VERSION "HNNBNNNYNNNNNNNNNNNNNNNNNNNNNNNNNNNNNNNNNN/4/%%%/4/'%**4NNN///"

NS_ :

BS_:

BU_: A03_ETC C07_BAT H42_HRB H51_STACK H62_HLD E71_DCDC E74_ISOHV S91_FCCU1 S92_FCCU2 S93_FCCU3 S94_FCCU4 S80_BP LABVIEW S83_DCO
VAL_TABLE_ motorState 5 "MOT_numStates" 4 "MOT_RPM_REGULATED" 3 "MOT_PREPARE" 2 "MOT_STOPPED" 1 "MOT_ERROR" 0 "MOT_INIT" ;
VAL_TABLE_ HRB_Status 8 "external operated" 7 "Error" 6 "Heater active" 5 "Blocked" 4 "Running" 3 "Start" 2 "Waiting for start" 1 "Selftest" 0 "Init" ;
VAL_TABLE_ BAT_Status 0 "STANDBY" 1 "SERVICE" 2 "DISCHARGE" 3 "CHARGE" 4 "ERROR" 5 "PRECHARGE_LOAD" 6 "PRECHARGE_CHARGER" 7 "REVERSE_CHARGE" ;
VAL_TABLE_ DCDC_Status 0 "BOOT UP" 4 "STOPPED" 5 "OPERATIONAL" 127 "PRE-OPERATIONAL" ;
VAL_TABLE_ DCDC_Function 1 "Enter Operational" 2 "Enter Stop" 128 "Enter Pre-Operational" 129 "Reset Node" 130 "Reset Communication" ;
VAL_TABLE_ ETC_Status 0 "Initializing" 1 "Ready" 2 "Running" 3 "Degraded Operation" 4 "Blocked" ;
VAL_TABLE_ ETC_Baudrate 1 "20 kbps" 2 "50 kbps" 3 "100 kbps" 4 "125 kbps" 5 "250 kbps" 6 "500 kbps" 8 "1000 kbps" ;
VAL_TABLE_ ETC_Mode 0 "HV Input" 1 "LV Input" ;
VAL_TABLE_ ETC_Info 0 "Article Number" 1 "Article Revision" 2 "SerialNumber Part 1" 3 "SerialNumber Part 2" 4 "SerialNumber Part 3" 5 "Firmware Revision" 6 "Bootloader Version" 255 "Unknown" ;
VAL_TABLE_ ETC_Diag 0 "Gas Bearing Condition" ;
VAL_TABLE_ ISOHV_Cmd 33 "S_IMC_CTL_SELFTEST" 200 "S_VIFC_CTL_IMC_RESET" 202 "S_VIFC_CTL_LOCK" 203 "S_VIFC_CTL_MEASUREMENT" 40 "S_IMC_SET_R_ISO_ERR_THR" 41 "S_IMC_SET_R_ISO_WRN_THR" 43 "S_IMC_SET_MEAN_FACTOR" 210 "S_VIFC_SET_HV_RELAIS" 0 "S_VIFC_DUMMY" 55 "S_IMC_GET_STATUS" 53 "S_IMC_GET_R_ISO" 50 "S_IMC_GET_R_ISO_ERR_THR" 57 "S_IMC_GET_R_ISO_WRN_THR" 60 "S_IMC_GET_MEAN_FACTOR" 54 "S_IMC_GET_HV_1" 58 "S_IMC_GET_HV_2" 51 "S_IMC_GET_VERSION" 220 "S_VIFC_GET_STATUS" 221 "S_VIFC_GET_HV_RELAIS" 222 "S_VIFC_GET_VERSION" 90 "S_IMC_GET_TEST_CNT" 61 "S_IMC_GET_MANUFACTURER" 255 "ERROR" ;
VAL_TABLE_ ISOHV_D_IMC_SELFTEST_SCR 0 "Keine Maßnahme" 1 "OverAll Szenario" 2 "ParameterConfig-Szenario" ;
VAL_TABLE_ ISOHV_D_IMC_R_ISO_BIAS 0 "nicht bekannt" 1 "Fehler an HV1_NEG" 2 "Fehler an HV1_POS" ;
VAL_TABLE_ ISOHV_D_IMC_VERSION_INDEX 0 "IMC Bootloader" 1 "IMC Firmware" 2 "IMC Firmware ID" 3 "IMC Firmware Hash" ;
VAL_TABLE_ ISOHV_D_VIFC_HV_RELAIS 0 "HV_1_NEG-Relais" 1 "HV_1_POS-Relais" 100 "unbekannt" ;
VAL_TABLE_ ISOHV_D_VIFC_LOCK_MODE 0 "Entriegelt" 1 "Verriegelt" 100 "unbekannt" ;
VAL_TABLE_ ISOHV_D_VIFC_LOCK_PWD 0 "Entriegeln" 65535 "Verriegeln" ;
VAL_TABLE_ ISOHV_D_VIFC_HV_RELAIS_STATE 0 "Offen" 1 "Geschlossen" 100 "unbekannt" ;
VAL_TABLE_ ISOHV_D_VIFC_VERSION_INDEX 0 "VIFC-Bootloader" 1 "VIFC-Firmware" 100 "unbekannt" ;
VAL_TABLE_ ISOHV_D_VIFC_IMC_ALIVE 0 "In Betrieb" 1 "Fehler" 2 "Leistungsfehler" 100 "unbekannt" ;
VAL_TABLE_ ISOHV_D_IMD_ERROR_CODE 32 "Timeout 10 ms" 33 "Checksummen-Fehler" 34 "Ungültiger Parameter" 35 "Unbekannter Befehl" 36 "Fehler im EEPROM-Zugang" 37 "Wdh oder fehlender Datenframe" 1000 "Befehl gesperrt" 1001 "Warteschlange voll" 1002 "Befehl nicht verfügbar" 1032 "Timeout 10 ms" 1033 "Checksummen-Fehler" 1034 "Ungültiger Parameter" 1035 "Unbekannter Befehl" 1037 "Wdh oder fehlender Datenframe" 1038 "Keine Antwort" 1039 "Kommunikationsfehler" 1040 "Ungültiger IMC-Antwortbefehl" ;
VAL_TABLE_ RADIATOR_STATUS 0 "Radiator OK" 1 "Radiator ERROR" ;
VAL_TABLE_ STACK_CVM_STATUS 0 "Startup" 16 "Initializing" 32 "Configuration" 48 "Wait for Configuration" 64 "Adressing Slaves" 80 "Idle" 96 "BMS Monitoring Startup" 112 "BMS Monitoring Normal" 240 "Stopped" 254 "Undefined" 255 "Error" ;
VAL_TABLE_ STACK_CONFIG 0 "DateTime" 1 "CoreData_Frequency" 2 "StackSize" 3 "CAN_Resistor" 4 "MasterNo" 5 "Lower_Limit2" 6 "Upper_Limit1" 7 "Upper_Limit2" 8 "Diff_MaxMin_Limit" 9 "AmountOfModules" 10 "CellsPerModule" 11 "PosAtStack" 12 "Temperature" ;
VAL_TABLE_ AIR_THROTTLE 0 "OFF" 1 "ON" 2 "TeachIn" 3 "Error" ;

BO_ 80 A03_FCCU1_ETC_Setpoint: 8 S91_FCCU1
 SG_ A03_ETC_a_opCmd1_Start_Stop : 0|1@0+ (1,0) [0|1] ""  A03_ETC,S83_DCO,LABVIEW
 SG_ A03_ETC_a_opCmd1_Error_Ack : 1|1@0+ (1,0) [0|1] ""  A03_ETC,S83_DCO,LABVIEW
 SG_ A03_ETC_a_opCmd2 : 8|1@0+ (1,0) [0|255] ""  A03_ETC,S83_DCO,LABVIEW
 SG_ A03_ETC_a_Speed_Set : 39|32@0- (1,0) [-2147483648|2147483647] "rpm"  A03_ETC,S83_DCO,LABVIEW

BO_ 84 A03_FCCU1_ETC_CAN_Setting: 8 S91_FCCU1
 SG_ A03_ETC_a_CAN_Set_Broadcast : 0|1@0+ (1,0) [0|1] ""  A03_ETC,S83_DCO,LABVIEW
 SG_ A03_ETC_a_CAN_Set_Termination : 1|1@0+ (1,0) [0|1] ""  A03_ETC,S83_DCO,LABVIEW
 SG_ A03_ETC_a_CAN_Set_Timeout : 2|1@0+ (1,0) [0|1] ""  A03_ETC,S83_DCO,LABVIEW
 SG_ A03_ETC_a_CAN_Set_Timeout_Dur : 15|8@0+ (0.1,0) [0.1|25.5] "s"  A03_ETC,S83_DCO,LABVIEW
 SG_ A03_ETC_a_CAN_Set_Baudrate : 23|8@0+ (1,0) [0|255] ""  A03_ETC,S83_DCO,LABVIEW
 SG_ A03_ETC_a_CAN_Set_ID_Offset : 39|32@0+ (1,0) [1|536869886] ""  A03_ETC,S83_DCO,LABVIEW

BO_ 90 A03_FCCU1_ETC_Info_Rq: 1 S91_FCCU1
 SG_ A03_ETC_a_Info_Rq_Select : 7|8@0+ (1,0) [0|255] ""  A03_ETC,S83_DCO,LABVIEW

BO_ 92 A03_FCCU1_ETC_Diag_Rq: 1 S91_FCCU1
 SG_ A03_ETC_a_Diag_Rq_Select : 7|8@0+ (1,0) [0|255] ""  A03_ETC,S83_DCO,LABVIEW

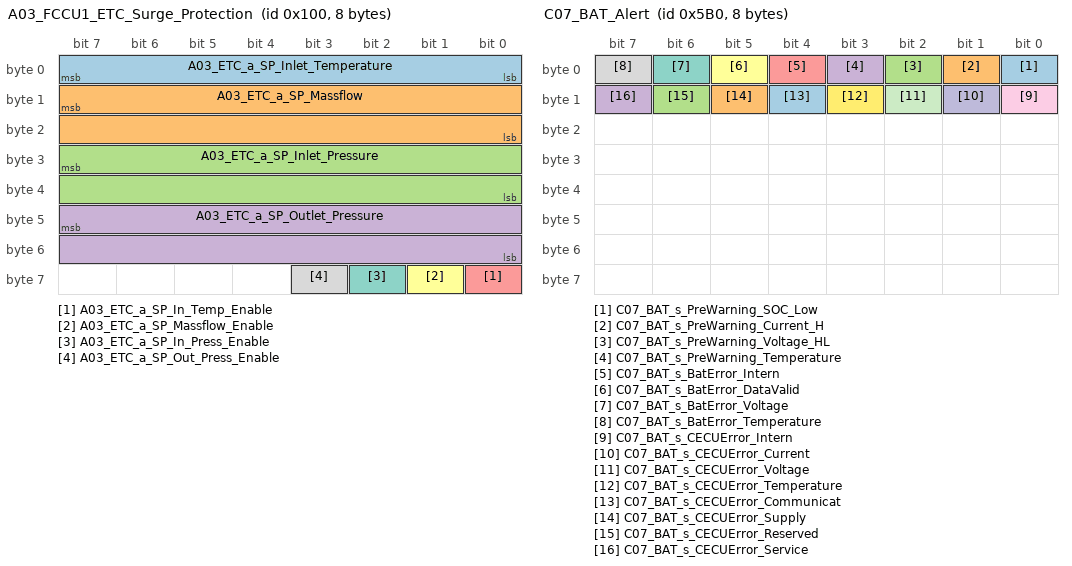
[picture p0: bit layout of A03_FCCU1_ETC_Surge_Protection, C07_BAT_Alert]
BO_ 256 A03_FCCU1_ETC_Surge_Protection: 8 S91_FCCU1
 SG_ A03_ETC_a_SP_Inlet_Temperature : 7|8@0- (1,0) [-128|127] "°C"  A03_ETC,S83_DCO,LABVIEW
 SG_ A03_ETC_a_SP_Massflow : 15|16@0- (1,0) [-32768|32767] "g/s"  A03_ETC,S83_DCO,LABVIEW
 SG_ A03_ETC_a_SP_Inlet_Pressure : 31|16@0+ (0.1,0) [0|6553.5] "kPa"  A03_ETC,S83_DCO,LABVIEW
 SG_ A03_ETC_a_SP_Outlet_Pressure : 47|16@0+ (0.1,0) [0|6553.5] "kPa"  A03_ETC,S83_DCO,LABVIEW
 SG_ A03_ETC_a_SP_In_Temp_Enable : 56|1@0+ (1,0) [0|1] ""  A03_ETC,S83_DCO,LABVIEW
 SG_ A03_ETC_a_SP_Massflow_Enable : 57|1@0+ (1,0) [0|1] ""  A03_ETC,S83_DCO,LABVIEW
 SG_ A03_ETC_a_SP_In_Press_Enable : 58|1@0+ (1,0) [0|1] ""  A03_ETC,S83_DCO,LABVIEW
 SG_ A03_ETC_a_SP_Out_Press_Enable : 59|1@0+ (1,0) [0|1] ""  A03_ETC,S83_DCO,LABVIEW

BO_ 1024 A03_FCCU1_ETC_Param_Rq: 8 S91_FCCU1
 SG_ A03_ETC_a_Param_Rq_Select : 7|8@0+ (1,0) [0|255] ""  A03_ETC,S83_DCO,LABVIEW

BO_ 81 A03_ETC_Status: 8 A03_ETC
 SG_ A03_ETC_s_Status1 : 3|4@0+ (1,0) [0|15] ""  S91_FCCU1,S83_DCO,LABVIEW
 SG_ A03_ETC_s_Status2 : 8|1@0+ (1,0) [0|255] ""  S91_FCCU1,S83_DCO,LABVIEW
 SG_ A03_ETC_s_Speed_Actual : 39|32@0- (1,0) [-2147483648|2147483647] "rpm"  S91_FCCU1,S83_DCO,LABVIEW

BO_ 82 A03_ETC_Info_Warning: 8 A03_ETC
 SG_ A03_ETC_s_Information_Code : 7|32@0+ (1,0) [0|4294967295] ""  S91_FCCU1,S83_DCO,LABVIEW
 SG_ A03_ETC_s_Warning_Code : 39|32@0+ (1,0) [0|4294967295] ""  S91_FCCU1,S83_DCO,LABVIEW

BO_ 83 A03_ETC_Error: 8 A03_ETC
 SG_ A03_ETC_s_Error_Code_1 : 7|32@0+ (1,0) [0|4294967295] ""  S91_FCCU1,S83_DCO,LABVIEW
 SG_ A03_ETC_s_Error_Code_2 : 39|32@0+ (1,0) [0|4294967295] ""  S91_FCCU1,S83_DCO,LABVIEW

BO_ 85 A03_ETC_RPM_I_Meas: 8 A03_ETC
 SG_ A03_ETC_s_Speed_Reference : 7|32@0- (1,0) [-2147483648|2147483647] "rpm"  S91_FCCU1,S83_DCO,LABVIEW
 SG_ A03_ETC_s_Phase_Current : 39|16@0- (0.01,0) [-327.68|327.67] "A"  S91_FCCU1,S83_DCO,LABVIEW
 SG_ A03_ETC_s_Phase_Current_Ref : 55|16@0- (0.01,0) [-327.68|327.67] "A"  S91_FCCU1,S83_DCO,LABVIEW

BO_ 86 A03_ETC_V_POW_Meas: 8 A03_ETC
 SG_ A03_ETC_s_Phase_Voltage : 7|16@0+ (0.1,0) [0|6553.5] "V"  S91_FCCU1,S83_DCO,LABVIEW
 SG_ A03_ETC_s_HV_In_Voltage : 23|16@0+ (0.1,0) [0|6553.5] "V"  S91_FCCU1,S83_DCO,LABVIEW
 SG_ A03_ETC_s_LV_In_Voltage : 39|16@0+ (0.01,0) [0|655.35] "V"  S91_FCCU1,S83_DCO,LABVIEW
 SG_ A03_ETC_s_Output_Power : 55|16@0- (1,0) [-32768|32767] "W"  S91_FCCU1,S83_DCO,LABVIEW

BO_ 87 A03_ETC_Temp_Meas: 6 A03_ETC
 SG_ A03_ETC_s_Converter_Temperature : 7|16@0- (0.1,0) [-3276.8|3276.7] "°C"  S91_FCCU1,S83_DCO,LABVIEW
 SG_ A03_ETC_s_PT100_Temperature : 23|16@0- (0.1,0) [-3276.8|3276.7] "°C"  S91_FCCU1,S83_DCO,LABVIEW

BO_ 91 A03_ETC_Info_Resp: 8 A03_ETC
 SG_ A03_ETC_s_Info_Select M : 7|8@0+ (1,0) [0|255] ""  S91_FCCU1,S83_DCO,LABVIEW

BO_ 93 A03_ETC_Diag_Resp: 8 A03_ETC
 SG_ A03_ETC_s_Diag_Select M : 7|8@0+ (1,0) [0|255] ""  S91_FCCU1,S83_DCO,LABVIEW

BO_ 1025 A03_ETC_Param_Resp: 8 A03_ETC

BO_ 1281 C07_BAT_State: 8 C07_BAT
 SG_ C07_BAT_s_State : 0|8@1+ (1,0) [0|255] ""  S91_FCCU1,S83_DCO,LABVIEW
 SG_ C07_BAT_s_Board_Temperature : 8|8@1- (1,0) [-128|127] "°C"  S91_FCCU1,S83_DCO,LABVIEW
 SG_ C07_BAT_s_System_Current : 16|16@1- (0.1,0) [-3276.8|3276.7] "A"  S91_FCCU1,S83_DCO,LABVIEW
 SG_ C07_BAT_s_Battery_Voltage : 32|32@1+ (0.001,0) [0|4294967.295] "V"  S91_FCCU1,S83_DCO,LABVIEW

BO_ 1282 C07_BAT_Cell_Limit: 8 C07_BAT
 SG_ C07_BAT_s_Max_Cell_Voltage : 0|16@1+ (0.001,0) [0|65.535] "V"  S91_FCCU1,S83_DCO,LABVIEW
 SG_ C07_BAT_s_Min_Cell_Voltage : 16|16@1+ (0.001,0) [0|65.535] "V"  S91_FCCU1,S83_DCO,LABVIEW
 SG_ C07_BAT_s_Max_Cell_Temperature : 32|8@1- (1,0) [-128|127] "°C"  S91_FCCU1,S83_DCO,LABVIEW
 SG_ C07_BAT_s_Min_Cell_Temperature : 40|8@1- (1,0) [-128|127] "°C"  S91_FCCU1,S83_DCO,LABVIEW

BO_ 1283 C07_BAT_SOC_SOH: 2 C07_BAT
 SG_ C_07_BAT_s_SoC : 0|8@1+ (1,0) [0|100] "%"  S91_FCCU1,S83_DCO,LABVIEW
 SG_ C_07_BAT_s_SoH : 8|8@1+ (1,0) [0|100] "%"  S91_FCCU1,S83_DCO,LABVIEW

BO_ 1362 C07_BAT_Voltage: 8 C07_BAT
 SG_ C07_BAT_s_External_Load_Voltage : 0|32@1+ (0.001,0) [0|1000] "V"  S91_FCCU1,S83_DCO,LABVIEW
 SG_ C07_BAT_s_External_Chrg_Voltage : 32|32@1+ (0.001,0) [0|1000] "V"  S91_FCCU1,S83_DCO,LABVIEW

BO_ 1456 C07_BAT_Alert: 8 C07_BAT
 SG_ C07_BAT_s_PreWarning_SOC_Low : 0|1@1+ (1,0) [0|1] ""  S91_FCCU1,S83_DCO,LABVIEW
 SG_ C07_BAT_s_PreWarning_Current_H : 1|1@1+ (1,0) [0|1] ""  S91_FCCU1,S83_DCO,LABVIEW
 SG_ C07_BAT_s_PreWarning_Voltage_HL : 2|1@1+ (1,0) [0|1] ""  S91_FCCU1,S83_DCO,LABVIEW
 SG_ C07_BAT_s_PreWarning_Temperature : 3|1@1+ (1,0) [0|1] ""  S91_FCCU1,S83_DCO,LABVIEW
 SG_ C07_BAT_s_BatError_Intern : 4|1@1+ (1,0) [0|1] ""  S91_FCCU1,S83_DCO,LABVIEW
 SG_ C07_BAT_s_BatError_DataValid : 5|1@1+ (1,0) [0|1] ""  S91_FCCU1,S83_DCO,LABVIEW
 SG_ C07_BAT_s_BatError_Voltage : 6|1@1+ (1,0) [0|1] ""  S91_FCCU1,S83_DCO,LABVIEW
 SG_ C07_BAT_s_BatError_Temperature : 7|1@1+ (1,0) [0|1] ""  S91_FCCU1,S83_DCO,LABVIEW
 SG_ C07_BAT_s_CECUError_Intern : 8|1@1+ (1,0) [0|1] ""  S91_FCCU1,S83_DCO,LABVIEW
 SG_ C07_BAT_s_CECUError_Current : 9|1@1+ (1,0) [0|1] ""  S91_FCCU1,S83_DCO,LABVIEW
 SG_ C07_BAT_s_CECUError_Voltage : 10|1@1+ (1,0) [0|1] ""  S91_FCCU1,S83_DCO,LABVIEW
 SG_ C07_BAT_s_CECUError_Temperature : 11|1@1+ (1,0) [0|1] ""  S91_FCCU1,S83_DCO,LABVIEW
 SG_ C07_BAT_s_CECUError_Communicat : 12|1@1+ (1,0) [0|1] ""  S91_FCCU1,S83_DCO,LABVIEW
 SG_ C07_BAT_s_CECUError_Supply : 13|1@1+ (1,0) [0|1] ""  S91_FCCU1,S83_DCO,LABVIEW
 SG_ C07_BAT_s_CECUError_Reserved : 14|1@1+ (1,0) [0|1] ""  S91_FCCU1,S83_DCO,LABVIEW
 SG_ C07_BAT_s_CECUError_Service : 15|1@1+ (1,0) [0|1] ""  S91_FCCU1,S83_DCO,LABVIEW

BO_ 528 H42_FCCU1_HRB_FCCU_Rq: 8 S91_FCCU1
 SG_ H42_HRB_a_FCCU_CRC : 0|8@1+ (1,0) [0|255] ""  H42_HRB,S83_DCO,LABVIEW
 SG_ H42_HRB_a_FCCU_SQC : 8|4@1+ (1,0) [0|15] ""  H42_HRB,S83_DCO,LABVIEW
 SG_ H42_HRB_a_FCCU_Spd_Rq : 16|16@1+ (1,0) [0|25000] "rpm"  H42_HRB,S83_DCO,LABVIEW
 SG_ H42_HRB_a_FCCU_Heating_Rq : 32|8@1+ (1,-60) [-60|195] ""  H42_HRB,S83_DCO,LABVIEW

BO_ 629 H42_HRB_ARB_Stat: 8 H42_HRB
 SG_ H42_HRB_s_ARB_ECU_Temp : 0|8@1+ (1,-60) [-60|195] "°C"  S91_FCCU1,S83_DCO,LABVIEW
 SG_ H42_HRB_s_ARB_Batt_Voltage : 8|10@1+ (0.1,0) [0|102.3] "V"  S91_FCCU1,S83_DCO,LABVIEW
 SG_ H42_HRB_s_ARB_SysState : 18|6@1+ (1,0) [0|63] ""  S91_FCCU1,S83_DCO,LABVIEW
 SG_ H42_HRB_s_ARB_Spd : 24|16@1+ (1,0) [0|25000] "rpm"  S91_FCCU1,S83_DCO,LABVIEW
 SG_ H42_HRB_s_ARB_ECU_P_out : 40|10@1+ (1,0) [0|1023] "W"  S91_FCCU1,S83_DCO,LABVIEW

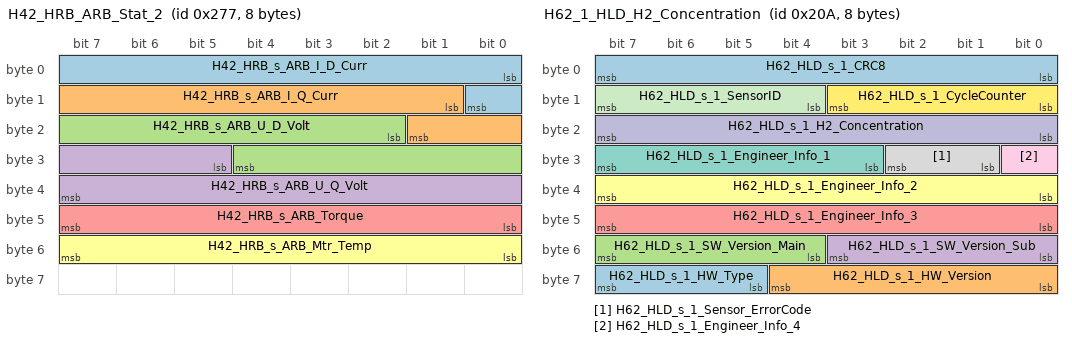
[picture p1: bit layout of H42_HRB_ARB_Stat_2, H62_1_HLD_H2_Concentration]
BO_ 631 H42_HRB_ARB_Stat_2: 8 H42_HRB
 SG_ H42_HRB_s_ARB_I_D_Curr : 0|9@1+ (0.5,-110) [-110|145.5] "A"  S91_FCCU1,S83_DCO,LABVIEW
 SG_ H42_HRB_s_ARB_I_Q_Curr : 9|9@1+ (0.5,-110) [-110|145.5] "A"  S91_FCCU1,S83_DCO,LABVIEW
 SG_ H42_HRB_s_ARB_U_D_Volt : 18|11@1+ (0.01,-10) [-10|10.47] "V"  S91_FCCU1,S83_DCO,LABVIEW
 SG_ H42_HRB_s_ARB_U_Q_Volt : 29|11@1+ (0.01,-10) [-10|10.47] "V"  S91_FCCU1,S83_DCO,LABVIEW
 SG_ H42_HRB_s_ARB_Torque : 40|8@1+ (0.0025,-0.3) [-0.3|0.3375] "Nm"  S91_FCCU1,S83_DCO,LABVIEW
 SG_ H42_HRB_s_ARB_Mtr_Temp : 48|8@1+ (1,-60) [-60|195] "°C"  S91_FCCU1,S83_DCO,LABVIEW

BO_ 640 H42_HRB_ARB_ErrFlgs: 8 H42_HRB
 SG_ H42_HRB_s_ARB_ErrCRC : 0|8@1+ (1,0) [0|255] ""  S91_FCCU1,S83_DCO,LABVIEW
 SG_ H42_HRB_s_ARB_ErrSQC : 8|4@1+ (1,0) [0|15] ""  S91_FCCU1,S83_DCO,LABVIEW
 SG_ H42_HRB_s_ARB_E2E_Err : 12|3@1+ (1,0) [0|7] ""  S91_FCCU1,S83_DCO,LABVIEW
 SG_ H42_HRB_s_ARB_SpdLimitRq_Err : 15|1@1+ (1,0) [0|1] ""  S91_FCCU1,S83_DCO,LABVIEW
 SG_ H42_HRB_s_ARB_SpdDiff_DrCnd : 16|2@1+ (1,0) [0|3] ""  S91_FCCU1,S83_DCO,LABVIEW
 SG_ H42_HRB_s_ARB_Batt_Vltg_Err : 18|2@1+ (1,0) [0|3] ""  S91_FCCU1,S83_DCO,LABVIEW
 SG_ H42_HRB_s_ARB_Blocked_Err : 20|1@1+ (1,0) [0|1] ""  S91_FCCU1,S83_DCO,LABVIEW
 SG_ H42_HRB_s_ARB_Init_Err : 21|1@1+ (1,0) [0|1] ""  S91_FCCU1,S83_DCO,LABVIEW
 SG_ H42_HRB_s_ARB_ShortToBat_Err : 22|1@1+ (1,0) [0|1] ""  S91_FCCU1,S83_DCO,LABVIEW
 SG_ H42_HRB_s_ARB_ShortToGround_Err : 23|1@1+ (1,0) [0|1] ""  S91_FCCU1,S83_DCO,LABVIEW
 SG_ H42_HRB_s_ARB_BrdgDrv_Err : 24|8@1+ (1,0) [0|255] ""  S91_FCCU1,S83_DCO,LABVIEW
 SG_ H42_HRB_s_BrdgDrv_VCC_UV_Err : 32|1@1+ (1,0) [0|1] ""  S91_FCCU1,S83_DCO,LABVIEW
 SG_ H42_HRB_s_ARB_ECU_Temp_DrCnd : 33|2@1+ (1,0) [0|3] ""  S91_FCCU1,S83_DCO,LABVIEW
 SG_ H42_HRB_s_ARB_ECU_Temp_Err : 35|2@1+ (1,0) [0|3] ""  S91_FCCU1,S83_DCO,LABVIEW
 SG_ H42_HRB_s_ARB_Mtr_Temp_DrCnd : 37|2@1+ (1,0) [0|3] ""  S91_FCCU1,S83_DCO,LABVIEW
 SG_ H42_HRB_s_ARB_Mtr_Temp_Err : 39|2@1+ (1,0) [0|3] ""  S91_FCCU1,S83_DCO,LABVIEW
 SG_ H42_HRB_s_ARB_MtrNTCFlr_DrCnd : 41|1@1+ (1,0) [0|1] ""  S91_FCCU1,S83_DCO,LABVIEW

BO_ 2147487745 H51_FCCU1_STACK_Data_Rq_to_CVM: 8 S91_FCCU1
 SG_ H51_STK_a_DataLength_1001 : 0|8@1+ (1,0) [0|255] ""  H51_STACK,S83_DCO,LABVIEW
 SG_ H51_STK_a_ID_L_1001 M : 16|8@1+ (1,0) [0|255] ""  H51_STACK,S83_DCO,LABVIEW
 SG_ H51_STK_a_ID_H_1001 : 8|8@1+ (1,0) [0|255] ""  H51_STACK,S83_DCO,LABVIEW
 SG_ H51_STK_a_CellVoltage_1001 m0 : 24|8@1+ (1,0) [0|255] ""  H51_STACK,S83_DCO,LABVIEW
 SG_ H51_STK_a_Logdata_1001 m0 : 48|8@1+ (1,0) [0|255] ""  H51_STACK,S83_DCO,LABVIEW
 SG_ H51_STK_a_CoreData_1001 m0 : 32|1@1+ (1,0) [0|1] ""  H51_STACK,S83_DCO,LABVIEW
 SG_ H51_STK_a_Firmware_1001 m0 : 40|1@1+ (1,0) [0|1] ""  H51_STACK,S83_DCO,LABVIEW

BO_ 2147487746 H51_FCCU1_STACK_Configuration: 8 S91_FCCU1
 SG_ H51_STK_a_DataLength_1002 : 0|8@1+ (1,0) [0|255] ""  H51_STACK,S83_DCO,LABVIEW
 SG_ H51_STK_a_ID_H_1002 : 8|8@1+ (1,0) [0|255] ""  H51_STACK,S83_DCO,LABVIEW
 SG_ H51_STK_a_ID_L_1002 M : 16|8@1+ (1,0) [0|255] ""  H51_STACK,S83_DCO,LABVIEW
 SG_ H51_STK_a_DateTime_1002 m0 : 31|32@0+ (1,0) [0|4294967295] ""  H51_STACK,S83_DCO,LABVIEW
 SG_ H51_STK_a_CoreData_Freq_1002 m1 : 24|8@1+ (1,0) [0|255] "Hz"  H51_STACK,S83_DCO,LABVIEW
 SG_ H51_STK_a_StackSize_1002 m2 : 31|16@0+ (1,0) [0|65535] "Zellen"  H51_STACK,S83_DCO,LABVIEW
 SG_ H51_STK_a_CAN_TerminatRes_1002 m3 : 24|1@1+ (1,0) [0|1] ""  H51_STACK,S83_DCO,LABVIEW
 SG_ H51_STK_a_MasterNo_1002 m4 : 24|8@1+ (1,0) [0|255] ""  H51_STACK,S83_DCO,LABVIEW
 SG_ H51_STK_a_Lower_Limit2_1002 m5 : 31|16@0+ (1,0) [0|65535] "mV"  H51_STACK,S83_DCO,LABVIEW
 SG_ H51_STK_a_Upper_Limit1_1002 m6 : 31|16@0+ (1,0) [0|65535] "mV"  H51_STACK,S83_DCO,LABVIEW
 SG_ H51_STK_a_UpperLimit2_1002 m7 : 31|16@0+ (1,0) [0|65535] "mV"  H51_STACK,S83_DCO,LABVIEW
 SG_ H51_STK_a_Diff_MaxMin_limit_1002 m8 : 31|16@0+ (1,0) [0|65535] ""  H51_STACK,S83_DCO,LABVIEW
 SG_ H51_STK_a_AmountOfModules_1002 m9 : 24|8@1+ (1,0) [0|255] "St."  H51_STACK,S83_DCO,LABVIEW
 SG_ H51_STK_a_CellsPerModule_1002 m10 : 24|8@1+ (1,0) [0|255] ""  H51_STACK,S83_DCO,LABVIEW
 SG_ H51_STK_a_PosAtStack_1002 m11 : 24|8@1+ (1,0) [0|255] "Pos."  H51_STACK,S83_DCO,LABVIEW
 SG_ H51_STK_a_Temperature_1002 m12 : 31|16@0+ (1,0) [0|65535] ""  H51_STACK,S83_DCO,LABVIEW

BO_ 2147487747 H51_FCCU1_STACK_MonitorFlags: 4 S91_FCCU1
 SG_ H51_STK_a_Monitoring_Flag_1003 : 24|3@1+ (1,0) [0|7] ""  H51_STACK,S83_DCO,LABVIEW
 SG_ H51_STK_a_DataLength_1003 : 0|8@1+ (1,0) [0|255] ""  H51_STACK,S83_DCO,LABVIEW
 SG_ H51_STK_a_ID_1003 : 15|16@0+ (1,0) [0|65535] ""  H51_STACK,S83_DCO,LABVIEW

BO_ 2147487748 H51_FCCU1_STACK_Command: 8 S91_FCCU1
 SG_ H51_STK_a_Command_1004 : 24|8@1+ (1,0) [0|255] ""  H51_STACK,S83_DCO,LABVIEW
 SG_ H51_STK_a_ID_1004 : 15|16@0+ (1,0) [0|65535] ""  H51_STACK,S83_DCO,LABVIEW
 SG_ H51_STK_a_DataLength_1004 : 0|8@1+ (1,0) [0|3] ""  H51_STACK,S83_DCO,LABVIEW

BO_ 2147487750 H51_FCCU1_STACK_Resp: 8 S91_FCCU1
 SG_ H51_STK_a_DataLength_1006 : 0|8@1+ (1,0) [0|255] ""  H51_STACK,S83_DCO,LABVIEW
 SG_ H51_STK_a_FCCUResponse_1006 : 24|8@1+ (1,0) [0|255] ""  H51_STACK,S83_DCO,LABVIEW

BO_ 2147487755 H51_FCCU1_STACK_Bootloader: 8 S91_FCCU1
 SG_ H51_STK_a_DataLength_100B : 0|8@1+ (1,0) [0|255] ""  H51_STACK,S83_DCO,LABVIEW
 SG_ H51_STK_a_ID_H_100B : 8|8@1+ (1,0) [0|255] ""  H51_STACK,S83_DCO,LABVIEW
 SG_ H51_STK_a_ID_L_100B : 16|8@1+ (1,0) [0|255] ""  H51_STACK,S83_DCO,LABVIEW
 SG_ H51_STK_a_Modul_100B : 24|8@1+ (1,0) [0|255] ""  H51_STACK,S83_DCO,LABVIEW

BO_ 2147491840 H51_STACK_CVM_Status: 8 H51_STACK
 SG_ H51_STK_s_Watchdog_2000 : 40|8@1+ (1,0) [0|255] ""  S91_FCCU1,S83_DCO,LABVIEW
 SG_ H51_STK_s_DataLength_2000 : 0|8@1+ (1,0) [0|255] ""  S91_FCCU1,S83_DCO,LABVIEW
 SG_ H51_STK_s_Amount_Slave_Modu_2000 : 32|8@1+ (1,0) [0|255] "St."  S91_FCCU1,S83_DCO,LABVIEW
 SG_ H51_STK_s_Stat_CVM_Mastermo_2000 : 24|8@1+ (1,0) [0|255] ""  S91_FCCU1,S83_DCO,LABVIEW
 SG_ H51_STK_s_ID_L_2000 : 16|8@1+ (1,0) [0|255] ""  S91_FCCU1,S83_DCO,LABVIEW
 SG_ H51_STK_s_ID_H_2000 : 8|8@1+ (1,0) [0|255] ""  S91_FCCU1,S83_DCO,LABVIEW

BO_ 2147491841 H51_STACK_Date_Time_Rq: 5 H51_STACK
 SG_ H51_STK_s_Datalength_2001 : 0|8@1+ (1,0) [0|3] ""  S91_FCCU1,S83_DCO,LABVIEW
 SG_ H51_STK_s_ID_2001 : 15|16@0+ (1,0) [0|65535] ""  S91_FCCU1,S83_DCO,LABVIEW
 SG_ H51_STK_s_RequestBit_2001 : 24|1@1+ (1,0) [0|1] ""  S91_FCCU1,S83_DCO,LABVIEW

BO_ 2147491842 H51_STACK_CVM_Firmware: 8 H51_STACK
 SG_ H51_STK_s_FrameMux_2002 M : 7|8@0+ (1,0) [0|255] ""  S91_FCCU1,S83_DCO,LABVIEW
 SG_ H51_STK_s_AmountOfFrames_2002 m16 : 8|8@1+ (1,0) [0|255] ""  S91_FCCU1,S83_DCO,LABVIEW
 SG_ H51_STK_s_ID_H_2002 m16 : 23|8@0+ (1,0) [0|255] ""  S91_FCCU1,S83_DCO,LABVIEW
 SG_ H51_STK_s_ID_L_2002 m16 : 24|8@1+ (1,0) [0|255] ""  S91_FCCU1,S83_DCO,LABVIEW
 SG_ H51_STK_s_CVM_Firmw_Master_2002 m16 : 32|8@1+ (1,0) [0|255] ""  S91_FCCU1,S83_DCO,LABVIEW
 SG_ H51_STK_s_CVM_Firmw_Slave1_2002 m16 : 40|8@1+ (1,0) [0|255] ""  S91_FCCU1,S83_DCO,LABVIEW
 SG_ H51_STK_s_CVM_Firmw_Slave2_2002 m16 : 48|8@1+ (1,0) [0|255] ""  S91_FCCU1,S83_DCO,LABVIEW
 SG_ H51_STK_s_CVM_Firmw_Slave3_2002 m16 : 56|8@1+ (1,0) [0|255] ""  S91_FCCU1,S83_DCO,LABVIEW
 SG_ H51_STK_s_CVM_Firmw_Slave4_2002 m33 : 15|8@0+ (1,0) [0|255] ""  S91_FCCU1,S83_DCO,LABVIEW
 SG_ H51_STK_s_CVM_Firmw_Slave5_2002 m33 : 16|8@1+ (1,0) [0|255] ""  S91_FCCU1,S83_DCO,LABVIEW
 SG_ H51_STK_s_CVM_Firmw_Slave6_2002 m33 : 24|8@1+ (1,0) [0|255] ""  S91_FCCU1,S83_DCO,LABVIEW
 SG_ H51_STK_s_CVM_Firmw_Slave7_2002 m33 : 32|8@1+ (1,0) [0|255] ""  S91_FCCU1,S83_DCO,LABVIEW
 SG_ H51_STK_s_CVM_Firmw_Slave8_2002 m33 : 40|8@1+ (1,0) [0|255] ""  S91_FCCU1,S83_DCO,LABVIEW
 SG_ H51_STK_s_CVM_Firmw_Slave9_2002 m33 : 48|8@1+ (1,0) [0|255] ""  S91_FCCU1,S83_DCO,LABVIEW
 SG_ H51_STK_s_CVM_Firmw_Slave10_2002 m33 : 56|8@1+ (1,0) [0|255] ""  S91_FCCU1,S83_DCO,LABVIEW
 SG_ H51_STK_s_CVM_Firmw_Slave11_2002 m34 : 8|8@1+ (1,0) [0|255] ""  S91_FCCU1,S83_DCO,LABVIEW
 SG_ H51_STK_s_CVM_Firmw_Slave12_2002 m34 : 16|8@1+ (1,0) [0|255] ""  S91_FCCU1,S83_DCO,LABVIEW
 SG_ H51_STK_s_CVM_Firmw_Slave13_2002 m34 : 24|8@1+ (1,0) [0|255] ""  S91_FCCU1,S83_DCO,LABVIEW
 SG_ H51_STK_s_CVM_Firmw_Slave14_2002 m34 : 32|8@1+ (1,0) [0|255] ""  S91_FCCU1,S83_DCO,LABVIEW
 SG_ H51_STK_s_CVM_Firmw_Slave15_2002 m34 : 40|8@1+ (1,0) [0|255] ""  S91_FCCU1,S83_DCO,LABVIEW
 SG_ H51_STK_s_CVM_Firmw_Slave16_2002 m34 : 48|8@1+ (1,0) [0|255] ""  S91_FCCU1,S83_DCO,LABVIEW
 SG_ H51_STK_s_CVM_Firmw_Slave17_2002 m34 : 56|8@1+ (1,0) [0|255] ""  S91_FCCU1,S83_DCO,LABVIEW
 SG_ H51_STK_s_CVM_Firmw_Slave18_2002 m35 : 8|8@1+ (1,0) [0|255] ""  S91_FCCU1,S83_DCO,LABVIEW
 SG_ H51_STK_s_CVM_Firmw_Slave19_2002 m35 : 16|8@1+ (1,0) [0|255] ""  S91_FCCU1,S83_DCO,LABVIEW
 SG_ H51_STK_s_CVM_Firmw_Slave20_2002 m35 : 24|8@1+ (1,0) [0|255] ""  S91_FCCU1,S83_DCO,LABVIEW
 SG_ H51_STK_s_CVM_Firmw_Slave21_2002 m35 : 32|8@1+ (1,0) [0|255] ""  S91_FCCU1,S83_DCO,LABVIEW
 SG_ H51_STK_s_CVM_Firmw_Slave22_2002 m35 : 40|8@1+ (1,0) [0|255] ""  S91_FCCU1,S83_DCO,LABVIEW
 SG_ H51_STK_s_CVM_Firmw_Slave23_2002 m35 : 48|8@1+ (1,0) [0|255] ""  S91_FCCU1,S83_DCO,LABVIEW
 SG_ H51_STK_s_CVM_Firmw_Slave24_2002 m35 : 56|8@1+ (1,0) [0|255] ""  S91_FCCU1,S83_DCO,LABVIEW

BO_ 2147491843 H51_STACK_Core_Data: 8 H51_STACK
 SG_ H51_STK_s_FrameMux_2003 M : 7|8@0+ (1,0) [0|255] ""  S91_FCCU1,S83_DCO,LABVIEW
 SG_ H51_STK_s_AmountOfFrames_2003 m16 : 15|8@0+ (1,0) [0|255] ""  S91_FCCU1,S83_DCO,LABVIEW
 SG_ H51_STK_s_CellNo_lowest_2003 m16 : 23|12@0+ (1,0) [1|500] "Zelle"  S91_FCCU1,S83_DCO,LABVIEW
 SG_ H51_STK_s_CellVolt_lowest_2003 m16 : 27|12@0+ (1,0) [0|1200] "mV"  S91_FCCU1,S83_DCO,LABVIEW
 SG_ H51_STK_s_CellVolt_prev_lowest m16 : 47|12@0+ (1,0) [0|1500] "mV"  S91_FCCU1,S83_DCO,LABVIEW
 SG_ H51_STK_s_CellVolt_follow_lowest m16 : 51|12@0+ (1,0) [0|1200] "mV"  S91_FCCU1,S83_DCO,LABVIEW
 SG_ H51_STK_s_ModulNr_HighestTemp m33 : 8|8@1+ (1,0) [0|255] ""  S91_FCCU1,S83_DCO,LABVIEW
 SG_ H51_STK_s_CellNo_2ndlow_2003 m33 : 23|12@0+ (1,0) [1|600] "Zelle"  S91_FCCU1,S83_DCO,LABVIEW
 SG_ H51_STK_s_CellVolt_2ndlow_2003 m33 : 27|12@0+ (1,0) [0|1500] "mV"  S91_FCCU1,S83_DCO,LABVIEW
 SG_ H51_STK_s_CellVolt_prev_2ndlow m33 : 47|12@0+ (1,0) [0|1200] "mV"  S91_FCCU1,S83_DCO,LABVIEW
 SG_ H51_STK_s_CellVolt_follow_2ndlow m33 : 51|12@0+ (1,0) [0|1200] "mV"  S91_FCCU1,S83_DCO,LABVIEW
 SG_ H51_STK_s_ModulHighestTemp_2003 m34 : 8|8@1- (1,0) [-128|127] ""  S91_FCCU1,S83_DCO,LABVIEW
 SG_ H51_STK_s_CellNo_highest_2003 m34 : 23|12@0+ (1,0) [1|500] "Zelle"  S91_FCCU1,S83_DCO,LABVIEW
 SG_ H51_STK_s_CellVolt_highest_2003 m34 : 27|12@0+ (1,0) [0|1500] "mV"  S91_FCCU1,S83_DCO,LABVIEW
 SG_ H51_STK_s_TotalVoltage_2003 m34 : 47|24@0+ (1,0) [0|600000] "mV"  S91_FCCU1,S83_DCO,LABVIEW

BO_ 2147491844 H51_STACK_Event_Data: 8 H51_STACK
 SG_ H51_STK_s_Mux_ID_2004 M : 7|8@0+ (1,0) [0|255] ""  S91_FCCU1,S83_DCO,LABVIEW
 SG_ H51_STK_s_Datalength_2004 m16 : 3|12@0+ (1,0) [1|4095] ""  S91_FCCU1,S83_DCO,LABVIEW
 SG_ H51_STK_s_AverageTemp_2004 m33 : 23|16@0+ (1,0) [0|65535] "°C"  S91_FCCU1,S83_DCO,LABVIEW
 SG_ H51_STK_s_EventNo_2004 m16 : 39|8@0+ (1,0) [0|255] ""  S91_FCCU1,S83_DCO,LABVIEW
 SG_ H51_STK_s_ZellNo_2004 m16 : 47|16@0+ (1,0) [0|65535] ""  S91_FCCU1,S83_DCO,LABVIEW
 SG_ H51_STK_s_CellVoltage_ui16H_2004 m33 : 15|8@0+ (1,0) [0|255] "mV"  S91_FCCU1,S83_DCO,LABVIEW
 SG_ H51_STK_s_CellVoltage_ui16L_2004 m16 : 63|8@0+ (1,0) [0|65535] "mV"  S91_FCCU1,S83_DCO,LABVIEW

BO_ 2147491845 H51_STACK_Cell_Voltages: 8 H51_STACK
 SG_ H51_STK_s_FrameMux_2005 M : 0|8@1+ (1,0) [0|255] ""  S91_FCCU1,S83_DCO,LABVIEW
 SG_ H51_STK_s_AmountOfFrames_2005 m16 : 15|8@0+ (1,0) [1|4095] ""  S91_FCCU1,S83_DCO,LABVIEW
 SG_ H51_STK_s_CellVolt_071_2005 m49 : 47|12@0+ (1,0) [0|1500] "mV"  S91_FCCU1,S83_DCO,LABVIEW
 SG_ H51_STK_s_CellVolt_070_2005 m49 : 27|12@0+ (1,0) [0|1500] "mV"  S91_FCCU1,S83_DCO,LABVIEW
 SG_ H51_STK_s_CellVolt_069_2005 m49 : 23|12@0+ (1,0) [0|1500] "mV"  S91_FCCU1,S83_DCO,LABVIEW
 SG_ H51_STK_s_CellVolt_068_2005 m48 : 51|12@0+ (1,0) [0|1500] "mV"  S91_FCCU1,S83_DCO,LABVIEW
 SG_ H51_STK_s_CellVolt_067_2005 m48 : 47|12@0+ (1,0) [0|1500] "mV"  S91_FCCU1,S83_DCO,LABVIEW
 SG_ H51_STK_s_CellVolt_066_2005 m48 : 27|12@0+ (1,0) [0|1500] "mV"  S91_FCCU1,S83_DCO,LABVIEW
 SG_ H51_STK_s_CellVolt_065_2005 m48 : 23|12@0+ (1,0) [0|1500] "mV"  S91_FCCU1,S83_DCO,LABVIEW
 SG_ H51_STK_s_CellVolt_064_2005 m47 : 51|12@0+ (1,0) [0|1500] "mV"  S91_FCCU1,S83_DCO,LABVIEW
 SG_ H51_STK_s_CellVolt_063_2005 m47 : 47|12@0+ (1,0) [0|1500] "mV"  S91_FCCU1,S83_DCO,LABVIEW
 SG_ H51_STK_s_CellVolt_062_2005 m47 : 27|12@0+ (1,0) [0|1500] "mV"  S91_FCCU1,S83_DCO,LABVIEW
 SG_ H51_STK_s_CellVolt_061_2005 m47 : 23|12@0+ (1,0) [0|1500] "mV"  S91_FCCU1,S83_DCO,LABVIEW
 SG_ H51_STK_s_CellVolt_060_2005 m46 : 51|12@0+ (1,0) [0|1500] "mV"  S91_FCCU1,S83_DCO,LABVIEW
 SG_ H51_STK_s_CellVolt_059_2005 m46 : 47|12@0+ (1,0) [0|1500] "mV"  S91_FCCU1,S83_DCO,LABVIEW
 SG_ H51_STK_s_CellVolt_058_2005 m46 : 27|12@0+ (1,0) [0|1500] "mV"  S91_FCCU1,S83_DCO,LABVIEW
 SG_ H51_STK_s_CellVolt_057_2005 m46 : 23|12@0+ (1,0) [0|1500] "mV"  S91_FCCU1,S83_DCO,LABVIEW
 SG_ H51_STK_s_CellVolt_056_2005 m45 : 51|12@0+ (1,0) [0|1500] "mV"  S91_FCCU1,S83_DCO,LABVIEW
 SG_ H51_STK_s_CellVolt_055_2005 m45 : 47|12@0+ (1,0) [0|1500] "mV"  S91_FCCU1,S83_DCO,LABVIEW
 SG_ H51_STK_s_CellVolt_054_2005 m45 : 27|12@0+ (1,0) [0|1500] "mV"  S91_FCCU1,S83_DCO,LABVIEW
 SG_ H51_STK_s_CellVolt_053_2005 m45 : 23|12@0+ (1,0) [0|1500] "mV"  S91_FCCU1,S83_DCO,LABVIEW
 SG_ H51_STK_s_CellVolt_052_2005 m44 : 51|12@0+ (1,0) [0|1500] "mV"  S91_FCCU1,S83_DCO,LABVIEW
 SG_ H51_STK_s_CellVolt_051_2005 m44 : 47|12@0+ (1,0) [0|1500] "mV"  S91_FCCU1,S83_DCO,LABVIEW
 SG_ H51_STK_s_CellVolt_050_2005 m44 : 27|12@0+ (1,0) [0|1500] "mV"  S91_FCCU1,S83_DCO,LABVIEW
 SG_ H51_STK_s_CellVolt_049_2005 m44 : 23|12@0+ (1,0) [0|1500] "mV"  S91_FCCU1,S83_DCO,LABVIEW
 SG_ H51_STK_s_CellVolt_048_2005 m43 : 51|12@0+ (1,0) [0|1500] "mV"  S91_FCCU1,S83_DCO,LABVIEW
 SG_ H51_STK_s_CellVolt_047_2005 m43 : 47|12@0+ (1,0) [0|1500] "mV"  S91_FCCU1,S83_DCO,LABVIEW
 SG_ H51_STK_s_CellVolt_046_2005 m43 : 27|12@0+ (1,0) [0|1500] "mV"  S91_FCCU1,S83_DCO,LABVIEW
 SG_ H51_STK_s_CellVolt_045_2005 m43 : 23|12@0+ (1,0) [0|1500] "mV"  S91_FCCU1,S83_DCO,LABVIEW
 SG_ H51_STK_s_CellVolt_044_2005 m42 : 51|12@0+ (1,0) [0|1500] "mV"  S91_FCCU1,S83_DCO,LABVIEW
 SG_ H51_STK_s_CellVolt_043_2005 m42 : 47|12@0+ (1,0) [0|1500] "mV"  S91_FCCU1,S83_DCO,LABVIEW
 SG_ H51_STK_s_CellVolt_042_2005 m42 : 27|12@0+ (1,0) [0|1500] "mV"  S91_FCCU1,S83_DCO,LABVIEW
 SG_ H51_STK_s_CellVolt_041_2005 m42 : 23|12@0+ (1,0) [0|1500] "mV"  S91_FCCU1,S83_DCO,LABVIEW
 SG_ H51_STK_s_CellVolt_040_2005 m41 : 51|12@0+ (1,0) [0|1500] "mV"  S91_FCCU1,S83_DCO,LABVIEW
 SG_ H51_STK_s_CellVolt_039_2005 m41 : 47|12@0+ (1,0) [0|1500] "mV"  S91_FCCU1,S83_DCO,LABVIEW
 SG_ H51_STK_s_CellVolt_038_2005 m41 : 27|12@0+ (1,0) [0|1500] "mV"  S91_FCCU1,S83_DCO,LABVIEW
 SG_ H51_STK_s_CellVolt_037_2005 m41 : 23|12@0+ (1,0) [0|1500] "mV"  S91_FCCU1,S83_DCO,LABVIEW
 SG_ H51_STK_s_CellVolt_036_2005 m40 : 51|12@0+ (1,0) [0|1500] "mV"  S91_FCCU1,S83_DCO,LABVIEW
 SG_ H51_STK_s_CellVolt_035_2005 m40 : 47|12@0+ (1,0) [0|1500] "mV"  S91_FCCU1,S83_DCO,LABVIEW
 SG_ H51_STK_s_CellVolt_034_2005 m40 : 27|12@0+ (1,0) [0|1500] "mV"  S91_FCCU1,S83_DCO,LABVIEW
 SG_ H51_STK_s_CellVolt_033_2005 m40 : 23|12@0+ (1,0) [0|1500] "mV"  S91_FCCU1,S83_DCO,LABVIEW
 SG_ H51_STK_s_CellVolt_032_2005 m39 : 51|12@0+ (1,0) [0|1500] "mV"  S91_FCCU1,S83_DCO,LABVIEW
 SG_ H51_STK_s_CellVolt_031_2005 m39 : 47|12@0+ (1,0) [0|1500] "mV"  S91_FCCU1,S83_DCO,LABVIEW
 SG_ H51_STK_s_CellVolt_030_2005 m39 : 27|12@0+ (1,0) [0|1500] "mV"  S91_FCCU1,S83_DCO,LABVIEW
 SG_ H51_STK_s_CellVolt_029_2005 m39 : 23|12@0+ (1,0) [0|1500] "mV"  S91_FCCU1,S83_DCO,LABVIEW
 SG_ H51_STK_s_CellVolt_028_2005 m38 : 51|12@0+ (1,0) [0|1500] "mV"  S91_FCCU1,S83_DCO,LABVIEW
 SG_ H51_STK_s_CellVolt_027_2005 m38 : 47|12@0+ (1,0) [0|1500] "mV"  S91_FCCU1,S83_DCO,LABVIEW
 SG_ H51_STK_s_CellVolt_026_2005 m38 : 27|12@0+ (1,0) [0|1500] "mV"  S91_FCCU1,S83_DCO,LABVIEW
 SG_ H51_STK_s_CellVolt_025_2005 m38 : 23|12@0+ (1,0) [0|1500] "mV"  S91_FCCU1,S83_DCO,LABVIEW
 SG_ H51_STK_s_CellVolt_024_2005 m37 : 51|12@0+ (1,0) [0|1500] "mV"  S91_FCCU1,S83_DCO,LABVIEW
 SG_ H51_STK_s_CellVolt_023_2005 m37 : 47|12@0+ (1,0) [0|1500] "mV"  S91_FCCU1,S83_DCO,LABVIEW
 SG_ H51_STK_s_CellVolt_022_2005 m37 : 27|12@0+ (1,0) [0|1500] "mV"  S91_FCCU1,S83_DCO,LABVIEW
 SG_ H51_STK_s_CellVolt_021_2005 m37 : 23|12@0+ (1,0) [0|1500] "mV"  S91_FCCU1,S83_DCO,LABVIEW
 SG_ H51_STK_s_CellVolt_020_2005 m36 : 51|12@0+ (1,0) [0|1500] "mV"  S91_FCCU1,S83_DCO,LABVIEW
 SG_ H51_STK_s_CellVolt_019_2005 m36 : 47|12@0+ (1,0) [0|1500] "mV"  S91_FCCU1,S83_DCO,LABVIEW
 SG_ H51_STK_s_CellVolt_018_2005 m36 : 27|12@0+ (1,0) [0|1500] "mV"  S91_FCCU1,S83_DCO,LABVIEW
 SG_ H51_STK_s_CellVolt_017_2005 m36 : 23|12@0+ (1,0) [0|1500] "mV"  S91_FCCU1,S83_DCO,LABVIEW
 SG_ H51_STK_s_CellVolt_016_2005 m35 : 51|12@0+ (1,0) [0|1500] "mV"  S91_FCCU1,S83_DCO,LABVIEW
 SG_ H51_STK_s_CellVolt_015_2005 m35 : 47|12@0+ (1,0) [0|1500] "mV"  S91_FCCU1,S83_DCO,LABVIEW
 SG_ H51_STK_s_CellVolt_014_2005 m35 : 27|12@0+ (1,0) [0|1500] "mV"  S91_FCCU1,S83_DCO,LABVIEW
 SG_ H51_STK_s_CellVolt_013_2005 m35 : 23|12@0+ (1,0) [0|1500] "mV"  S91_FCCU1,S83_DCO,LABVIEW
 SG_ H51_STK_s_CellVolt_012_2005 m34 : 51|12@0+ (1,0) [0|1500] "mV"  S91_FCCU1,S83_DCO,LABVIEW
 SG_ H51_STK_s_CellVolt_011_2005 m34 : 47|12@0+ (1,0) [0|1500] "mV"  S91_FCCU1,S83_DCO,LABVIEW
 SG_ H51_STK_s_CellVolt_010_2005 m34 : 27|12@0+ (1,0) [0|1500] "mV"  S91_FCCU1,S83_DCO,LABVIEW
 SG_ H51_STK_s_CellVolt_009_2005 m34 : 23|12@0+ (1,0) [0|1500] "mV"  S91_FCCU1,S83_DCO,LABVIEW
 SG_ H51_STK_s_CellVolt_008_2005 m33 : 51|12@0+ (1,0) [0|1500] "mV"  S91_FCCU1,S83_DCO,LABVIEW
 SG_ H51_STK_s_CellVolt_007_2005 m33 : 47|12@0+ (1,0) [0|1500] "mV"  S91_FCCU1,S83_DCO,LABVIEW
 SG_ H51_STK_s_CellVolt_006_2005 m33 : 27|12@0+ (1,0) [0|1500] "mV"  S91_FCCU1,S83_DCO,LABVIEW
 SG_ H51_STK_s_CellVolt_004_2005 m16 : 51|12@0+ (1,0) [0|1500] "mV"  S91_FCCU1,S83_DCO,LABVIEW
 SG_ H51_STK_s_CellVolt_003_2005 m16 : 47|12@0+ (1,0) [0|1500] "mV"  S91_FCCU1,S83_DCO,LABVIEW
 SG_ H51_STK_s_CellVolt_002_2005 m16 : 27|12@0+ (1,0) [0|1500] "mV"  S91_FCCU1,S83_DCO,LABVIEW
 SG_ H51_STK_s_CellVolt_005_2005 m33 : 23|12@0+ (1,0) [0|1500] "mV"  S91_FCCU1,S83_DCO,LABVIEW
 SG_ H51_STK_s_CellVolt_001_2005 m16 : 23|12@0+ (1,0) [0|1500] "mV"  S91_FCCU1,S83_DCO,LABVIEW

BO_ 2147491846 H51_STACK_Cell_Contact_Status: 8 H51_STACK
 SG_ H51_STK_s_FrameMux_2006 M : 0|8@1+ (1,0) [0|255] ""  S91_FCCU1,S83_DCO,LABVIEW
 SG_ H51_STK_s_AmountofContactFailure m2 : 16|8@1+ (1,0) [0|255] ""  S91_FCCU1,S83_DCO,LABVIEW
 SG_ H51_STK_s_CellContactNr1_2006 m2 : 31|12@0+ (1,0) [0|4095] ""  S91_FCCU1,S83_DCO,LABVIEW
 SG_ H51_STK_s_CellContactNr2_2006 m2 : 35|12@0+ (1,0) [0|4095] ""  S91_FCCU1,S83_DCO,LABVIEW
 SG_ H51_STK_s_CellContactNr3_2006 m2 : 55|12@0+ (1,0) [0|4095] ""  S91_FCCU1,S83_DCO,LABVIEW
 SG_ H51_STK_s_AmountOfFrames_2006 m16 : 8|8@1+ (1,0) [0|255] ""  S91_FCCU1,S83_DCO,LABVIEW
 SG_ H51_STK_s_CellContactNr4_2006 m33 : 23|12@0+ (1,0) [0|4095] ""  S91_FCCU1,S83_DCO,LABVIEW
 SG_ H51_STK_s_CellContactNr5_2006 m33 : 27|12@0+ (1,0) [0|4095] ""  S91_FCCU1,S83_DCO,LABVIEW
 SG_ H51_STK_s_CellContactNr6_2006 m33 : 47|12@0+ (1,0) [0|4095] ""  S91_FCCU1,S83_DCO,LABVIEW
 SG_ H51_STK_s_CellContactNr7_2006 m33 : 51|12@0+ (1,0) [0|4095] ""  S91_FCCU1,S83_DCO,LABVIEW
 SG_ H51_STK_s_CellContactNr8_2006 m34 : 23|12@0+ (1,0) [0|4095] ""  S91_FCCU1,S83_DCO,LABVIEW
 SG_ H51_STK_s_CellContactNr9_2006 m34 : 27|12@0+ (1,0) [0|4095] ""  S91_FCCU1,S83_DCO,LABVIEW
 SG_ H51_STK_s_CellContactNr10_2006 m34 : 47|12@0+ (1,0) [0|4095] ""  S91_FCCU1,S83_DCO,LABVIEW
 SG_ H51_STK_s_CellContactNr11_2006 m34 : 51|12@0+ (1,0) [0|4095] ""  S91_FCCU1,S83_DCO,LABVIEW
 SG_ H51_STK_s_CellContactNr12_2006 m35 : 23|12@0+ (1,0) [0|4095] ""  S91_FCCU1,S83_DCO,LABVIEW
 SG_ H51_STK_s_CellContactNr13_2006 m35 : 27|12@0+ (1,0) [0|4095] ""  S91_FCCU1,S83_DCO,LABVIEW
 SG_ H51_STK_s_CellContactNr14_2006 m35 : 47|12@0+ (1,0) [0|4095] ""  S91_FCCU1,S83_DCO,LABVIEW
 SG_ H51_STK_s_CellContactNr15_2006 m35 : 51|12@0+ (1,0) [0|4095] ""  S91_FCCU1,S83_DCO,LABVIEW
 SG_ H51_STK_s_CellContactNr16_2006 m36 : 23|12@0+ (1,0) [0|4095] ""  S91_FCCU1,S83_DCO,LABVIEW
 SG_ H51_STK_s_CellContactNr17_2006 m36 : 27|12@0+ (1,0) [0|4095] ""  S91_FCCU1,S83_DCO,LABVIEW
 SG_ H51_STK_s_CellContactNr18_2006 m36 : 47|12@0+ (1,0) [0|4095] ""  S91_FCCU1,S83_DCO,LABVIEW
 SG_ H51_STK_s_CellContactNr19_2006 m36 : 51|12@0+ (1,0) [0|4095] ""  S91_FCCU1,S83_DCO,LABVIEW
 SG_ H51_STK_s_CellContactNr20_2006 m37 : 23|12@0+ (1,0) [0|4095] ""  S91_FCCU1,S83_DCO,LABVIEW
 SG_ H51_STK_s_CellContactNr21_2006 m37 : 27|12@0+ (1,0) [0|4095] ""  S91_FCCU1,S83_DCO,LABVIEW
 SG_ H51_STK_s_CellContactNr22_2006 m37 : 47|12@0+ (1,0) [0|4095] ""  S91_FCCU1,S83_DCO,LABVIEW
 SG_ H51_STK_s_CellContactNr23_2006 m37 : 51|12@0+ (1,0) [0|4095] ""  S91_FCCU1,S83_DCO,LABVIEW
 SG_ H51_STK_s_CellContactNr24_2006 m38 : 23|12@0+ (1,0) [0|4095] ""  S91_FCCU1,S83_DCO,LABVIEW
 SG_ H51_STK_s_CellContactNr25_2006 m38 : 27|12@0+ (1,0) [0|4095] ""  S91_FCCU1,S83_DCO,LABVIEW
 SG_ H51_STK_s_CellContactNr26_2006 m38 : 47|12@0+ (1,0) [0|4095] ""  S91_FCCU1,S83_DCO,LABVIEW
 SG_ H51_STK_s_CellContactNr27_2006 m38 : 51|12@0+ (1,0) [0|4095] ""  S91_FCCU1,S83_DCO,LABVIEW
 SG_ H51_STK_s_CellContactNr28_2006 m39 : 23|12@0+ (1,0) [0|4095] ""  S91_FCCU1,S83_DCO,LABVIEW
 SG_ H51_STK_s_CellContactNr29_2006 m39 : 27|12@0+ (1,0) [0|4095] ""  S91_FCCU1,S83_DCO,LABVIEW
 SG_ H51_STK_s_CellContactNr30_2006 m39 : 47|12@0+ (1,0) [0|4095] ""  S91_FCCU1,S83_DCO,LABVIEW
 SG_ H51_STK_s_CellContactNr31_2006 m39 : 51|12@0+ (1,0) [0|4095] ""  S91_FCCU1,S83_DCO,LABVIEW
 SG_ H51_STK_s_CellContactNr32_2006 m40 : 23|12@0+ (1,0) [0|4095] ""  S91_FCCU1,S83_DCO,LABVIEW
 SG_ H51_STK_s_CellContactNr33_2006 m40 : 27|12@0+ (1,0) [0|4095] ""  S91_FCCU1,S83_DCO,LABVIEW
 SG_ H51_STK_s_CellContactNr34_2006 m40 : 47|12@0+ (1,0) [0|4095] ""  S91_FCCU1,S83_DCO,LABVIEW
 SG_ H51_STK_s_CellContactNr35_2006 m40 : 51|12@0+ (1,0) [0|4095] ""  S91_FCCU1,S83_DCO,LABVIEW
 SG_ H51_STK_s_CellContactNr36_2006 m41 : 23|12@0+ (1,0) [0|4095] ""  S91_FCCU1,S83_DCO,LABVIEW
 SG_ H51_STK_s_CellContactNr37_2006 m41 : 27|12@0+ (1,0) [0|4095] ""  S91_FCCU1,S83_DCO,LABVIEW
 SG_ H51_STK_s_CellContactNr38_2006 m41 : 47|12@0+ (1,0) [0|4095] ""  S91_FCCU1,S83_DCO,LABVIEW
 SG_ H51_STK_s_CellContactNr39_2006 m41 : 51|12@0+ (1,0) [0|4095] ""  S91_FCCU1,S83_DCO,LABVIEW
 SG_ H51_STK_s_CellContactNr40_2006 m42 : 23|12@0+ (1,0) [0|4095] ""  S91_FCCU1,S83_DCO,LABVIEW
 SG_ H51_STK_s_CellContactNr41_2006 m42 : 27|12@0+ (1,0) [0|4095] ""  S91_FCCU1,S83_DCO,LABVIEW
 SG_ H51_STK_s_CellContactNr42_2006 m42 : 47|12@0+ (1,0) [0|4095] ""  S91_FCCU1,S83_DCO,LABVIEW
 SG_ H51_STK_s_CellContactNr43_2006 m42 : 51|12@0+ (1,0) [0|4095] ""  S91_FCCU1,S83_DCO,LABVIEW
 SG_ H51_STK_s_CellContactNr44_2006 m43 : 23|12@0+ (1,0) [0|4095] ""  S91_FCCU1,S83_DCO,LABVIEW
 SG_ H51_STK_s_CellContactNr45_2006 m43 : 27|12@0+ (1,0) [0|4095] ""  S91_FCCU1,S83_DCO,LABVIEW
 SG_ H51_STK_s_CellContactNr46_2006 m43 : 47|12@0+ (1,0) [0|4095] ""  S91_FCCU1,S83_DCO,LABVIEW
 SG_ H51_STK_s_CellContactNr47_2006 m43 : 51|12@0+ (1,0) [0|4095] ""  S91_FCCU1,S83_DCO,LABVIEW
 SG_ H51_STK_s_CellContactNr48_2006 m44 : 23|12@0+ (1,0) [0|4095] ""  S91_FCCU1,S83_DCO,LABVIEW
 SG_ H51_STK_s_CellContactNr49_2006 m44 : 27|12@0+ (1,0) [0|4095] ""  S91_FCCU1,S83_DCO,LABVIEW
 SG_ H51_STK_s_CellContactNr50_2006 m44 : 47|12@0+ (1,0) [0|4095] ""  S91_FCCU1,S83_DCO,LABVIEW
 SG_ H51_STK_s_CellContactNr51_2006 m44 : 51|12@0+ (1,0) [0|4095] ""  S91_FCCU1,S83_DCO,LABVIEW
 SG_ H51_STK_s_CellContactNr52_2006 m45 : 23|12@0+ (1,0) [0|4095] ""  S91_FCCU1,S83_DCO,LABVIEW
 SG_ H51_STK_s_CellContactNr53_2006 m45 : 27|12@0+ (1,0) [0|4095] ""  S91_FCCU1,S83_DCO,LABVIEW
 SG_ H51_STK_s_CellContactNr54_2006 m45 : 47|12@0+ (1,0) [0|4095] ""  S91_FCCU1,S83_DCO,LABVIEW
 SG_ H51_STK_s_CellContactNr55_2006 m45 : 51|12@0+ (1,0) [0|4095] ""  S91_FCCU1,S83_DCO,LABVIEW
 SG_ H51_STK_s_CellContactNr56_2006 m46 : 23|12@0+ (1,0) [0|4095] ""  S91_FCCU1,S83_DCO,LABVIEW
 SG_ H51_STK_s_CellContactNr57_2006 m46 : 27|12@0+ (1,0) [0|4095] ""  S91_FCCU1,S83_DCO,LABVIEW
 SG_ H51_STK_s_CellContactNr58_2006 m46 : 47|12@0+ (1,0) [0|4095] ""  S91_FCCU1,S83_DCO,LABVIEW
 SG_ H51_STK_s_CellContactNr59_2006 m46 : 51|12@0+ (1,0) [0|4095] ""  S91_FCCU1,S83_DCO,LABVIEW
 SG_ H51_STK_s_CellContactNr60_2006 m47 : 23|12@0+ (1,0) [0|4095] ""  S91_FCCU1,S83_DCO,LABVIEW
 SG_ H51_STK_s_CellContactNr61_2006 m47 : 27|12@0+ (1,0) [0|4095] ""  S91_FCCU1,S83_DCO,LABVIEW
 SG_ H51_STK_s_CellContactNr62_2006 m47 : 47|12@0+ (1,0) [0|4095] ""  S91_FCCU1,S83_DCO,LABVIEW
 SG_ H51_STK_s_CellContactNr63_2006 m47 : 51|12@0+ (1,0) [0|4095] ""  S91_FCCU1,S83_DCO,LABVIEW
 SG_ H51_STK_s_CellContactNr64_2006 m48 : 23|12@0+ (1,0) [0|4095] ""  S91_FCCU1,S83_DCO,LABVIEW
 SG_ H51_STK_s_CellContactNr65_2006 m48 : 27|12@0+ (1,0) [0|4095] ""  S91_FCCU1,S83_DCO,LABVIEW
 SG_ H51_STK_s_CellContactNr66_2006 m48 : 47|12@0+ (1,0) [0|4095] ""  S91_FCCU1,S83_DCO,LABVIEW
 SG_ H51_STK_s_CellContactNr67_2006 m48 : 51|12@0+ (1,0) [0|4095] ""  S91_FCCU1,S83_DCO,LABVIEW
 SG_ H51_STK_s_CellContactNr68_2006 m49 : 23|12@0+ (1,0) [0|4095] ""  S91_FCCU1,S83_DCO,LABVIEW
 SG_ H51_STK_s_CellContactNr69_2006 m49 : 27|12@0+ (1,0) [0|4095] ""  S91_FCCU1,S83_DCO,LABVIEW
 SG_ H51_STK_s_CellContactNr70_2006 m49 : 47|12@0+ (1,0) [0|4095] ""  S91_FCCU1,S83_DCO,LABVIEW
 SG_ H51_STK_s_CellContactNr71_2006 m49 : 51|12@0+ (1,0) [0|4095] ""  S91_FCCU1,S83_DCO,LABVIEW

BO_ 2147491855 H51_STACK_CVM_Resp: 8 H51_STACK
 SG_ H51_STK_s_DataLength_200F : 0|8@1+ (1,0) [0|255] ""  S91_FCCU1,S83_DCO,LABVIEW
 SG_ H51_STK_s_ID_H_200F : 8|8@1+ (1,0) [0|255] ""  S91_FCCU1,S83_DCO,LABVIEW
 SG_ H51_STK_s_ID_L_200F : 16|8@1+ (1,0) [0|255] ""  S91_FCCU1,S83_DCO,LABVIEW
 SG_ H51_STK_s_CVMResponse_200F : 24|8@1+ (1,0) [0|255] ""  S91_FCCU1,S83_DCO,LABVIEW

BO_ 2147491856 H51_STACK_CellContactStateDiag: 8 H51_STACK
 SG_ H51_STK_s_FrameMux_CVM_2010 M : 0|8@1+ (1,0) [0|255] ""  S91_FCCU1,S83_DCO,LABVIEW
 SG_ H51_STK_s_DataLength_CVM_2010 m16 : 8|8@1+ (1,0) [0|65535] ""  S91_FCCU1,S83_DCO,LABVIEW
 SG_ H51_STK_s_Contact_Cell_1_2010 m16 : 31|12@0+ (1,0) [0|4095] ""  S91_FCCU1,S83_DCO,LABVIEW
 SG_ H51_STK_s_Contact_Cell_2_2010 m16 : 35|12@0+ (1,0) [0|4095] ""  S91_FCCU1,S83_DCO,LABVIEW
 SG_ H51_STK_s_Contact_Cell_3_2010 m16 : 55|12@0+ (1,0) [0|4095] ""  S91_FCCU1,S83_DCO,LABVIEW
 SG_ H51_STK_s_Contact_Cell_4_2010 m33 : 23|12@0+ (1,0) [0|4095] ""  S91_FCCU1,S83_DCO,LABVIEW
 SG_ H51_STK_s_Contact_Cell_5_2010 m33 : 27|12@0+ (1,0) [0|4095] ""  S91_FCCU1,S83_DCO,LABVIEW
 SG_ H51_STK_s_Contact_Cell_6_2010 m33 : 47|12@0+ (1,0) [0|4095] ""  S91_FCCU1,S83_DCO,LABVIEW
 SG_ H51_STK_s_Contact_Cell_7_2010 m33 : 51|12@0+ (1,0) [0|4095] ""  S91_FCCU1,S83_DCO,LABVIEW
 SG_ H51_STK_s_Contact_Cell_8_2010 m34 : 23|12@0+ (1,0) [0|4095] ""  S91_FCCU1,S83_DCO,LABVIEW
 SG_ H51_STK_s_Contact_Cell_9_2010 m34 : 27|12@0+ (1,0) [0|4095] ""  S91_FCCU1,S83_DCO,LABVIEW
 SG_ H51_STK_s_Contact_Cell_10_2010 m34 : 47|12@0+ (1,0) [0|4095] ""  S91_FCCU1,S83_DCO,LABVIEW
 SG_ H51_STK_s_Contact_Cell_11_2010 m34 : 51|12@0+ (1,0) [0|4095] ""  S91_FCCU1,S83_DCO,LABVIEW
 SG_ H51_STK_s_Contact_Cell_12_2010 m35 : 23|12@0+ (1,0) [0|4095] ""  S91_FCCU1,S83_DCO,LABVIEW
 SG_ H51_STK_s_Contact_Cell_13_2010 m35 : 27|12@0+ (1,0) [0|4095] ""  S91_FCCU1,S83_DCO,LABVIEW
 SG_ H51_STK_s_Contact_Cell_14_2010 m35 : 47|12@0+ (1,0) [0|4095] ""  S91_FCCU1,S83_DCO,LABVIEW
 SG_ H51_STK_s_Contact_Cell_15_2010 m35 : 51|12@0+ (1,0) [0|4095] ""  S91_FCCU1,S83_DCO,LABVIEW
 SG_ H51_STK_s_Contact_Cell_16_2010 m36 : 23|12@0+ (1,0) [0|4095] ""  S91_FCCU1,S83_DCO,LABVIEW
 SG_ H51_STK_s_Contact_Cell_17_2010 m36 : 27|12@0+ (1,0) [0|4095] ""  S91_FCCU1,S83_DCO,LABVIEW
 SG_ H51_STK_s_Contact_Cell_18_2010 m36 : 47|12@0+ (1,0) [0|4095] ""  S91_FCCU1,S83_DCO,LABVIEW
 SG_ H51_STK_s_Contact_Cell_19_2010 m36 : 51|12@0+ (1,0) [0|4095] ""  S91_FCCU1,S83_DCO,LABVIEW
 SG_ H51_STK_s_Contact_Cell_20_2010 m37 : 23|12@0+ (1,0) [0|4095] ""  S91_FCCU1,S83_DCO,LABVIEW
 SG_ H51_STK_s_Contact_Cell_21_2010 m37 : 27|12@0+ (1,0) [0|4095] ""  S91_FCCU1,S83_DCO,LABVIEW
 SG_ H51_STK_s_Contact_Cell_22_2010 m37 : 47|12@0+ (1,0) [0|4095] ""  S91_FCCU1,S83_DCO,LABVIEW
 SG_ H51_STK_s_Contact_Cell_23_2010 m37 : 51|12@0+ (1,0) [0|4095] ""  S91_FCCU1,S83_DCO,LABVIEW
 SG_ H51_STK_s_Contact_Cell_24_2010 m38 : 23|12@0+ (1,0) [0|4095] ""  S91_FCCU1,S83_DCO,LABVIEW
 SG_ H51_STK_s_Contact_Cell_25_2010 m38 : 27|12@0+ (1,0) [0|4095] ""  S91_FCCU1,S83_DCO,LABVIEW
 SG_ H51_STK_s_Contact_Cell_26_2010 m38 : 47|12@0+ (1,0) [0|4095] ""  S91_FCCU1,S83_DCO,LABVIEW
 SG_ H51_STK_s_Contact_Cell_27_2010 m38 : 51|12@0+ (1,0) [0|4095] ""  S91_FCCU1,S83_DCO,LABVIEW
 SG_ H51_STK_s_Contact_Cell_28_2010 m39 : 23|12@0+ (1,0) [0|4095] ""  S91_FCCU1,S83_DCO,LABVIEW
 SG_ H51_STK_s_Contact_Cell_29_2010 m39 : 27|12@0+ (1,0) [0|4095] ""  S91_FCCU1,S83_DCO,LABVIEW
 SG_ H51_STK_s_Contact_Cell_30_2010 m39 : 47|12@0+ (1,0) [0|4095] ""  S91_FCCU1,S83_DCO,LABVIEW
 SG_ H51_STK_s_Contact_Cell_31_2010 m39 : 51|12@0+ (1,0) [0|4095] ""  S91_FCCU1,S83_DCO,LABVIEW
 SG_ H51_STK_s_Contact_Cell_32_2010 m40 : 23|12@0+ (1,0) [0|4095] ""  S91_FCCU1,S83_DCO,LABVIEW
 SG_ H51_STK_s_Contact_Cell_33_2010 m40 : 27|12@0+ (1,0) [0|4095] ""  S91_FCCU1,S83_DCO,LABVIEW
 SG_ H51_STK_s_Contact_Cell_34_2010 m40 : 47|12@0+ (1,0) [0|4095] ""  S91_FCCU1,S83_DCO,LABVIEW
 SG_ H51_STK_s_Contact_Cell_35_2010 m40 : 51|12@0+ (1,0) [0|4095] ""  S91_FCCU1,S83_DCO,LABVIEW
 SG_ H51_STK_s_Contact_Cell_36_2010 m41 : 23|12@0+ (1,0) [0|4095] ""  S91_FCCU1,S83_DCO,LABVIEW
 SG_ H51_STK_s_Contact_Cell_37_2010 m41 : 27|12@0+ (1,0) [0|4095] ""  S91_FCCU1,S83_DCO,LABVIEW
 SG_ H51_STK_s_Contact_Cell_38_2010 m41 : 47|12@0+ (1,0) [0|4095] ""  S91_FCCU1,S83_DCO,LABVIEW
 SG_ H51_STK_s_Contact_Cell_39_2010 m41 : 51|12@0+ (1,0) [0|4095] ""  S91_FCCU1,S83_DCO,LABVIEW
 SG_ H51_STK_s_Contact_Cell_40_2010 m42 : 23|12@0+ (1,0) [0|4095] ""  S91_FCCU1,S83_DCO,LABVIEW
 SG_ H51_STK_s_Contact_Cell_41_2010 m42 : 27|12@0+ (1,0) [0|4095] ""  S91_FCCU1,S83_DCO,LABVIEW
 SG_ H51_STK_s_Contact_Cell_42_2010 m42 : 47|12@0+ (1,0) [0|4095] ""  S91_FCCU1,S83_DCO,LABVIEW
 SG_ H51_STK_s_Contact_Cell_43_2010 m42 : 51|12@0+ (1,0) [0|4095] ""  S91_FCCU1,S83_DCO,LABVIEW
 SG_ H51_STK_s_Contact_Cell_44_2010 m43 : 23|12@0+ (1,0) [0|4095] ""  S91_FCCU1,S83_DCO,LABVIEW
 SG_ H51_STK_s_Contact_Cell_45_2010 m43 : 27|12@0+ (1,0) [0|4095] ""  S91_FCCU1,S83_DCO,LABVIEW
 SG_ H51_STK_s_Contact_Cell_46_2010 m43 : 47|12@0+ (1,0) [0|4095] ""  S91_FCCU1,S83_DCO,LABVIEW
 SG_ H51_STK_s_Contact_Cell_47_2010 m43 : 51|12@0+ (1,0) [0|4095] ""  S91_FCCU1,S83_DCO,LABVIEW
 SG_ H51_STK_s_Contact_Cell_48_2010 m44 : 23|12@0+ (1,0) [0|4095] ""  S91_FCCU1,S83_DCO,LABVIEW
 SG_ H51_STK_s_Contact_Cell_49_2010 m44 : 27|12@0+ (1,0) [0|4095] ""  S91_FCCU1,S83_DCO,LABVIEW
 SG_ H51_STK_s_Contact_Cell_50_2010 m44 : 47|12@0+ (1,0) [0|4095] ""  S91_FCCU1,S83_DCO,LABVIEW
 SG_ H51_STK_s_Contact_Cell_51_2010 m44 : 51|12@0+ (1,0) [0|4095] ""  S91_FCCU1,S83_DCO,LABVIEW
 SG_ H51_STK_s_Contact_Cell_52_2010 m45 : 23|12@0+ (1,0) [0|4095] ""  S91_FCCU1,S83_DCO,LABVIEW
 SG_ H51_STK_s_Contact_Cell_53_2010 m45 : 27|12@0+ (1,0) [0|4095] ""  S91_FCCU1,S83_DCO,LABVIEW
 SG_ H51_STK_s_Contact_Cell_54_2010 m45 : 47|12@0+ (1,0) [0|4095] ""  S91_FCCU1,S83_DCO,LABVIEW
 SG_ H51_STK_s_Contact_Cell_55_2010 m45 : 51|12@0+ (1,0) [0|4095] ""  S91_FCCU1,S83_DCO,LABVIEW
 SG_ H51_STK_s_Contact_Cell_56_2010 m46 : 23|12@0+ (1,0) [0|4095] ""  S91_FCCU1,S83_DCO,LABVIEW
 SG_ H51_STK_s_Contact_Cell_57_2010 m46 : 27|12@0+ (1,0) [0|4095] ""  S91_FCCU1,S83_DCO,LABVIEW
 SG_ H51_STK_s_Contact_Cell_58_2010 m46 : 47|12@0+ (1,0) [0|4095] ""  S91_FCCU1,S83_DCO,LABVIEW
 SG_ H51_STK_s_Contact_Cell_59_2010 m46 : 51|12@0+ (1,0) [0|4095] ""  S91_FCCU1,S83_DCO,LABVIEW
 SG_ H51_STK_s_Contact_Cell_60_2010 m47 : 23|12@0+ (1,0) [0|4095] ""  S91_FCCU1,S83_DCO,LABVIEW
 SG_ H51_STK_s_Contact_Cell_61_2010 m47 : 27|12@0+ (1,0) [0|4095] ""  S91_FCCU1,S83_DCO,LABVIEW
 SG_ H51_STK_s_Contact_Cell_62_2010 m47 : 47|12@0+ (1,0) [0|4095] ""  S91_FCCU1,S83_DCO,LABVIEW
 SG_ H51_STK_s_Contact_Cell_63_2010 m47 : 51|12@0+ (1,0) [0|4095] ""  S91_FCCU1,S83_DCO,LABVIEW
 SG_ H51_STK_s_Contact_Cell_64_2010 m48 : 23|12@0+ (1,0) [0|4095] ""  S91_FCCU1,S83_DCO,LABVIEW
 SG_ H51_STK_s_Contact_Cell_65_2010 m48 : 27|12@0+ (1,0) [0|4095] ""  S91_FCCU1,S83_DCO,LABVIEW
 SG_ H51_STK_s_Contact_Cell_66_2010 m48 : 47|12@0+ (1,0) [0|4095] ""  S91_FCCU1,S83_DCO,LABVIEW
 SG_ H51_STK_s_Contact_Cell_67_2010 m48 : 51|12@0+ (1,0) [0|4095] ""  S91_FCCU1,S83_DCO,LABVIEW
 SG_ H51_STK_s_Contact_Cell_68_2010 m49 : 23|12@0+ (1,0) [0|4095] ""  S91_FCCU1,S83_DCO,LABVIEW
 SG_ H51_STK_s_Contact_Cell_69_2010 m49 : 27|12@0+ (1,0) [0|4095] ""  S91_FCCU1,S83_DCO,LABVIEW
 SG_ H51_STK_s_Contact_Cell_70_2010 m49 : 47|12@0+ (1,0) [0|4095] ""  S91_FCCU1,S83_DCO,LABVIEW
 SG_ H51_STK_s_Contact_Cell_71_2010 m49 : 51|12@0+ (1,0) [0|4095] ""  S91_FCCU1,S83_DCO,LABVIEW

BO_ 2147491857 H51_STACK_TestData: 8 H51_STACK
 SG_ H51_STK_s_Slave1BMS2REF2_2011 m33 : 51|12@0+ (1,0) [0|4095] ""  S91_FCCU1,S83_DCO,LABVIEW
 SG_ H51_STK_s_Slave1BMS2REF1_2011 m33 : 47|12@0+ (1,0) [0|4095] ""  S91_FCCU1,S83_DCO,LABVIEW
 SG_ H51_STK_s_Slave1BMS1REF2_2011 m33 : 27|12@0+ (1,0) [0|4095] ""  S91_FCCU1,S83_DCO,LABVIEW
 SG_ H51_STK_s_Slave1BMS1REF1_2011 m33 : 23|12@0+ (1,0) [0|4095] ""  S91_FCCU1,S83_DCO,LABVIEW
 SG_ H51_STK_s_Slave2BMS2REF2_2011 m34 : 51|12@0+ (1,0) [0|4095] ""  S91_FCCU1,S83_DCO,LABVIEW
 SG_ H51_STK_s_Slave2BMS2REF1_2011 m34 : 47|12@0+ (1,0) [0|4095] ""  S91_FCCU1,S83_DCO,LABVIEW
 SG_ H51_STK_s_Slave2BMS1REF2_2011 m34 : 27|12@0+ (1,0) [0|4095] ""  S91_FCCU1,S83_DCO,LABVIEW
 SG_ H51_STK_s_Slave2BMS1REF1_2011 m34 : 23|12@0+ (1,0) [0|4095] ""  S91_FCCU1,S83_DCO,LABVIEW
 SG_ H51_STK_s_Slave3BMS2REF2_2011 m35 : 51|12@0+ (1,0) [0|4095] ""  S91_FCCU1,S83_DCO,LABVIEW
 SG_ H51_STK_s_Slave3BMS2REF1_2011 m35 : 47|12@0+ (1,0) [0|4095] ""  S91_FCCU1,S83_DCO,LABVIEW
 SG_ H51_STK_s_Slave3BMS1REF2_2011 m35 : 27|12@0+ (1,0) [0|4095] ""  S91_FCCU1,S83_DCO,LABVIEW
 SG_ H51_STK_s_Slave3BMS1REF1_2011 m35 : 23|12@0+ (1,0) [0|4095] ""  S91_FCCU1,S83_DCO,LABVIEW
 SG_ H51_STK_s_Slave4BMS2REF2_2011 m36 : 51|12@0+ (1,0) [0|4095] ""  S91_FCCU1,S83_DCO,LABVIEW
 SG_ H51_STK_s_Slave4BMS2REF1_2011 m36 : 47|12@0+ (1,0) [0|4095] ""  S91_FCCU1,S83_DCO,LABVIEW
 SG_ H51_STK_s_Slave4BMS1REF2_2011 m36 : 27|12@0+ (1,0) [0|4095] ""  S91_FCCU1,S83_DCO,LABVIEW
 SG_ H51_STK_s_Slave4BMS1REF1_2011 m36 : 23|12@0+ (1,0) [0|4095] ""  S91_FCCU1,S83_DCO,LABVIEW
 SG_ H51_STK_s_Slave5BMS2REF2_2011 m37 : 51|12@0+ (1,0) [0|4095] ""  S91_FCCU1,S83_DCO,LABVIEW
 SG_ H51_STK_s_Slave5BMS2REF1_2011 m37 : 47|12@0+ (1,0) [0|4095] ""  S91_FCCU1,S83_DCO,LABVIEW
 SG_ H51_STK_s_Slave5BMS1REF2_2011 m37 : 27|12@0+ (1,0) [0|4095] ""  S91_FCCU1,S83_DCO,LABVIEW
 SG_ H51_STK_s_Slave5BMS1REF1_2011 m37 : 23|12@0+ (1,0) [0|4095] ""  S91_FCCU1,S83_DCO,LABVIEW
 SG_ H51_STK_s_Slave6BMS2REF2_2011 m38 : 51|12@0+ (1,0) [0|4095] ""  S91_FCCU1,S83_DCO,LABVIEW
 SG_ H51_STK_s_Slave6BMS2REF1_2011 m38 : 47|12@0+ (1,0) [0|4095] ""  S91_FCCU1,S83_DCO,LABVIEW
 SG_ H51_STK_s_Slave6BMS1REF2_2011 m38 : 27|12@0+ (1,0) [0|4095] ""  S91_FCCU1,S83_DCO,LABVIEW
 SG_ H51_STK_s_Slave6BMS1REF1_2011 m38 : 23|12@0+ (1,0) [0|4095] ""  S91_FCCU1,S83_DCO,LABVIEW
 SG_ H51_STK_s_Slave7BMS2REF2_2011 m39 : 51|12@0+ (1,0) [0|4095] ""  S91_FCCU1,S83_DCO,LABVIEW
 SG_ H51_STK_s_Slave7BMS2REF1_2011 m39 : 47|12@0+ (1,0) [0|4095] ""  S91_FCCU1,S83_DCO,LABVIEW
 SG_ H51_STK_s_Slave7BMS1REF2_2011 m39 : 27|12@0+ (1,0) [0|4095] ""  S91_FCCU1,S83_DCO,LABVIEW
 SG_ H51_STK_s_Slave7BMS1REF1_2011 m39 : 23|12@0+ (1,0) [0|4095] ""  S91_FCCU1,S83_DCO,LABVIEW
 SG_ H51_STK_s_Slave8BMS2REF2_2011 m40 : 51|12@0+ (1,0) [0|4095] ""  S91_FCCU1,S83_DCO,LABVIEW
 SG_ H51_STK_s_Slave8BMS2REF1_2011 m40 : 47|12@0+ (1,0) [0|4095] ""  S91_FCCU1,S83_DCO,LABVIEW
 SG_ H51_STK_s_Slave8BMS1REF2_2011 m40 : 27|12@0+ (1,0) [0|4095] ""  S91_FCCU1,S83_DCO,LABVIEW
 SG_ H51_STK_s_Slave8BMS1REF1_2011 m40 : 23|12@0+ (1,0) [0|4095] ""  S91_FCCU1,S83_DCO,LABVIEW
 SG_ H51_STK_s_Slave9BMS2REF2_2011 m41 : 51|12@0+ (1,0) [0|4095] ""  S91_FCCU1,S83_DCO,LABVIEW
 SG_ H51_STK_s_Slave9BMS2REF1_2011 m41 : 47|12@0+ (1,0) [0|4095] ""  S91_FCCU1,S83_DCO,LABVIEW
 SG_ H51_STK_s_Slave9BMS1REF2_2011 m41 : 27|12@0+ (1,0) [0|4095] ""  S91_FCCU1,S83_DCO,LABVIEW
 SG_ H51_STK_s_Slave9BMS1REF1_2011 m41 : 23|12@0+ (1,0) [0|4095] ""  S91_FCCU1,S83_DCO,LABVIEW
 SG_ H51_STK_s_Slave10BMS2REF2_2011 m42 : 51|12@0+ (1,0) [0|4095] ""  S91_FCCU1,S83_DCO,LABVIEW
 SG_ H51_STK_s_Slave10BMS2REF1_2011 m42 : 47|12@0+ (1,0) [0|4095] ""  S91_FCCU1,S83_DCO,LABVIEW
 SG_ H51_STK_s_Slave10BMS1REF2_2011 m42 : 27|12@0+ (1,0) [0|4095] ""  S91_FCCU1,S83_DCO,LABVIEW
 SG_ H51_STK_s_Slave10BMS1REF1_2011 m42 : 23|12@0+ (1,0) [0|4095] ""  S91_FCCU1,S83_DCO,LABVIEW
 SG_ H51_STK_s_Slave11BMS2REF2_2011 m43 : 51|12@0+ (1,0) [0|4095] ""  S91_FCCU1,S83_DCO,LABVIEW
 SG_ H51_STK_s_Slave11BMS2REF1_2011 m43 : 47|12@0+ (1,0) [0|4095] ""  S91_FCCU1,S83_DCO,LABVIEW
 SG_ H51_STK_s_Slave11BMS1REF2_2011 m43 : 27|12@0+ (1,0) [0|4095] ""  S91_FCCU1,S83_DCO,LABVIEW
 SG_ H51_STK_s_Slave11BMS1REF1_2011 m43 : 23|12@0+ (1,0) [0|4095] ""  S91_FCCU1,S83_DCO,LABVIEW
 SG_ H51_STK_s_Slave12BMS2REF2_2011 m44 : 51|12@0+ (1,0) [0|4095] ""  S91_FCCU1,S83_DCO,LABVIEW
 SG_ H51_STK_s_Slave12BMS2REF1_2011 m44 : 47|12@0+ (1,0) [0|4095] ""  S91_FCCU1,S83_DCO,LABVIEW
 SG_ H51_STK_s_Slave12BMS1REF2_2011 m44 : 27|12@0+ (1,0) [0|4095] ""  S91_FCCU1,S83_DCO,LABVIEW
 SG_ H51_STK_s_Slave12BMS1REF1_2011 m44 : 23|12@0+ (1,0) [0|4095] ""  S91_FCCU1,S83_DCO,LABVIEW
 SG_ H51_STK_s_Slave13BMS2REF2_2011 m45 : 51|12@0+ (1,0) [0|4095] ""  S91_FCCU1,S83_DCO,LABVIEW
 SG_ H51_STK_s_Slave13BMS2REF1_2011 m45 : 47|12@0+ (1,0) [0|4095] ""  S91_FCCU1,S83_DCO,LABVIEW
 SG_ H51_STK_s_Slave13BMS1REF2_2011 m45 : 27|12@0+ (1,0) [0|4095] ""  S91_FCCU1,S83_DCO,LABVIEW
 SG_ H51_STK_s_Slave13BMS1REF1_2011 m45 : 23|12@0+ (1,0) [0|4095] ""  S91_FCCU1,S83_DCO,LABVIEW
 SG_ H51_STK_s_Slave14BMS2REF2_2011 m46 : 51|12@0+ (1,0) [0|4095] ""  S91_FCCU1,S83_DCO,LABVIEW
 SG_ H51_STK_s_Slave14BMS2REF1_2011 m46 : 47|12@0+ (1,0) [0|4095] ""  S91_FCCU1,S83_DCO,LABVIEW
 SG_ H51_STK_s_Slave14BMS1REF2_2011 m46 : 27|12@0+ (1,0) [0|4095] ""  S91_FCCU1,S83_DCO,LABVIEW
 SG_ H51_STK_s_Slave14BMS1REF1_2011 m46 : 23|12@0+ (1,0) [0|4095] ""  S91_FCCU1,S83_DCO,LABVIEW
 SG_ H51_STK_s_Slave15BMS2REF2_2011 m47 : 51|12@0+ (1,0) [0|4095] ""  S91_FCCU1,S83_DCO,LABVIEW
 SG_ H51_STK_s_Slave15BMS2REF1_2011 m47 : 47|12@0+ (1,0) [0|4095] ""  S91_FCCU1,S83_DCO,LABVIEW
 SG_ H51_STK_s_Slave15BMS1REF2_2011 m47 : 27|12@0+ (1,0) [0|4095] ""  S91_FCCU1,S83_DCO,LABVIEW
 SG_ H51_STK_s_Slave15BMS1REF1_2011 m47 : 23|12@0+ (1,0) [0|4095] ""  S91_FCCU1,S83_DCO,LABVIEW
 SG_ H51_STK_s_Slave16BMS2REF2_2011 m48 : 51|12@0+ (1,0) [0|4095] ""  S91_FCCU1,S83_DCO,LABVIEW
 SG_ H51_STK_s_Slave16BMS2REF1_2011 m48 : 47|12@0+ (1,0) [0|4095] ""  S91_FCCU1,S83_DCO,LABVIEW
 SG_ H51_STK_s_Slave16BMS1REF2_2011 m48 : 27|12@0+ (1,0) [0|4095] ""  S91_FCCU1,S83_DCO,LABVIEW
 SG_ H51_STK_s_Slave16BMS1REF1_2011 m48 : 23|12@0+ (1,0) [0|4095] ""  S91_FCCU1,S83_DCO,LABVIEW
 SG_ H51_STK_s_Slave17BMS2REF2_2011 m49 : 51|12@0+ (1,0) [0|4095] ""  S91_FCCU1,S83_DCO,LABVIEW
 SG_ H51_STK_s_Slave17BMS2REF1_2011 m49 : 47|12@0+ (1,0) [0|4095] ""  S91_FCCU1,S83_DCO,LABVIEW
 SG_ H51_STK_s_Slave17BMS1REF2_2011 m49 : 27|12@0+ (1,0) [0|4095] ""  S91_FCCU1,S83_DCO,LABVIEW
 SG_ H51_STK_s_Slave17BMS1REF1_2011 m49 : 23|12@0+ (1,0) [0|4095] ""  S91_FCCU1,S83_DCO,LABVIEW
 SG_ H51_STK_s_Slave18BMS2REF2_2011 m50 : 51|12@0+ (1,0) [0|4095] ""  S91_FCCU1,S83_DCO,LABVIEW
 SG_ H51_STK_s_Slave18BMS2REF1_2011 m50 : 47|12@0+ (1,0) [0|4095] ""  S91_FCCU1,S83_DCO,LABVIEW
 SG_ H51_STK_s_Slave18BMS1REF2_2011 m50 : 27|12@0+ (1,0) [0|4095] ""  S91_FCCU1,S83_DCO,LABVIEW
 SG_ H51_STK_s_Slave18BMS1REF1_2011 m50 : 23|12@0+ (1,0) [0|4095] ""  S91_FCCU1,S83_DCO,LABVIEW
 SG_ H51_STK_s_Slave19BMS2REF2_2011 m51 : 51|12@0+ (1,0) [0|4095] ""  S91_FCCU1,S83_DCO,LABVIEW
 SG_ H51_STK_s_Slave19BMS2REF1_2011 m51 : 47|12@0+ (1,0) [0|4095] ""  S91_FCCU1,S83_DCO,LABVIEW
 SG_ H51_STK_s_Slave19BMS1REF2_2011 m51 : 27|12@0+ (1,0) [0|4095] ""  S91_FCCU1,S83_DCO,LABVIEW
 SG_ H51_STK_s_Slave19BMS1REF1_2011 m51 : 23|12@0+ (1,0) [0|4095] ""  S91_FCCU1,S83_DCO,LABVIEW
 SG_ H51_STK_s_Slave20BMS2REF2_2011 m52 : 51|12@0+ (1,0) [0|4095] ""  S91_FCCU1,S83_DCO,LABVIEW
 SG_ H51_STK_s_Slave20BMS2REF1_2011 m52 : 47|12@0+ (1,0) [0|4095] ""  S91_FCCU1,S83_DCO,LABVIEW
 SG_ H51_STK_s_Slave20BMS1REF2_2011 m52 : 27|12@0+ (1,0) [0|4095] ""  S91_FCCU1,S83_DCO,LABVIEW
 SG_ H51_STK_s_Slave20BMS1REF1_2011 m52 : 23|12@0+ (1,0) [0|4095] ""  S91_FCCU1,S83_DCO,LABVIEW
 SG_ H51_STK_s_Slave21BMS2REF2_2011 m53 : 51|12@0+ (1,0) [0|4095] ""  S91_FCCU1,S83_DCO,LABVIEW
 SG_ H51_STK_s_Slave21BMS2REF1_2011 m53 : 47|12@0+ (1,0) [0|4095] ""  S91_FCCU1,S83_DCO,LABVIEW
 SG_ H51_STK_s_Slave21BMS1REF2_2011 m53 : 27|12@0+ (1,0) [0|4095] ""  S91_FCCU1,S83_DCO,LABVIEW
 SG_ H51_STK_s_Slave21BMS1REF1_2011 m53 : 23|12@0+ (1,0) [0|4095] ""  S91_FCCU1,S83_DCO,LABVIEW
 SG_ H51_STK_s_Slave22BMS2REF2_2011 m54 : 51|12@0+ (1,0) [0|4095] ""  S91_FCCU1,S83_DCO,LABVIEW
 SG_ H51_STK_s_Slave22BMS2REF1_2011 m54 : 47|12@0+ (1,0) [0|4095] ""  S91_FCCU1,S83_DCO,LABVIEW
 SG_ H51_STK_s_Slave22BMS1REF2_2011 m54 : 27|12@0+ (1,0) [0|4095] ""  S91_FCCU1,S83_DCO,LABVIEW
 SG_ H51_STK_s_Slave22BMS1REF1_2011 m54 : 23|12@0+ (1,0) [0|4095] ""  S91_FCCU1,S83_DCO,LABVIEW
 SG_ H51_STK_s_Slave23BMS2REF2_2011 m55 : 51|12@0+ (1,0) [0|4095] ""  S91_FCCU1,S83_DCO,LABVIEW
 SG_ H51_STK_s_Slave23BMS2REF1_2011 m55 : 47|12@0+ (1,0) [0|4095] ""  S91_FCCU1,S83_DCO,LABVIEW
 SG_ H51_STK_s_Slave23BMS1REF2_2011 m55 : 27|12@0+ (1,0) [0|4095] ""  S91_FCCU1,S83_DCO,LABVIEW
 SG_ H51_STK_s_Slave23BMS1REF1_2011 m55 : 23|12@0+ (1,0) [0|4095] ""  S91_FCCU1,S83_DCO,LABVIEW
 SG_ H51_STK_s_Slave24BMS2REF2_2011 m56 : 51|12@0+ (1,0) [0|4095] ""  S91_FCCU1,S83_DCO,LABVIEW
 SG_ H51_STK_s_Slave24BMS2REF1_2011 m56 : 47|12@0+ (1,0) [0|4095] ""  S91_FCCU1,S83_DCO,LABVIEW
 SG_ H51_STK_s_Slave24BMS1REF2_2011 m56 : 27|12@0+ (1,0) [0|4095] ""  S91_FCCU1,S83_DCO,LABVIEW
 SG_ H51_STK_s_Slave24BMS1REF1_2011 m56 : 23|12@0+ (1,0) [0|4095] ""  S91_FCCU1,S83_DCO,LABVIEW
 SG_ H51_STK_s_Slave25BMS2REF2_2011 m57 : 51|12@0+ (1,0) [0|4095] ""  S91_FCCU1,S83_DCO,LABVIEW
 SG_ H51_STK_s_Slave25BMS2REF1_2011 m57 : 47|12@0+ (1,0) [0|4095] ""  S91_FCCU1,S83_DCO,LABVIEW
 SG_ H51_STK_s_Slave25BMS1REF2_2011 m57 : 27|12@0+ (1,0) [0|4095] ""  S91_FCCU1,S83_DCO,LABVIEW
 SG_ H51_STK_s_Slave25BMS1REF1_2011 m57 : 23|12@0+ (1,0) [0|4095] ""  S91_FCCU1,S83_DCO,LABVIEW
 SG_ H51_STK_s_MasterBMS2REF2_2011 m16 : 51|12@0+ (1,0) [0|4095] ""  S91_FCCU1,S83_DCO,LABVIEW
 SG_ H51_STK_s_MasterBMS2REF1_2011 m16 : 47|12@0+ (1,0) [0|4095] ""  S91_FCCU1,S83_DCO,LABVIEW
 SG_ H51_STK_s_MasterBMS1REF2_2011 m16 : 27|12@0+ (1,0) [0|4095] ""  S91_FCCU1,S83_DCO,LABVIEW
 SG_ H51_STK_s_MasterBMS1REF1_2011 m16 : 23|12@0+ (1,0) [0|4095] ""  S91_FCCU1,S83_DCO,LABVIEW
 SG_ H51_STK_s_AmountOfFrames_2011 m16 : 8|8@1+ (1,0) [0|255] ""  S91_FCCU1,S83_DCO,LABVIEW
 SG_ H51_STK_s_FrameMux_2011 M : 0|8@1+ (1,0) [0|255] ""  S91_FCCU1,S83_DCO,LABVIEW

BO_ 522 H62_1_HLD_H2_Concentration: 8 H62_HLD
 SG_ H62_HLD_s_1_HW_Type : 61|3@1+ (1,0) [0|7] ""  S91_FCCU1,S83_DCO,LABVIEW
 SG_ H62_HLD_s_1_HW_Version : 56|5@1+ (1,0) [0|31] ""  S91_FCCU1,S83_DCO,LABVIEW
 SG_ H62_HLD_s_1_SW_Version_Main : 52|4@1+ (1,0) [0|15] ""  S91_FCCU1,S83_DCO,LABVIEW
 SG_ H62_HLD_s_1_SW_Version_Sub : 48|4@1+ (1,0) [0|15] ""  S91_FCCU1,S83_DCO,LABVIEW
 SG_ H62_HLD_s_1_Engineer_Info_3 : 40|8@1+ (1,0) [0|255] ""  S91_FCCU1,S83_DCO,LABVIEW
 SG_ H62_HLD_s_1_Engineer_Info_2 : 32|8@1+ (1,0) [0|255] ""  S91_FCCU1,S83_DCO,LABVIEW
 SG_ H62_HLD_s_1_Engineer_Info_1 : 27|5@1+ (1,0) [0|31] ""  S91_FCCU1,S83_DCO,LABVIEW
 SG_ H62_HLD_s_1_Sensor_ErrorCode : 25|2@1+ (1,0) [0|3] ""  S91_FCCU1,S83_DCO,LABVIEW
 SG_ H62_HLD_s_1_Engineer_Info_4 : 24|1@1+ (1,0) [0|1] ""  S91_FCCU1,S83_DCO,LABVIEW
 SG_ H62_HLD_s_1_H2_Concentration : 16|8@1+ (500,-5000) [-5000|123000] "ppm"  S91_FCCU1,S83_DCO,LABVIEW
 SG_ H62_HLD_s_1_SensorID : 12|4@1+ (1,0) [0|15] ""  S91_FCCU1,S83_DCO,LABVIEW
 SG_ H62_HLD_s_1_CycleCounter : 8|4@1+ (1,0) [0|15] ""  S91_FCCU1,S83_DCO,LABVIEW
 SG_ H62_HLD_s_1_CRC8 : 0|8@1+ (1,0) [0|255] ""  S91_FCCU1,S83_DCO,LABVIEW

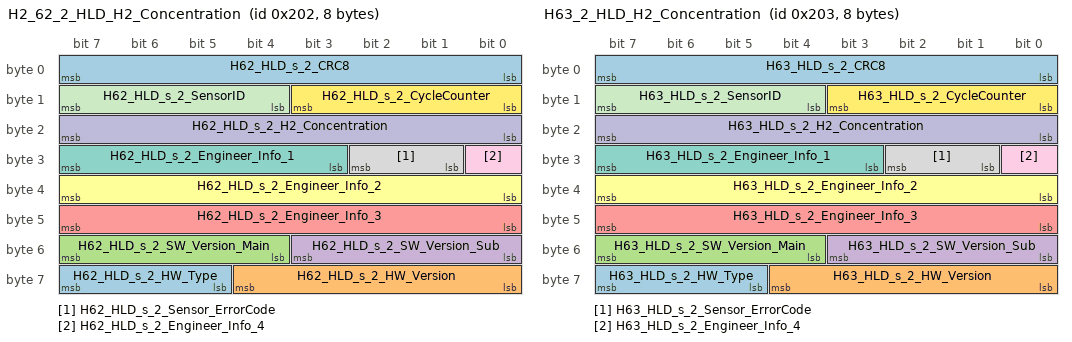
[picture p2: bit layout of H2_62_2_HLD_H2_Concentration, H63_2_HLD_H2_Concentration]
BO_ 514 H2_62_2_HLD_H2_Concentration: 8 H62_HLD
 SG_ H62_HLD_s_2_HW_Type : 61|3@1+ (1,0) [0|7] ""  S91_FCCU1,S83_DCO,LABVIEW
 SG_ H62_HLD_s_2_HW_Version : 56|5@1+ (1,0) [0|31] ""  S91_FCCU1,S83_DCO,LABVIEW
 SG_ H62_HLD_s_2_SW_Version_Main : 52|4@1+ (1,0) [0|15] ""  S91_FCCU1,S83_DCO,LABVIEW
 SG_ H62_HLD_s_2_SW_Version_Sub : 48|4@1+ (1,0) [0|15] ""  S91_FCCU1,S83_DCO,LABVIEW
 SG_ H62_HLD_s_2_Engineer_Info_3 : 40|8@1+ (1,0) [0|255] ""  S91_FCCU1,S83_DCO,LABVIEW
 SG_ H62_HLD_s_2_Engineer_Info_2 : 32|8@1+ (1,0) [0|255] ""  S91_FCCU1,S83_DCO,LABVIEW
 SG_ H62_HLD_s_2_Engineer_Info_1 : 27|5@1+ (1,0) [0|31] ""  S91_FCCU1,S83_DCO,LABVIEW
 SG_ H62_HLD_s_2_Sensor_ErrorCode : 25|2@1+ (1,0) [0|3] ""  S91_FCCU1,S83_DCO,LABVIEW
 SG_ H62_HLD_s_2_Engineer_Info_4 : 24|1@1+ (1,0) [0|1] ""  S91_FCCU1,S83_DCO,LABVIEW
 SG_ H62_HLD_s_2_H2_Concentration : 16|8@1+ (500,-5000) [-5000|123000] "ppm"  S91_FCCU1,S83_DCO,LABVIEW
 SG_ H62_HLD_s_2_SensorID : 12|4@1+ (1,0) [0|15] ""  S91_FCCU1,S83_DCO,LABVIEW
 SG_ H62_HLD_s_2_CycleCounter : 8|4@1+ (1,0) [0|15] ""  S91_FCCU1,S83_DCO,LABVIEW
 SG_ H62_HLD_s_2_CRC8 : 0|8@1+ (1,0) [0|255] ""  S91_FCCU1,S83_DCO,LABVIEW

BO_ 515 H63_2_HLD_H2_Concentration: 8 S92_FCCU2
 SG_ H63_HLD_s_2_HW_Type : 61|3@1+ (1,0) [0|7] ""  S91_FCCU1,S83_DCO,LABVIEW
 SG_ H63_HLD_s_2_HW_Version : 56|5@1+ (1,0) [0|31] ""  S91_FCCU1,S83_DCO,LABVIEW
 SG_ H63_HLD_s_2_SW_Version_Main : 52|4@1+ (1,0) [0|15] ""  S91_FCCU1,S83_DCO,LABVIEW
 SG_ H63_HLD_s_2_SW_Version_Sub : 48|4@1+ (1,0) [0|15] ""  S91_FCCU1,S83_DCO,LABVIEW
 SG_ H63_HLD_s_2_Engineer_Info_3 : 40|8@1+ (1,0) [0|255] ""  S91_FCCU1,S83_DCO,LABVIEW
 SG_ H63_HLD_s_2_Engineer_Info_2 : 32|8@1+ (1,0) [0|255] ""  S91_FCCU1,S83_DCO,LABVIEW
 SG_ H63_HLD_s_2_Engineer_Info_1 : 27|5@1+ (1,0) [0|31] ""  S91_FCCU1,S83_DCO,LABVIEW
 SG_ H63_HLD_s_2_Sensor_ErrorCode : 25|2@1+ (1,0) [0|3] ""  S91_FCCU1,S83_DCO,LABVIEW
 SG_ H63_HLD_s_2_Engineer_Info_4 : 24|1@1+ (1,0) [0|1] ""  S91_FCCU1,S83_DCO,LABVIEW
 SG_ H63_HLD_s_2_H2_Concentration : 16|8@1+ (500,-5000) [-5000|123000] "ppm"  S91_FCCU1,S83_DCO,LABVIEW
 SG_ H63_HLD_s_2_SensorID : 12|4@1+ (1,0) [0|15] ""  S91_FCCU1,S83_DCO,LABVIEW
 SG_ H63_HLD_s_2_CycleCounter : 8|4@1+ (1,0) [0|15] ""  S91_FCCU1,S83_DCO,LABVIEW
 SG_ H63_HLD_s_2_CRC8 : 0|8@1+ (1,0) [0|255] ""  S91_FCCU1,S83_DCO,LABVIEW

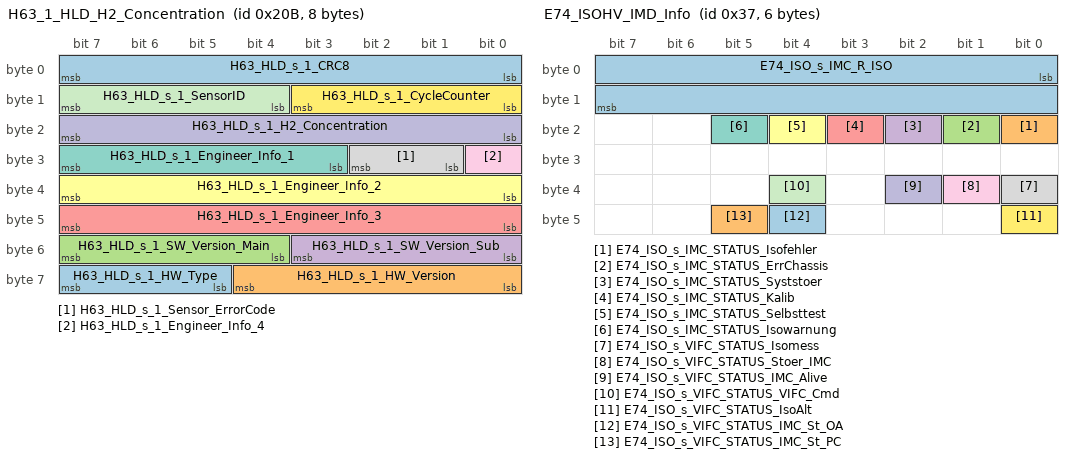
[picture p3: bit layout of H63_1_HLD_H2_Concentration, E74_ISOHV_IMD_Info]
BO_ 523 H63_1_HLD_H2_Concentration: 8 S92_FCCU2
 SG_ H63_HLD_s_1_HW_Type : 61|3@1+ (1,0) [0|7] ""  S91_FCCU1,S83_DCO,LABVIEW
 SG_ H63_HLD_s_1_HW_Version : 56|5@1+ (1,0) [0|31] ""  S91_FCCU1,S83_DCO,LABVIEW
 SG_ H63_HLD_s_1_SW_Version_Main : 52|4@1+ (1,0) [0|15] ""  S91_FCCU1,S83_DCO,LABVIEW
 SG_ H63_HLD_s_1_SW_Version_Sub : 48|4@1+ (1,0) [0|15] ""  S91_FCCU1,S83_DCO,LABVIEW
 SG_ H63_HLD_s_1_Engineer_Info_3 : 40|8@1+ (1,0) [0|255] ""  S91_FCCU1,S83_DCO,LABVIEW
 SG_ H63_HLD_s_1_Engineer_Info_2 : 32|8@1+ (1,0) [0|255] ""  S91_FCCU1,S83_DCO,LABVIEW
 SG_ H63_HLD_s_1_Engineer_Info_1 : 27|5@1+ (1,0) [0|31] ""  S91_FCCU1,S83_DCO,LABVIEW
 SG_ H63_HLD_s_1_Sensor_ErrorCode : 25|2@1+ (1,0) [0|3] ""  S91_FCCU1,S83_DCO,LABVIEW
 SG_ H63_HLD_s_1_Engineer_Info_4 : 24|1@1+ (1,0) [0|1] ""  S91_FCCU1,S83_DCO,LABVIEW
 SG_ H63_HLD_s_1_H2_Concentration : 16|8@1+ (500,-5000) [-5000|123000] "ppm"  S91_FCCU1,S83_DCO,LABVIEW
 SG_ H63_HLD_s_1_SensorID : 12|4@1+ (1,0) [0|15] ""  S91_FCCU1,S83_DCO,LABVIEW
 SG_ H63_HLD_s_1_CycleCounter : 8|4@1+ (1,0) [0|15] ""  S91_FCCU1,S83_DCO,LABVIEW
 SG_ H63_HLD_s_1_CRC8 : 0|8@1+ (1,0) [0|255] ""  S91_FCCU1,S83_DCO,LABVIEW

BO_ 0 E71_FCCU1_DCDC_NMT_REQUEST: 2 S91_FCCU1
 SG_ E71_DC4880_a_NMT_Function : 0|8@1+ (1,0) [0|255] ""  E71_DCDC,S83_DCO,LABVIEW
 SG_ E71_DC4880_a_NMT_Node_ID : 8|8@1+ (1,0) [0|255] ""  E71_DCDC,S83_DCO,LABVIEW

BO_ 513 E71_FCCU1_DCDC_UI_Set: 8 S91_FCCU1
 SG_ E71_DC4880_a_Voltage_In_Set : 0|16@1+ (0.009,0) [0|99] "V"  E71_DCDC,S83_DCO,LABVIEW
 SG_ E71_DC4880_a_Current_In_Set : 16|16@1+ (0.03,0) [0|330] "A"  E71_DCDC,S83_DCO,LABVIEW
 SG_ E71_DC4880_a_Voltage_Out_Set : 32|16@1+ (0.009,0) [0|99] "V"  E71_DCDC,S83_DCO,LABVIEW
 SG_ E71_DC4880_a_Current_Out_Set : 48|16@1+ (0.018,0) [0|198] "A"  E71_DCDC,S83_DCO,LABVIEW

BO_ 769 E71_FCCU1_DCDC_PSU_Mode: 8 S91_FCCU1
 SG_ E71_DC4880_a_Mode_Precharge_On : 0|1@1+ (1,0) [0|1] ""  E71_DCDC,S83_DCO,LABVIEW
 SG_ E71_DC4880_a_Mode_Control_On : 1|1@1+ (1,0) [0|1] ""  E71_DCDC,S83_DCO,LABVIEW

BO_ 385 E71_DCDC_UI_Actual: 8 E71_DCDC
 SG_ E71_DC4880_s_Voltage_In_Actual : 0|16@1+ (0.009,0) [0|99] "V"  S91_FCCU1,S83_DCO,LABVIEW
 SG_ E71_DC4880_s_Current_In_Actual : 16|16@1+ (0.03,0) [0|330] "A"  S91_FCCU1,S83_DCO,LABVIEW
 SG_ E71_DC4880_s_Voltage_Out_Actual : 32|16@1+ (0.009,0) [0|99] "V"  S91_FCCU1,S83_DCO,LABVIEW
 SG_ E71_DC4880_s_Current_Out_Actual : 48|16@1+ (0.018,0) [0|198] "A"  S91_FCCU1,S83_DCO,LABVIEW

BO_ 641 E71_DCDC_T_Actual: 8 E71_DCDC
 SG_ E71_DC4880_s_Temperature_1_Act : 0|16@1- (0.1,0) [-3276.8|3276.7] "°C"  S91_FCCU1,S83_DCO,LABVIEW
 SG_ E71_DC4880_s_Temperature_2_Act : 16|16@1- (0.1,0) [-3276.8|3276.7] "°C"  S91_FCCU1,S83_DCO,LABVIEW

BO_ 897 E71_DCDC_Status: 8 E71_DCDC
 SG_ E71_DC4880_s_State_Precharge_OK : 3|1@1+ (1,0) [0|1] "" Vector__XXX
 SG_ E71_DC4880_s_State_Precharge_On : 0|1@1+ (1,0) [0|1] ""  S91_FCCU1,S83_DCO,LABVIEW
 SG_ E71_DC4880_s_State_Control_On : 1|1@1+ (1,0) [0|1] ""  S91_FCCU1,S83_DCO,LABVIEW
 SG_ E71_DC4880_s_State_Control_OK : 2|1@1+ (1,0) [0|1] ""  S91_FCCU1,S83_DCO,LABVIEW

BO_ 1153 E71_DCDC_Reserved: 8 E71_DCDC

BO_ 1793 E71_DCDC_Heartbeat: 1 E71_DCDC
 SG_ E71_DC4880_s_NMT_State : 0|8@1+ (1,0) [0|255] ""  S91_FCCU1,S83_DCO,LABVIEW

BO_ 34 E74_FCCU1_ISOHV_IMD_Rq: 5 S91_FCCU1
 SG_ E74_ISO_a_CMD_Rq M : 0|8@1+ (1,0) [0|255] ""  E74_ISOHV,S83_DCO,LABVIEW
 SG_ E74_ISO_a_Rq_D_IMC_SELFTEST_SCR m33 : 8|16@1+ (1,0) [0|65535] ""  E74_ISOHV,S83_DCO,LABVIEW
 SG_ E74_ISO_a_Rq_D_IMC_R_ISOERR_THR m40 : 8|16@1+ (1,0) [30|1000] "kOhm"  E74_ISOHV,S83_DCO,LABVIEW
 SG_ E74_ISO_a_Rq_D_IMC_R_ISOWRN_THR m41 : 8|16@1+ (1,0) [40|2000] "kOhm"  E74_ISOHV,S83_DCO,LABVIEW
 SG_ E74_ISO_a_Rq_D_IMC_MEAN_FACTOR m43 : 8|16@1+ (1,0) [1|20] ""  E74_ISOHV,S83_DCO,LABVIEW
 SG_ E74_ISO_a_Rq_D_IMC_VERSION_IDX m51 : 8|16@1+ (1,0) [0|65535] ""  E74_ISOHV,S83_DCO,LABVIEW
 SG_ E74_ISO_a_Rq_D_IMC_MANUFACT_IDX m61 : 8|16@1+ (1,0) [0|60] ""  E74_ISOHV,S83_DCO,LABVIEW
 SG_ E74_ISO_a_Rq_D_VIFC_LOCK_MODE m202 : 8|16@1+ (1,0) [0|65535] ""  E74_ISOHV,S83_DCO,LABVIEW
 SG_ E74_ISO_a_Rq_D_VIFC_LOCK_PWD m202 : 24|16@1+ (1,0) [0|65535] ""  E74_ISOHV,S83_DCO,LABVIEW
 SG_ E74_ISO_a_Rq_D_VIFC_MEAS_MODE m203 : 8|16@1+ (1,0) [0|65535] ""  E74_ISOHV,S83_DCO,LABVIEW
 SG_ E74_ISO_a_Rq_D_VIFC_HV_REL_CHG m210 : 8|16@1+ (1,0) [0|65535] ""  E74_ISOHV,S83_DCO,LABVIEW
 SG_ E74_ISO_a_Rq_D_VIFC_RELAIS_STAT m210 : 24|16@1+ (1,0) [0|65535] ""  E74_ISOHV,S83_DCO,LABVIEW
 SG_ E74_ISO_a_Rq_D_VIFC_HV_RELAIS m221 : 8|16@1+ (1,0) [0|65535] ""  E74_ISOHV,S83_DCO,LABVIEW
 SG_ E74_ISO_a_Rq_D_VIFC_VERSION_IDX m222 : 8|16@1+ (1,0) [0|65535] ""  E74_ISOHV,S83_DCO,LABVIEW

BO_ 35 E74_ISOHV_IMD_Resp: 5 E74_ISOHV
 SG_ E74_ISO_s_CMD_Resp M : 0|8@1+ (1,0) [0|255] ""  S91_FCCU1,S83_DCO,LABVIEW
 SG_ E74_ISO_s_D_IMC_SELFTEST_SCR m33 : 8|16@1+ (1,0) [0|65535] ""  S91_FCCU1,S83_DCO,LABVIEW
 SG_ E74_ISO_s_D_IMC_R_ISO_ERR_THR2 m40 : 8|16@1+ (1,0) [30|1000] "kOhm"  S91_FCCU1,S83_DCO,LABVIEW
 SG_ E74_ISO_s_D_IMC_R_ISO_WRN_THR2 m41 : 8|16@1+ (1,0) [40|2000] "kOhm"  S91_FCCU1,S83_DCO,LABVIEW
 SG_ E74_ISO_s_Rq_D_IMC_MEAN_FACTOR m43 : 8|16@1+ (1,0) [1|20] ""  S91_FCCU1,S83_DCO,LABVIEW
 SG_ E74_ISO_s_D_IMC_R_ISO_ERR_THR1 m50 : 8|16@1+ (1,0) [30|1000] "kOhm"  S91_FCCU1,S83_DCO,LABVIEW
 SG_ E74_ISO_s_D_IMC_VERSION_INDEX m51 : 8|16@1+ (1,0) [0|65535] ""  S91_FCCU1,S83_DCO,LABVIEW
 SG_ E74_ISO_s_D_IMC_VERSION_Neben m51 : 24|8@1+ (1,0) [0|65535] ""  S91_FCCU1,S83_DCO,LABVIEW
 SG_ E74_ISO_s_D_IMC_VERSION_Haupt m51 : 32|8@1+ (1,0) [0|65535] ""  S91_FCCU1,S83_DCO,LABVIEW
 SG_ E74_ISO_s_D_IMC_R_ISO m53 : 8|16@1+ (1,0) [0|50000] "kOhm"  S91_FCCU1,S83_DCO,LABVIEW
 SG_ E74_ISO_s_D_IMC_R_ISO_BIAS m53 : 24|8@1+ (1,0) [0|65535] ""  S91_FCCU1,S83_DCO,LABVIEW
 SG_ E74_ISO_s_D_IMC_R_ISO_CNT m53 : 32|8@1+ (1,0) [0|255] ""  S91_FCCU1,S83_DCO,LABVIEW
 SG_ E74_ISO_s_D_IMC_STATUS m55 : 8|16@1+ (1,0) [0|65535] ""  S91_FCCU1,S83_DCO,LABVIEW
 SG_ E74_ISO_s_D_IMC_STATUS_EXT m55 : 24|16@1+ (1,0) [0|65535] ""  S91_FCCU1,S83_DCO,LABVIEW
 SG_ E74_ISO_s_D_IMC_HV_1 m54 : 8|16@1+ (1,0) [0|600] ""  S91_FCCU1,S83_DCO,LABVIEW
 SG_ E74_ISO_s_D_IMC_R_ISO_WRN_THR1 m57 : 8|16@1+ (1,0) [40|2000] "kOhm"  S91_FCCU1,S83_DCO,LABVIEW
 SG_ E74_ISO_s_D_IMC_HV_2 m58 : 8|16@1+ (1,0) [0|600] ""  S91_FCCU1,S83_DCO,LABVIEW
 SG_ E74_ISO_s_D_IMC_MEAN_FACTOR m60 : 8|16@1+ (1,0) [1|20] ""  S91_FCCU1,S83_DCO,LABVIEW
 SG_ E74_ISO_s_D_IMC_MANUFACT_INDEX m61 : 8|16@1+ (1,0) [0|60] ""  S91_FCCU1,S83_DCO,LABVIEW
 SG_ E74_ISO_s_D_IMC_MANUFACT_DATA m61 : 24|16@1+ (1,0) [0|255] ""  S91_FCCU1,S83_DCO,LABVIEW
 SG_ E74_ISO_s_D_IMC_TEST_CNT m90 : 8|16@1+ (1,0) [0|65535] ""  S91_FCCU1,S83_DCO,LABVIEW
 SG_ E74_ISO_s_D_VIFC_LOCK_MODE m202 : 8|16@1+ (1,0) [0|65535] ""  S91_FCCU1,S83_DCO,LABVIEW
 SG_ E74_ISO_s_D_VIFC_MEASURE_MODE m203 : 8|16@1+ (1,0) [0|65535] ""  S91_FCCU1,S83_DCO,LABVIEW
 SG_ E74_ISO_s_D_VIFC_HV_RELAIS_CHG m210 : 8|16@1+ (1,0) [0|65535] ""  S91_FCCU1,S83_DCO,LABVIEW
 SG_ E74_ISO_s_D_VIFC_HV_RELAIS_STAT m210 : 24|16@1+ (1,0) [0|65535] ""  S91_FCCU1,S83_DCO,LABVIEW
 SG_ E74_ISO_s_D_VIFC_STATUS m220 : 8|16@1+ (1,0) [0|65535] ""  S91_FCCU1,S83_DCO,LABVIEW
 SG_ E74_ISO_s_D_VIFC_HV_RELAIS m221 : 8|16@1+ (1,0) [0|65535] ""  S91_FCCU1,S83_DCO,LABVIEW
 SG_ E74_ISO_s_D_VIFC_HV_RELAIS_ACT m221 : 24|16@1+ (1,0) [0|65535] ""  S91_FCCU1,S83_DCO,LABVIEW
 SG_ E74_ISO_s_D_VIFC_VERSION_INDEX m222 : 8|16@1+ (1,0) [0|65535] ""  S91_FCCU1,S83_DCO,LABVIEW
 SG_ E74_ISO_s_D_VIFC_VERSION_Neben m222 : 24|8@1+ (1,0) [0|65535] ""  S91_FCCU1,S83_DCO,LABVIEW
 SG_ E74_ISO_s_D_VIFC_VERSION_Haupt m222 : 32|8@1+ (1,0) [0|65535] ""  S91_FCCU1,S83_DCO,LABVIEW
 SG_ E74_ISO_s_D_VIFC_IMC_ALIVE m226 : 8|16@1+ (1,0) [0|65535] ""  S91_FCCU1,S83_DCO,LABVIEW
 SG_ E74_ISO_s_D_IMD_ERROR_CODE m255 : 8|16@1+ (1,0) [0|65535] ""  S91_FCCU1,S83_DCO,LABVIEW
 SG_ E74_ISO_s_D_IMD_FAILED_CMD m255 : 24|8@1+ (1,0) [0|255] ""  S91_FCCU1,S83_DCO,LABVIEW

BO_ 55 E74_ISOHV_IMD_Info: 6 E74_ISOHV
 SG_ E74_ISO_s_IMC_R_ISO : 0|16@1+ (1,0) [0|50000] "kOhm"  S91_FCCU1,S83_DCO,LABVIEW
 SG_ E74_ISO_s_IMC_STATUS_Isofehler : 16|1@1+ (1,0) [0|1] ""  S91_FCCU1,S83_DCO,LABVIEW
 SG_ E74_ISO_s_IMC_STATUS_ErrChassis : 17|1@1+ (1,0) [0|1] ""  S91_FCCU1,S83_DCO,LABVIEW
 SG_ E74_ISO_s_IMC_STATUS_Syststoer : 18|1@1+ (1,0) [0|1] ""  S91_FCCU1,S83_DCO,LABVIEW
 SG_ E74_ISO_s_IMC_STATUS_Kalib : 19|1@1+ (1,0) [0|1] ""  S91_FCCU1,S83_DCO,LABVIEW
 SG_ E74_ISO_s_IMC_STATUS_Selbsttest : 20|1@1+ (1,0) [0|1] ""  S91_FCCU1,S83_DCO,LABVIEW
 SG_ E74_ISO_s_IMC_STATUS_Isowarnung : 21|1@1+ (1,0) [0|1] ""  S91_FCCU1,S83_DCO,LABVIEW
 SG_ E74_ISO_s_VIFC_STATUS_Isomess : 32|1@1+ (1,0) [0|1] ""  S91_FCCU1,S83_DCO,LABVIEW
 SG_ E74_ISO_s_VIFC_STATUS_Stoer_IMC : 33|1@1+ (1,0) [0|1] ""  S91_FCCU1,S83_DCO,LABVIEW
 SG_ E74_ISO_s_VIFC_STATUS_IMC_Alive : 34|1@1+ (1,0) [0|1] ""  S91_FCCU1,S83_DCO,LABVIEW
 SG_ E74_ISO_s_VIFC_STATUS_VIFC_Cmd : 36|1@1+ (1,0) [0|1] ""  S91_FCCU1,S83_DCO,LABVIEW
 SG_ E74_ISO_s_VIFC_STATUS_IsoAlt : 40|1@1+ (1,0) [0|1] ""  S91_FCCU1,S83_DCO,LABVIEW
 SG_ E74_ISO_s_VIFC_STATUS_IMC_St_OA : 44|1@1+ (1,0) [0|1] ""  S91_FCCU1,S83_DCO,LABVIEW
 SG_ E74_ISO_s_VIFC_STATUS_IMC_St_PC : 45|1@1+ (1,0) [0|1] ""  S91_FCCU1,S83_DCO,LABVIEW

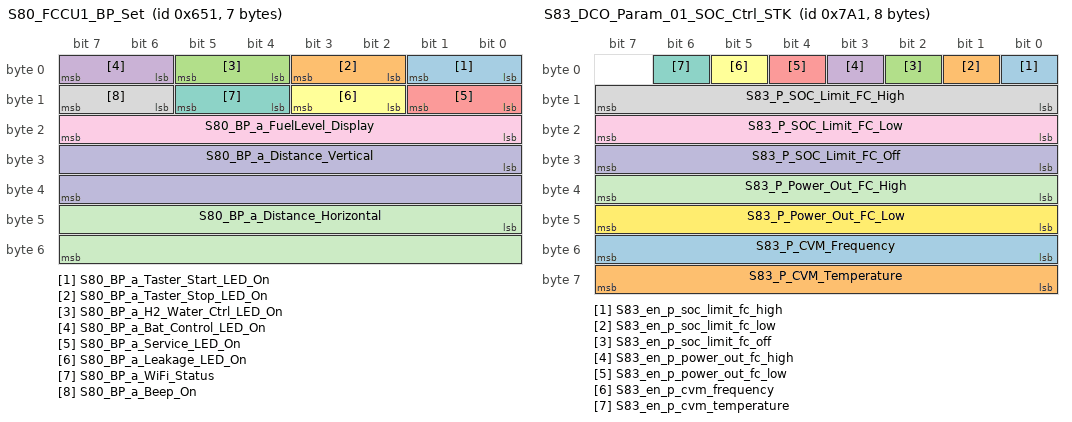
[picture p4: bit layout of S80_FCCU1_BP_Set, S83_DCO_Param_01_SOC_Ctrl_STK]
BO_ 1617 S80_FCCU1_BP_Set: 7 S91_FCCU1
 SG_ S80_BP_a_Taster_Start_LED_On : 0|2@1+ (1,0) [0|3] ""  S80_BP,S83_DCO,LABVIEW
 SG_ S80_BP_a_Taster_Stop_LED_On : 2|2@1+ (1,0) [0|3] ""  S80_BP,S83_DCO,LABVIEW
 SG_ S80_BP_a_H2_Water_Ctrl_LED_On : 4|2@1+ (1,0) [0|3] ""  S80_BP,S83_DCO,LABVIEW
 SG_ S80_BP_a_Bat_Control_LED_On : 6|2@1+ (1,0) [0|3] ""  S80_BP,S83_DCO,LABVIEW
 SG_ S80_BP_a_Service_LED_On : 8|2@1+ (1,0) [0|3] ""  S80_BP,S83_DCO,LABVIEW
 SG_ S80_BP_a_Leakage_LED_On : 10|2@1+ (1,0) [0|3] ""  S80_BP,S83_DCO,LABVIEW
 SG_ S80_BP_a_WiFi_Status : 12|2@1+ (1,0) [0|3] ""  S80_BP,S83_DCO,LABVIEW
 SG_ S80_BP_a_Beep_On : 14|2@1+ (1,0) [0|3] ""  S80_BP,S83_DCO,LABVIEW
 SG_ S80_BP_a_FuelLevel_Display : 16|8@1+ (1,0) [0|8] ""  S80_BP,S83_DCO,LABVIEW
 SG_ S80_BP_a_Distance_Vertical : 24|16@1+ (1,0) [0|65535] "min"  S80_BP,S83_DCO,LABVIEW
 SG_ S80_BP_a_Distance_Horizontal : 40|16@1+ (1,0) [0|65535] "min"  S80_BP,S83_DCO,LABVIEW

BO_ 1616 S80_BP_Switches: 1 S80_BP
 SG_ S80_BP_s_Taster_Start_Status : 0|1@1+ (1,0) [0|1] ""  S91_FCCU1,S83_DCO,LABVIEW
 SG_ S80_BP_s_Taster_Stop_Status : 1|1@1+ (1,0) [0|1] ""  S91_FCCU1,S83_DCO,LABVIEW

BO_ 1667 S83_DCO_Wifi: 1 S83_DCO
 SG_ S83_DCO_s_Wifi_Status : 0|1@1+ (1,0) [0|1] ""  S91_FCCU1

BO_ 1953 S83_DCO_Param_01_SOC_Ctrl_STK: 8 S83_DCO
 SG_ S83_en_p_soc_limit_fc_high : 0|1@1+ (1,0) [0|1] ""  S91_FCCU1
 SG_ S83_en_p_soc_limit_fc_low : 1|1@1+ (1,0) [0|1] ""  S91_FCCU1
 SG_ S83_en_p_soc_limit_fc_off : 2|1@1+ (1,0) [0|1] ""  S91_FCCU1
 SG_ S83_en_p_power_out_fc_high : 3|1@1+ (1,0) [0|1] ""  S91_FCCU1
 SG_ S83_en_p_power_out_fc_low : 4|1@1+ (1,0) [0|1] ""  S91_FCCU1
 SG_ S83_en_p_cvm_frequency : 5|1@1+ (1,0) [0|1] ""  S91_FCCU1
 SG_ S83_en_p_cvm_temperature : 6|1@1+ (1,0) [0|1] ""  S91_FCCU1
 SG_ S83_P_SOC_Limit_FC_High : 8|8@1+ (1,0) [0|100] "%"  S91_FCCU1
 SG_ S83_P_SOC_Limit_FC_Low : 16|8@1+ (1,0) [0|100] "%"  S91_FCCU1
 SG_ S83_P_SOC_Limit_FC_Off : 24|8@1+ (1,0) [0|100] "%"  S91_FCCU1
 SG_ S83_P_Power_Out_FC_High : 32|8@1+ (1,0) [0|255] "A"  S91_FCCU1
 SG_ S83_P_Power_Out_FC_Low : 40|8@1+ (1,0) [0|255] "A"  S91_FCCU1
 SG_ S83_P_CVM_Frequency : 48|8@1+ (1,0) [0|255] "Hz"  S91_FCCU1
 SG_ S83_P_CVM_Temperature : 56|8@1+ (1,0) [0|255] "°C"  S91_FCCU1

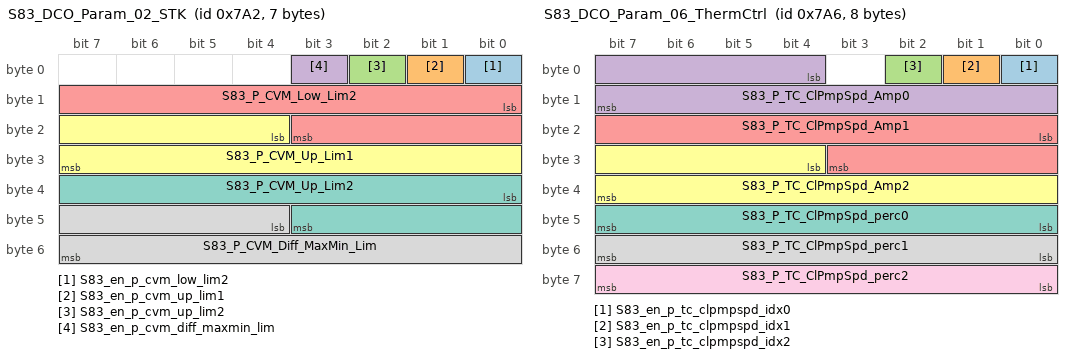
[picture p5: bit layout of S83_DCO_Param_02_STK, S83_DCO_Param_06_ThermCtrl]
BO_ 1954 S83_DCO_Param_02_STK: 7 S83_DCO
 SG_ S83_en_p_cvm_low_lim2 : 0|1@1+ (1,0) [0|1] ""  S91_FCCU1
 SG_ S83_en_p_cvm_up_lim1 : 1|1@1+ (1,0) [0|1] ""  S91_FCCU1
 SG_ S83_en_p_cvm_up_lim2 : 2|1@1+ (1,0) [0|1] ""  S91_FCCU1
 SG_ S83_en_p_cvm_diff_maxmin_lim : 3|1@1+ (1,0) [0|1] ""  S91_FCCU1
 SG_ S83_P_CVM_Low_Lim2 : 8|12@1+ (0.001,0) [0|4.095] "V"  S91_FCCU1
 SG_ S83_P_CVM_Up_Lim1 : 20|12@1+ (0.001,0) [0|4.095] "V"  S91_FCCU1
 SG_ S83_P_CVM_Up_Lim2 : 32|12@1+ (0.001,0) [0|4.095] "V"  S91_FCCU1
 SG_ S83_P_CVM_Diff_MaxMin_Lim : 44|12@1+ (0.001,0) [0|4.095] "V"  S91_FCCU1

BO_ 1955 S83_DCO_Param_03_HRBO: 6 S83_DCO
 SG_ S83_en_p_hrbo_a_valve_ot_fact : 0|1@1+ (1,0) [0|1] ""  S91_FCCU1
 SG_ S83_en_p_hrbo_a_valve_i_fact : 1|1@1+ (1,0) [0|1] ""  S91_FCCU1
 SG_ S83_en_p_hrbo_a_valve_async_fact : 2|1@1+ (1,0) [0|1] ""  S91_FCCU1
 SG_ S83_P_HRBo_a_Valve_OT_fact : 8|16@1+ (0.001,0) [0|10] ""  S91_FCCU1
 SG_ S83_P_HRBo_a_Valve_I_fact : 24|16@1+ (0.001,0) [0|10] ""  S91_FCCU1
 SG_ S83_P_HRBo_a_Valve_Async_fact : 40|1@1+ (1,0) [0|1] ""  S91_FCCU1

BO_ 1956 S83_DCO_Param_04_RFCtrl: 4 S83_DCO
 SG_ S83_en_p_rfc_nrmopbaseval_fanspd : 0|1@1+ (1,0) [0|1] ""  S91_FCCU1
 SG_ S83_en_p_rfc_srtstpvent_fanspd : 1|1@1+ (1,0) [0|1] ""  S91_FCCU1
 SG_ S83_en_p_rfc_hghvent_fanspd : 2|1@1+ (1,0) [0|1] ""  S91_FCCU1
 SG_ S83_P_RFC_NrmOpBaseVal_FanSpd : 8|8@1+ (1,0) [0|100] "%"  S91_FCCU1
 SG_ S83_P_RFC_SrtStpVent_FanSpd : 16|8@1+ (1,0) [0|100] "%"  S91_FCCU1
 SG_ S83_P_RFC_HghVent_FanSpd : 24|8@1+ (1,0) [0|100] "%"  S91_FCCU1

BO_ 1957 S83_DCO_Param_05_ThermCtrl: 8 S83_DCO
 SG_ S83_P_TC_StkIntT_P_Crtl_FanSpd : 0|32@1+ (1E-006,0) [0|4294.967295] ""  S91_FCCU1
 SG_ S83_P_TC_StkIntT_I_Crtl_FanSpd : 32|32@1+ (1E-006,0) [0|4294.967295] ""  S91_FCCU1

BO_ 1958 S83_DCO_Param_06_ThermCtrl: 8 S83_DCO
 SG_ S83_en_p_tc_clpmpspd_idx0 : 0|1@1+ (1,0) [0|1] ""  S91_FCCU1
 SG_ S83_en_p_tc_clpmpspd_idx1 : 1|1@1+ (1,0) [0|1] ""  S91_FCCU1
 SG_ S83_en_p_tc_clpmpspd_idx2 : 2|1@1+ (1,0) [0|1] ""  S91_FCCU1
 SG_ S83_P_TC_ClPmpSpd_Amp0 : 4|12@1+ (1,0) [0|511] "A"  S91_FCCU1
 SG_ S83_P_TC_ClPmpSpd_Amp1 : 16|12@1+ (1,0) [0|511] "A"  S91_FCCU1
 SG_ S83_P_TC_ClPmpSpd_Amp2 : 28|12@1+ (1,0) [0|511] "A"  S91_FCCU1
 SG_ S83_P_TC_ClPmpSpd_perc0 : 40|8@1+ (1,0) [0|100] "%"  S91_FCCU1
 SG_ S83_P_TC_ClPmpSpd_perc1 : 48|8@1+ (1,0) [0|100] "%"  S91_FCCU1
 SG_ S83_P_TC_ClPmpSpd_perc2 : 56|8@1+ (1,0) [0|100] "%"  S91_FCCU1

BO_ 1959 S83_DCO_Param_07_ThermCtrl: 7 S83_DCO
 SG_ S83_en_P_TC_OTV_maxtankpress : 0|1@1+ (1,0) [0|1] ""  S91_FCCU1
 SG_ S83_en_P_TC_GHU_maxlowpress : 1|1@1+ (1,0) [0|1] ""  S91_FCCU1
 SG_ S83_en_P_TC_GHU_maxmidpress : 2|1@1+ (1,0) [0|1] ""  S91_FCCU1
 SG_ S83_P_TC_OTV_MaxTankPress : 8|16@1+ (100,0) [0|100000] "kPa"  S91_FCCU1
 SG_ S83_P_TC_GHU_MaxLowPress : 24|16@1+ (1,0) [0|4100] "kPa"  S91_FCCU1
 SG_ S83_P_TC_GHU_MaxMidPress : 40|16@1+ (1,0) [0|2500] "kPa"  S91_FCCU1

BO_ 1960 S83_DCO_Param_08_PowCtrl: 4 S83_DCO
 SG_ S83_en_p_pc_uirangecell_volt : 0|1@1+ (1,0) [0|1] ""  S91_FCCU1
 SG_ S83_en_p_pc_uirangecell_time : 1|1@1+ (1,0) [0|1] ""  S91_FCCU1
 SG_ S83_P_PC_UIrangeCell_Volt : 8|16@1+ (0.001,0) [0|65.535] "V"  S91_FCCU1
 SG_ S83_P_PC_UIrangeCell_Time : 24|8@1+ (0.1,0) [0|25.5] "s"  S91_FCCU1

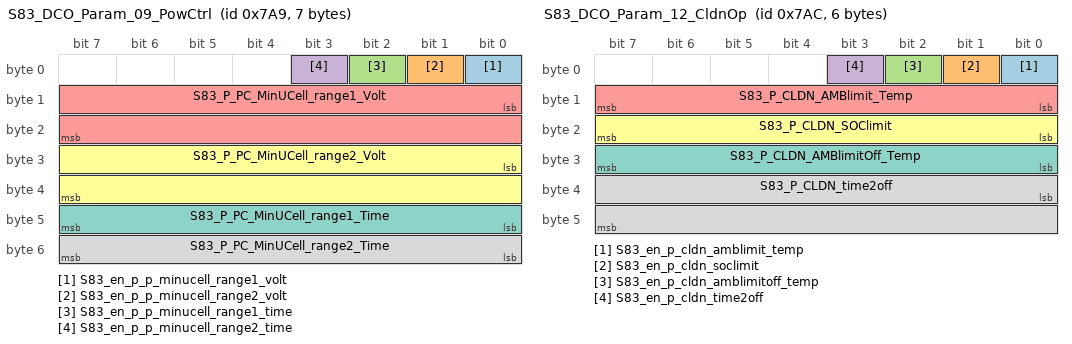
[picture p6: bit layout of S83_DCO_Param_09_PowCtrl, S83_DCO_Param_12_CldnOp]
BO_ 1961 S83_DCO_Param_09_PowCtrl: 7 S83_DCO
 SG_ S83_en_p_p_minucell_range1_volt : 0|1@1+ (1,0) [0|1] ""  S91_FCCU1
 SG_ S83_en_p_p_minucell_range2_volt : 1|1@1+ (1,0) [0|1] ""  S91_FCCU1
 SG_ S83_en_p_p_minucell_range1_time : 2|1@1+ (1,0) [0|1] ""  S91_FCCU1
 SG_ S83_en_p_p_minucell_range2_time : 3|1@1+ (1,0) [0|1] ""  S91_FCCU1
 SG_ S83_P_PC_MinUCell_range1_Volt : 8|16@1+ (0.001,0) [0|65.535] "V"  S91_FCCU1
 SG_ S83_P_PC_MinUCell_range2_Volt : 24|16@1+ (0.001,0) [0|65.535] "V"  S91_FCCU1
 SG_ S83_P_PC_MinUCell_range1_Time : 40|8@1+ (0.1,0) [0|25.5] "s"  S91_FCCU1
 SG_ S83_P_PC_MinUCell_range2_Time : 48|8@1+ (0.1,0) [0|25.5] "s"  S91_FCCU1

BO_ 1962 S83_DCO_Param_10_WtlCtrl: 4 S83_DCO
 SG_ S83_en_p_wtlc_soc_lvl_perc : 0|1@1+ (1,0) [0|1] ""  S91_FCCU1
 SG_ S83_en_p_wtlc_soc_time2off_sec : 1|1@1+ (1,0) [0|1] ""  S91_FCCU1
 SG_ S83_P_WTLC_SOC_Lvl : 8|8@1+ (1,0) [0|100] "%"  S91_FCCU1
 SG_ S83_P_WTLC_SOC_time2off : 16|16@1+ (0.1,0) [0|6553.5] "s"  S91_FCCU1

BO_ 1963 S83_DCO_Param_11_CldnOp: 5 S83_DCO
 SG_ S83_en_p_cldn_rf_spd : 0|1@1+ (1,0) [0|1] ""  S91_FCCU1
 SG_ S83_en_p_cldn_rf_time : 1|1@1+ (1,0) [0|1] ""  S91_FCCU1
 SG_ S83_en_p_cldn_cp_spd : 2|1@1+ (1,0) [0|1] ""  S91_FCCU1
 SG_ S83_P_CLDN_RF_Spd : 8|8@1+ (1,0) [0|100] "%"  S91_FCCU1
 SG_ S83_P_CLDN_RF_Time : 16|16@1+ (0.1,0) [0|6553.5] "s"  S91_FCCU1
 SG_ S83_P_CLDN_CP_Spd : 32|8@1+ (1,0) [0|100] "%"  S91_FCCU1

BO_ 1964 S83_DCO_Param_12_CldnOp: 6 S83_DCO
 SG_ S83_en_p_cldn_amblimit_temp : 0|1@1+ (1,0) [0|1] ""  S91_FCCU1
 SG_ S83_en_p_cldn_soclimit : 1|1@1+ (1,0) [0|1] ""  S91_FCCU1
 SG_ S83_en_p_cldn_amblimitoff_temp : 2|1@1+ (1,0) [0|1] ""  S91_FCCU1
 SG_ S83_en_p_cldn_time2off : 3|1@1+ (1,0) [0|1] ""  S91_FCCU1
 SG_ S83_P_CLDN_AMBlimit_Temp : 8|8@1+ (1,-40) [-40|215] "°C"  S91_FCCU1
 SG_ S83_P_CLDN_SOClimit : 16|8@1+ (1,0) [0|100] "%"  S91_FCCU1
 SG_ S83_P_CLDN_AMBlimitOff_Temp : 24|8@1+ (1,-40) [-40|215] "°C"  S91_FCCU1
 SG_ S83_P_CLDN_time2off : 32|16@1+ (0.1,0) [0|6553.5] "s"  S91_FCCU1

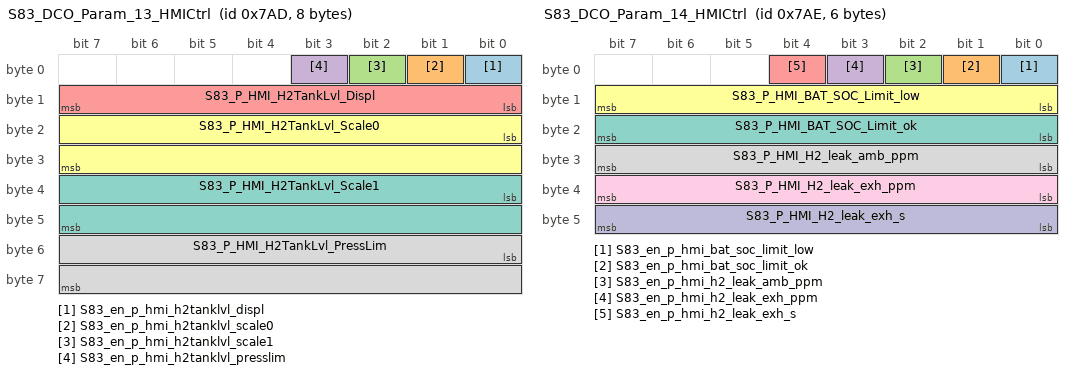
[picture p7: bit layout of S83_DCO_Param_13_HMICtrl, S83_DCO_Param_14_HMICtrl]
BO_ 1965 S83_DCO_Param_13_HMICtrl: 8 S83_DCO
 SG_ S83_en_p_hmi_h2tanklvl_displ : 0|1@1+ (1,0) [0|1] ""  S91_FCCU1
 SG_ S83_en_p_hmi_h2tanklvl_scale0 : 1|1@1+ (1,0) [0|1] ""  S91_FCCU1
 SG_ S83_en_p_hmi_h2tanklvl_scale1 : 2|1@1+ (1,0) [0|1] ""  S91_FCCU1
 SG_ S83_en_p_hmi_h2tanklvl_presslim : 3|1@1+ (1,0) [0|1] ""  S91_FCCU1
 SG_ S83_P_HMI_H2TankLvl_Displ : 8|8@1+ (1,0) [0|100] "%"  S91_FCCU1
 SG_ S83_P_HMI_H2TankLvl_Scale0 : 16|16@1+ (100,0) [0|100000] "kPa"  S91_FCCU1
 SG_ S83_P_HMI_H2TankLvl_Scale1 : 32|16@1+ (100,0) [0|100000] "kPa"  S91_FCCU1
 SG_ S83_P_HMI_H2TankLvl_PressLim : 48|16@1+ (100,0) [0|100000] "kPa"  S91_FCCU1

BO_ 1966 S83_DCO_Param_14_HMICtrl: 6 S83_DCO
 SG_ S83_en_p_hmi_bat_soc_limit_low : 0|1@1+ (1,0) [0|1] ""  S91_FCCU1
 SG_ S83_en_p_hmi_bat_soc_limit_ok : 1|1@1+ (1,0) [0|1] ""  S91_FCCU1
 SG_ S83_en_p_hmi_h2_leak_amb_ppm : 2|1@1+ (1,0) [0|1] ""  S91_FCCU1
 SG_ S83_en_p_hmi_h2_leak_exh_ppm : 3|1@1+ (1,0) [0|1] ""  S91_FCCU1
 SG_ S83_en_p_hmi_h2_leak_exh_s : 4|1@1+ (1,0) [0|1] ""  S91_FCCU1
 SG_ S83_P_HMI_BAT_SOC_Limit_low : 8|8@1+ (1,0) [0|100] "%"  S91_FCCU1
 SG_ S83_P_HMI_BAT_SOC_Limit_ok : 16|8@1+ (1,0) [0|100] "%"  S91_FCCU1
 SG_ S83_P_HMI_H2_leak_amb_ppm : 24|8@1+ (500,-5000) [-5000|123000] "ppm"  S91_FCCU1
 SG_ S83_P_HMI_H2_leak_exh_ppm : 32|8@1+ (500,-5000) [-5000|123000] "ppm"  S91_FCCU1
 SG_ S83_P_HMI_H2_leak_exh_s : 40|8@1+ (0.1,0) [0|25.5] "s"  S91_FCCU1

BO_ 1967 S83_DCO_Param_15_SysPwrDn: 5 S83_DCO
 SG_ S83_en_p_spdn_batlimit_curr : 0|1@1+ (1,0) [0|1] ""  S91_FCCU1
 SG_ S83_en_p_spdn_batlimit_time : 1|1@1+ (1,0) [0|1] ""  S91_FCCU1
 SG_ S83_P_SPDN_BATlimit_Curr : 8|16@1+ (0.1,-3276.8) [-3276.8|3276.7] "A"  S91_FCCU1
 SG_ S83_P_SPDN_BATlimit_Time : 24|16@1+ (0.1,0) [0|6553.5] "s"  S91_FCCU1

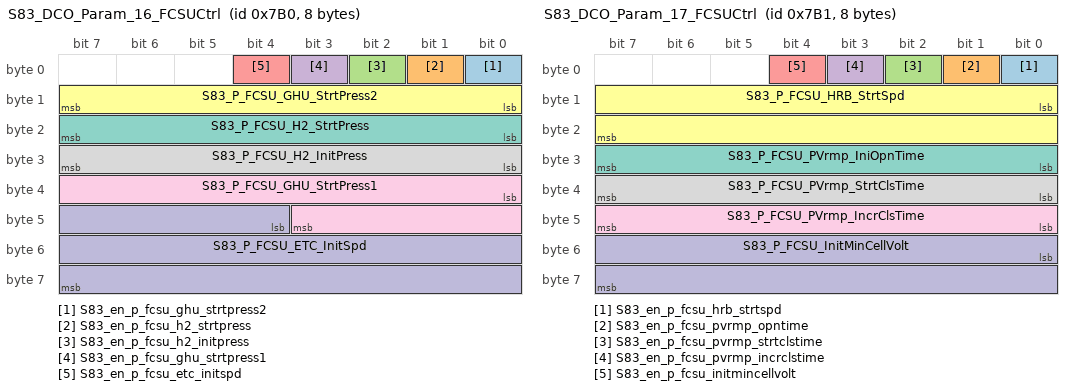
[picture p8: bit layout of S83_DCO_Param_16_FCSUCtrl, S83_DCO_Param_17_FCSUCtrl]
BO_ 1968 S83_DCO_Param_16_FCSUCtrl: 8 S83_DCO
 SG_ S83_en_p_fcsu_ghu_strtpress2 : 0|1@1+ (1,0) [0|1] ""  S91_FCCU1
 SG_ S83_en_p_fcsu_h2_strtpress : 1|1@1+ (1,0) [0|1] ""  S91_FCCU1
 SG_ S83_en_p_fcsu_h2_initpress : 2|1@1+ (1,0) [0|1] ""  S91_FCCU1
 SG_ S83_en_p_fcsu_ghu_strtpress1 : 3|1@1+ (1,0) [0|1] ""  S91_FCCU1
 SG_ S83_en_p_fcsu_etc_initspd : 4|1@1+ (1,0) [0|1] ""  S91_FCCU1
 SG_ S83_P_FCSU_GHU_StrtPress2 : 8|8@1+ (1,0) [0|255] "kPa"  S91_FCCU1
 SG_ S83_P_FCSU_H2_StrtPress : 16|8@1+ (1,0) [0|255] "kPa"  S91_FCCU1
 SG_ S83_P_FCSU_H2_InitPress : 24|8@1+ (1,0) [0|255] "kPa"  S91_FCCU1
 SG_ S83_P_FCSU_GHU_StrtPress1 : 32|12@1+ (1,0) [0|2500] "kPa"  S91_FCCU1
 SG_ S83_P_FCSU_ETC_InitSpd : 44|20@1+ (1,0) [0|1048575] "rpm"  S91_FCCU1

BO_ 1969 S83_DCO_Param_17_FCSUCtrl: 8 S83_DCO
 SG_ S83_en_p_fcsu_hrb_strtspd : 0|1@1+ (1,0) [0|1] ""  S91_FCCU1
 SG_ S83_en_p_fcsu_pvrmp_opntime : 1|1@1+ (1,0) [0|1] ""  S91_FCCU1
 SG_ S83_en_p_fcsu_pvrmp_strtclstime : 2|1@1+ (1,0) [0|1] ""  S91_FCCU1
 SG_ S83_en_p_fcsu_pvrmp_incrclstime : 3|1@1+ (1,0) [0|1] ""  S91_FCCU1
 SG_ S83_en_p_fcsu_initmincellvolt : 4|1@1+ (1,0) [0|1] ""  S91_FCCU1
 SG_ S83_P_FCSU_HRB_StrtSpd : 8|16@1+ (1,0) [0|25000] "rpm"  S91_FCCU1
 SG_ S83_P_FCSU_PVrmp_IniOpnTime : 24|8@1+ (0.1,0) [0|25.5] "s"  S91_FCCU1
 SG_ S83_P_FCSU_PVrmp_StrtClsTime : 32|8@1+ (0.1,0) [0|25.5] "s"  S91_FCCU1
 SG_ S83_P_FCSU_PVrmp_IncrClsTime : 40|8@1+ (0.1,0) [0|25.5] "s"  S91_FCCU1
 SG_ S83_P_FCSU_InitMinCellVolt : 48|16@1+ (0.001,0) [0|65.535] "V"  S91_FCCU1

BO_ 1970 S83_DCO_Param_18_FCSUCtrl: 8 S83_DCO
 SG_ S83_P_FCSU_H2_Press_P_Ctrl : 0|32@1+ (1E-006,0) [0|4294.967295] ""  S91_FCCU1
 SG_ S83_P_FCSU_H2_Press_I_Ctrl : 32|32@1+ (1E-006,0) [0|4294.967295] ""  S91_FCCU1

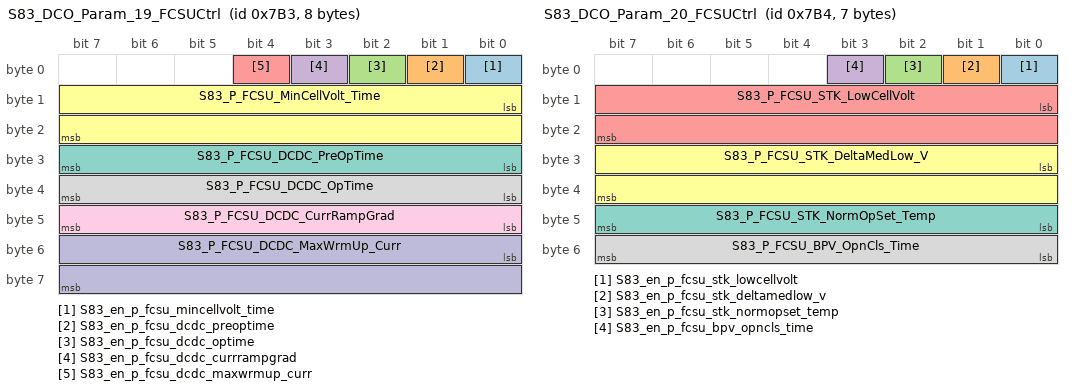
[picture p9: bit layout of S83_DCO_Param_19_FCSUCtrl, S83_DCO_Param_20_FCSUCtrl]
BO_ 1971 S83_DCO_Param_19_FCSUCtrl: 8 S83_DCO
 SG_ S83_en_p_fcsu_mincellvolt_time : 0|1@1+ (1,0) [0|1] ""  S91_FCCU1
 SG_ S83_en_p_fcsu_dcdc_preoptime : 1|1@1+ (1,0) [0|1] ""  S91_FCCU1
 SG_ S83_en_p_fcsu_dcdc_optime : 2|1@1+ (1,0) [0|1] ""  S91_FCCU1
 SG_ S83_en_p_fcsu_dcdc_currrampgrad : 3|1@1+ (1,0) [0|1] ""  S91_FCCU1
 SG_ S83_en_p_fcsu_dcdc_maxwrmup_curr : 4|1@1+ (1,0) [0|1] ""  S91_FCCU1
 SG_ S83_P_FCSU_MinCellVolt_Time : 8|16@1+ (0.1,0) [0|6553.5] "s"  S91_FCCU1
 SG_ S83_P_FCSU_DCDC_PreOpTime : 24|8@1+ (0.1,0) [0|25.5] "s"  S91_FCCU1
 SG_ S83_P_FCSU_DCDC_OpTime : 32|8@1+ (0.1,0) [0|25.5] "s"  S91_FCCU1
 SG_ S83_P_FCSU_DCDC_CurrRampGrad : 40|8@1+ (0.1,0) [0|25.5] "A/s"  S91_FCCU1
 SG_ S83_P_FCSU_DCDC_MaxWrmUp_Curr : 48|16@1+ (0.1,0) [0|6553.5] "A"  S91_FCCU1

BO_ 1972 S83_DCO_Param_20_FCSUCtrl: 7 S83_DCO
 SG_ S83_en_p_fcsu_stk_lowcellvolt : 0|1@1+ (1,0) [0|1] ""  S91_FCCU1
 SG_ S83_en_p_fcsu_stk_deltamedlow_v : 1|1@1+ (1,0) [0|1] ""  S91_FCCU1
 SG_ S83_en_p_fcsu_stk_normopset_temp : 2|1@1+ (1,0) [0|1] ""  S91_FCCU1
 SG_ S83_en_p_fcsu_bpv_opncls_time : 3|1@1+ (1,0) [0|1] ""  S91_FCCU1
 SG_ S83_P_FCSU_STK_LowCellVolt : 8|16@1+ (0.001,0) [0|65.535] "V"  S91_FCCU1
 SG_ S83_P_FCSU_STK_DeltaMedLow_V : 24|16@1+ (0.001,0) [0|65.535] "V"  S91_FCCU1
 SG_ S83_P_FCSU_STK_NormOpSet_Temp : 40|8@1+ (1,-40) [-40|215] "°C"  S91_FCCU1
 SG_ S83_P_FCSU_BPV_OpnCls_Time : 48|8@1+ (0.1,0) [0|25.5] "s"  S91_FCCU1

BO_ 1973 S83_DCO_Param_21_FCSDCtrl: 8 S83_DCO
 SG_ S83_en_p_fcsd_h2end_press : 0|1@1+ (1,0) [0|1] ""  S91_FCCU1
 SG_ S83_en_p_fcsd_hrbstp_spd : 1|1@1+ (1,0) [0|1] ""  S91_FCCU1
 SG_ S83_en_p_fcsd_etc_initrng_spd : 2|1@1+ (1,0) [0|1] ""  S91_FCCU1
 SG_ S83_P_FCSD_H2end_Press : 8|16@1+ (1,0) [0|400] "kPa"  S91_FCCU1
 SG_ S83_P_FCSD_HRBstp_Spd : 24|16@1+ (1,0) [0|25000] "rpm"  S91_FCCU1
 SG_ S83_P_FCSD_ETC_InitRng_Spd : 40|24@1+ (1,0) [0|16777215] "rpm"  S91_FCCU1

BO_ 1974 S83_DCO_Param_22_FCDU_FCA: 4 S83_DCO
 SG_ S83_en_p_fcdu_stk_curr_ramp_time : 0|1@1+ (1,0) [0|1] ""  S91_FCCU1
 SG_ S83_en_p_fca_etc_preset_gradient : 1|1@1+ (1,0) [0|1] ""  S91_FCCU1
 SG_ S83_P_FCDU_STK_Curr_Ramp_Time : 8|8@1+ (1,0) [0|255] "s"  S91_FCCU1
 SG_ S83_P_FCA_ETC_Preset_Gradient : 16|16@1+ (1,0) [0|65535] "rpm/s"  S91_FCCU1

BO_ 1975 S83_DCO_Param_23_FCA_Press_PI: 8 S83_DCO
 SG_ S83_P_FCA_Press_P_Ctrl : 0|32@1+ (1E-006,0) [0|4294.967295] ""  S91_FCCU1
 SG_ S83_P_FCA_Press_I_Ctrl : 32|32@1+ (1E-006,0) [0|4294.967295] ""  S91_FCCU1

BO_ 1976 S83_DCO_Param_24_FCA_D: 8 S83_DCO
 SG_ S83_P_FCA_Press_D_Ctrl : 0|32@1+ (1E-006,0) [0|4294.967295] ""  S91_FCCU1
 SG_ S83_P_FCA_Speed_D_Ctrl : 32|32@1+ (1E-006,0) [0|4294.967295] ""  S91_FCCU1

BO_ 1977 S83_DCO_Param_25_FCA_Speed_PI: 8 S83_DCO
 SG_ S83_P_FCA_Speed_P_Ctrl : 0|32@1+ (1E-006,0) [0|4294.967295] ""  S91_FCCU1
 SG_ S83_P_FCA_Speed_I_Ctrl : 32|32@1+ (1E-006,0) [0|4294.967295] ""  S91_FCCU1

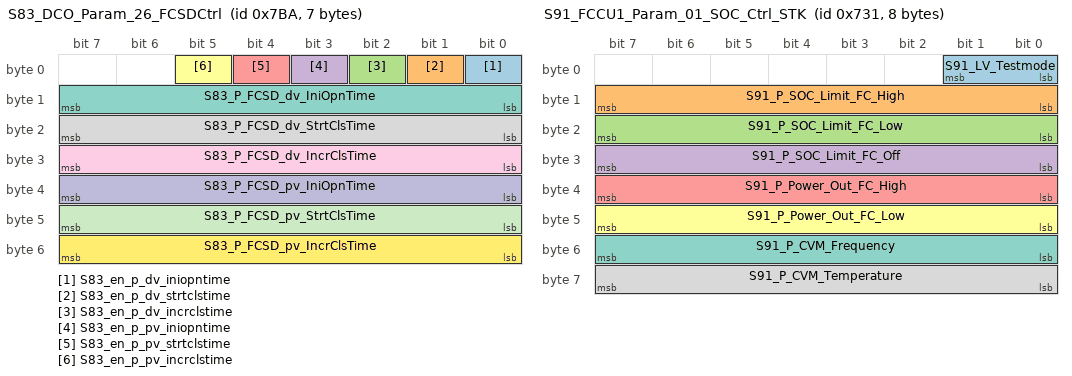
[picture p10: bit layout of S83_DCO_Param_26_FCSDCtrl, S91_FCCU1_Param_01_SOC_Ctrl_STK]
BO_ 1978 S83_DCO_Param_26_FCSDCtrl: 7 S83_DCO
 SG_ S83_en_p_dv_iniopntime : 0|1@1+ (1,0) [0|1] ""  S91_FCCU1
 SG_ S83_en_p_dv_strtclstime : 1|1@1+ (1,0) [0|1] ""  S91_FCCU1
 SG_ S83_en_p_dv_incrclstime : 2|1@1+ (1,0) [0|1] ""  S91_FCCU1
 SG_ S83_en_p_pv_iniopntime : 3|1@1+ (1,0) [0|1] ""  S91_FCCU1
 SG_ S83_en_p_pv_strtclstime : 4|1@1+ (1,0) [0|1] ""  S91_FCCU1
 SG_ S83_en_p_pv_incrclstime : 5|1@1+ (1,0) [0|1] ""  S91_FCCU1
 SG_ S83_P_FCSD_dv_IniOpnTime : 8|8@1+ (0.1,0) [0|25.5] "s"  S91_FCCU1
 SG_ S83_P_FCSD_dv_StrtClsTime : 16|8@1+ (0.1,0) [0|25.5] "s"  S91_FCCU1
 SG_ S83_P_FCSD_dv_IncrClsTime : 24|8@1+ (0.1,0) [0|25.5] "s"  S91_FCCU1
 SG_ S83_P_FCSD_pv_IniOpnTime : 32|8@1+ (0.1,0) [0|25.5] "s"  S91_FCCU1
 SG_ S83_P_FCSD_pv_StrtClsTime : 40|8@1+ (0.1,0) [0|25.5] "s"  S91_FCCU1
 SG_ S83_P_FCSD_pv_IncrClsTime : 48|8@1+ (0.1,0) [0|25.5] "s"  S91_FCCU1

BO_ 1841 S91_FCCU1_Param_01_SOC_Ctrl_STK: 8 S91_FCCU1
 SG_ S91_LV_Testmode : 0|2@1+ (1,0) [0|4] ""  S83_DCO,LABVIEW
 SG_ S91_P_SOC_Limit_FC_High : 8|8@1+ (1,0) [0|100] "%"  S83_DCO,LABVIEW
 SG_ S91_P_SOC_Limit_FC_Low : 16|8@1+ (1,0) [0|100] "%"  S83_DCO,LABVIEW
 SG_ S91_P_SOC_Limit_FC_Off : 24|8@1+ (1,0) [0|100] "%"  S83_DCO,LABVIEW
 SG_ S91_P_Power_Out_FC_High : 32|8@1+ (1,0) [0|255] "A"  S83_DCO,LABVIEW
 SG_ S91_P_Power_Out_FC_Low : 40|8@1+ (1,0) [0|255] "A"  S83_DCO,LABVIEW
 SG_ S91_P_CVM_Frequency : 48|8@1+ (1,0) [0|255] "Hz"  S83_DCO,LABVIEW
 SG_ S91_P_CVM_Temperature : 56|8@1+ (1,0) [0|255] "°C"  S83_DCO,LABVIEW

BO_ 1842 S91_FCCU1_Param_02_STK: 7 S91_FCCU1
 SG_ S91_P_CVM_Low_Lim2 : 8|12@1+ (0.001,0) [0|4.095] "V"  S83_DCO,LABVIEW
 SG_ S91_P_CVM_Up_Lim1 : 20|12@1+ (0.001,0) [0|4.095] "V"  S83_DCO,LABVIEW
 SG_ S91_P_CVM_Up_Lim2 : 32|12@1+ (0.001,0) [0|4.095] "V"  S83_DCO,LABVIEW
 SG_ S91_P_CVM_Diff_MaxMin_Lim : 44|12@1+ (0.001,0) [0|4.095] "V"  S83_DCO,LABVIEW

BO_ 1843 S91_FCCU1_Param_03_HRBO: 6 S91_FCCU1
 SG_ S91_P_HRBo_a_Valve_OT_fact : 8|16@1+ (0.001,0) [0|10] ""  S83_DCO,LABVIEW
 SG_ S91_P_HRBo_a_Valve_I_fact : 24|16@1+ (0.001,0) [0|10] ""  S83_DCO,LABVIEW
 SG_ S91_P_HRBo_a_Valve_Async_fact : 40|1@1+ (1,0) [0|1] ""  S83_DCO,LABVIEW

BO_ 1844 S91_FCCU1_Param_04_RFCtrl: 4 S91_FCCU1
 SG_ S91_P_RFC_NrmOpBaseVal_FanSpd : 8|8@1+ (1,0) [0|100] "%"  S83_DCO,LABVIEW
 SG_ S91_P_RFC_SrtStpVent_FanSpd : 16|8@1+ (1,0) [0|100] "%"  S83_DCO,LABVIEW
 SG_ S91_P_RFC_HghVent_FanSpd : 24|8@1+ (1,0) [0|100] "%"  S83_DCO,LABVIEW

BO_ 1845 S91_FCCU1_Param_05_ThermCtrl: 8 S91_FCCU1
 SG_ S91_P_TC_StkIntT_P_Crtl_FanSpd : 0|32@1+ (1E-006,0) [0|4294.967295] ""  S83_DCO,LABVIEW
 SG_ S91_P_TC_StkIntT_I_Crtl_FanSpd : 32|32@1+ (1E-006,0) [0|4294.967295] ""  S83_DCO,LABVIEW

BO_ 1846 S91_FCCU1_Param_06_ThermCtrl: 8 S91_FCCU1
 SG_ S91_P_TC_ClPmpSpd_Amp0 : 4|12@1+ (1,0) [0|511] "A"  S83_DCO,LABVIEW
 SG_ S91_P_TC_ClPmpSpd_Amp1 : 16|12@1+ (1,0) [0|511] "A"  S83_DCO,LABVIEW
 SG_ S91_P_TC_ClPmpSpd_Amp2 : 28|12@1+ (1,0) [0|511] "A"  S83_DCO,LABVIEW
 SG_ S91_P_TC_ClPmpSpd_perc0 : 40|8@1+ (1,0) [0|100] "%"  S83_DCO,LABVIEW
 SG_ S91_P_TC_ClPmpSpd_perc1 : 48|8@1+ (1,0) [0|100] "%"  S83_DCO,LABVIEW
 SG_ S91_P_TC_ClPmpSpd_perc2 : 56|8@1+ (1,0) [0|100] "%"  S83_DCO,LABVIEW

BO_ 1847 S91_FCCU1_Param_07_ThermCtrl: 7 S91_FCCU1
 SG_ S91_P_TC_OTV_MaxTankPress : 8|16@1+ (100,0) [0|100000] "kPa"  S83_DCO,LABVIEW
 SG_ S91_P_TC_GHU_MaxLowPress : 24|16@1+ (1,0) [0|4100] "kPa"  S83_DCO,LABVIEW
 SG_ S91_P_TC_GHU_MaxMidPress : 40|16@1+ (1,0) [0|2500] "kPa"  S83_DCO,LABVIEW

BO_ 1848 S91_FCCU1_Param_08_PowCtrl: 4 S91_FCCU1
 SG_ S91_P_PC_UIrangeCell_Volt : 8|16@1+ (0.001,0) [0|65.535] "V"  S83_DCO,LABVIEW
 SG_ S91_P_PC_UIrangeCell_Time : 24|8@1+ (0.1,0) [0|25.5] "s"  S83_DCO,LABVIEW

BO_ 1849 S91_FCCU1_Param_09_PowCtrl: 7 S91_FCCU1
 SG_ S91_P_PC_MinUCell_range1_Volt : 8|16@1+ (0.001,0) [0|65.535] "V"  S83_DCO,LABVIEW
 SG_ S91_P_PC_MinUCell_range2_Volt : 24|16@1+ (0.001,0) [0|65.535] "V"  S83_DCO,LABVIEW
 SG_ S91_P_PC_MinUCell_range1_Time : 40|8@1+ (0.1,0) [0|25.5] "s"  S83_DCO,LABVIEW
 SG_ S91_P_PC_MinUCell_range2_Time : 48|8@1+ (0.1,0) [0|25.5] "s"  S83_DCO,LABVIEW

BO_ 1850 S91_FCCU1_Param_10_WtlCtrl: 4 S91_FCCU1
 SG_ S91_P_WTLC_SOC_Lvl : 8|8@1+ (1,0) [0|100] "%"  S83_DCO,LABVIEW
 SG_ S91_P_WTLC_SOC_time2off : 16|16@1+ (0.1,0) [0|6553.5] "s"  S83_DCO,LABVIEW

BO_ 1851 S91_FCCU1_Param_11_CldnOp: 5 S91_FCCU1
 SG_ S91_P_CLDN_RF_Spd : 8|8@1+ (1,0) [0|100] "%"  S83_DCO,LABVIEW
 SG_ S91_P_CLDN_RF_Time : 16|16@1+ (0.1,0) [0|6553.5] "s"  S83_DCO,LABVIEW
 SG_ S91_P_CLDN_CP_Spd : 32|8@1+ (1,0) [0|100] "%"  S83_DCO,LABVIEW

BO_ 1852 S91_FCCU1_Param_12_CldnOp: 6 S91_FCCU1
 SG_ S91_P_CLDN_AMBlimit_Temp : 8|8@1+ (1,-40) [-40|215] "°C"  S83_DCO,LABVIEW
 SG_ S91_P_CLDN_SOClimit : 16|8@1+ (1,0) [0|100] "%"  S83_DCO,LABVIEW
 SG_ S91_P_CLDN_AMBlimitOff_Temp : 24|8@1+ (1,-40) [-40|215] "°C"  S83_DCO,LABVIEW
 SG_ S91_P_CLDN_time2off : 32|16@1+ (0.1,0) [0|6553.5] "s"  S83_DCO,LABVIEW

BO_ 1853 S91_FCCU1_Param_13_HMICtrl: 8 S91_FCCU1
 SG_ S91_P_HMI_H2TankLvl_Displ : 8|8@1+ (1,0) [0|100] "%"  S83_DCO,LABVIEW
 SG_ S91_P_HMI_H2TankLvl_Scale0 : 16|16@1+ (100,0) [0|100000] "kPa"  S83_DCO,LABVIEW
 SG_ S91_P_HMI_H2TankLvl_Scale1 : 32|16@1+ (100,0) [0|100000] "kPa"  S83_DCO,LABVIEW
 SG_ S91_P_HMI_H2TankLvl_PressLim : 48|16@1+ (100,0) [0|100000] "kPa"  S83_DCO,LABVIEW

BO_ 1854 S91_FCCU1_Param_14_HMICtrl: 6 S91_FCCU1
 SG_ S91_P_HMI_BAT_SOC_Limit_low : 8|8@1+ (1,0) [0|100] "%"  S83_DCO,LABVIEW
 SG_ S91_P_HMI_BAT_SOC_Limit_ok : 16|8@1+ (1,0) [0|100] "%"  S83_DCO,LABVIEW
 SG_ S91_P_HMI_H2_leak_amb_ppm : 24|8@1+ (500,-5000) [-5000|123000] "ppm"  S83_DCO,LABVIEW
 SG_ S91_P_HMI_H2_leak_exh_ppm : 32|8@1+ (500,-5000) [-5000|123000] "ppm"  S83_DCO,LABVIEW
 SG_ S91_P_HMI_H2_leak_exh_s : 40|8@1+ (0.1,0) [0|25.5] "s"  S83_DCO,LABVIEW

BO_ 1855 S91_FCCU1_Param_15_SysPwrDn: 5 S91_FCCU1
 SG_ S91_P_SPDN_BATlimit_Curr : 8|16@1+ (0.1,-3276.8) [-3276.8|3276.7] "A"  S83_DCO,LABVIEW
 SG_ S91_P_SPDN_BATlimit_Time : 24|16@1+ (0.1,0) [0|6553.5] "s"  S83_DCO,LABVIEW

BO_ 1856 S91_FCCU1_Param_16_FCSUCtrl: 8 S91_FCCU1
 SG_ S91_P_FCSU_GHU_StrtPress2 : 8|8@1+ (1,0) [0|255] "kPa"  S83_DCO,LABVIEW
 SG_ S91_P_FCSU_H2_StrtPress : 16|8@1+ (1,0) [0|255] "kPa"  S83_DCO,LABVIEW
 SG_ S91_P_FCSU_H2_InitPress : 24|8@1+ (1,0) [0|255] "kPa"  S83_DCO,LABVIEW
 SG_ S91_P_FCSU_GHU_StrtPress1 : 32|12@1+ (1,0) [0|2500] "kPa"  S83_DCO,LABVIEW
 SG_ S91_P_FCSU_ETC_InitSpd : 44|20@1+ (1,0) [0|1048575] "rpm"  S83_DCO,LABVIEW

BO_ 1857 S91_FCCU1_Param_17_FCSUCtrl: 8 S91_FCCU1
 SG_ S91_P_FCSU_HRB_StrtSpd : 8|16@1+ (1,0) [0|25000] "rpm"  S83_DCO,LABVIEW
 SG_ S91_P_FCSU_PVrmp_IniOpnTime : 24|8@1+ (0.1,0) [0|25.5] "s"  S83_DCO,LABVIEW
 SG_ S91_P_FCSU_PVrmp_StrtClsTime : 32|8@1+ (0.1,0) [0|25.5] "s"  S83_DCO,LABVIEW
 SG_ S91_P_FCSU_PVrmp_IncrClsTime : 40|8@1+ (0.1,0) [0|25.5] "s"  S83_DCO,LABVIEW
 SG_ S91_P_FCSU_InitMinCellVolt : 48|16@1+ (0.001,0) [0|65.535] "V"  S83_DCO,LABVIEW

BO_ 1858 S91_FCCU1_Param_18_FCSUCtrl: 8 S91_FCCU1
 SG_ S91_P_FCSU_H2_Press_P_Ctrl : 0|32@1+ (1E-006,0) [0|4294.967295] ""  S83_DCO,LABVIEW
 SG_ S91_P_FCSU_H2_Press_I_Ctrl : 32|32@1+ (1E-006,0) [0|4294.967295] ""  S83_DCO,LABVIEW

BO_ 1859 S91_FCCU1_Param_19_FCSUCtrl: 8 S91_FCCU1
 SG_ S91_P_FCSU_MinCellVolt_Time : 8|16@1+ (0.1,0) [0|6553.5] "s"  S83_DCO,LABVIEW
 SG_ S91_P_FCSU_DCDC_PreOpTime : 24|8@1+ (0.1,0) [0|25.5] "s"  S83_DCO,LABVIEW
 SG_ S91_P_FCSU_DCDC_OpTime : 32|8@1+ (0.1,0) [0|25.5] "s"  S83_DCO,LABVIEW
 SG_ S91_P_FCSU_DCDC_CurrRampGrad : 40|8@1+ (0.1,0) [0|25.5] "A/s"  S83_DCO,LABVIEW
 SG_ S91_P_FCSU_DCDC_MaxWrmUp_Curr : 48|16@1+ (0.1,0) [0|6553.5] "A"  S83_DCO,LABVIEW

BO_ 1860 S91_FCCU1_Param_20_FCSUCtrl: 7 S91_FCCU1
 SG_ S91_P_FCSU_STK_LowCellVolt : 8|16@1+ (0.001,0) [0|65.535] "V"  S83_DCO,LABVIEW
 SG_ S91_P_FCSU_STK_DeltaMedLow_V : 24|16@1+ (0.001,0) [0|65.535] "V"  S83_DCO,LABVIEW
 SG_ S91_P_FCSU_STK_NormOpSet_Temp : 40|8@1+ (1,-40) [-40|215] "°C"  S83_DCO,LABVIEW
 SG_ S91_P_FCSU_BPV_OpnCls_Time : 48|8@1+ (0.1,0) [0|25.5] "s"  S83_DCO,LABVIEW

BO_ 1861 S91_FCCU1_Param_21_FCSDCtrl: 8 S91_FCCU1
 SG_ S91_P_FCSD_H2end_Press : 8|16@1+ (1,0) [0|400] "kPa"  S83_DCO,LABVIEW
 SG_ S91_P_FCSD_HRBstp_Spd : 24|16@1+ (1,0) [0|25000] "rpm"  S83_DCO,LABVIEW
 SG_ S91_P_FCSD_ETC_InitRng_Spd : 40|24@1+ (1,0) [0|16777215] "rpm"  S83_DCO,LABVIEW

BO_ 1862 S91_FCCU1_Param_22_FCDU_FCA: 4 S91_FCCU1
 SG_ S91_en_p_fcdu_stk_curr_ramp_time : 0|1@1+ (1,0) [0|1] ""  S83_DCO,LABVIEW
 SG_ S91_en_p_fca_etc_preset_gradient : 1|1@1+ (1,0) [0|1] ""  S83_DCO,LABVIEW
 SG_ S91_P_FCDU_STK_Curr_Ramp_Time : 8|8@1+ (1,0) [0|255] "s"  S83_DCO,LABVIEW
 SG_ S91_P_FCA_ETC_Preset_Gradient : 16|16@1+ (1,0) [0|65535] "rpm/s"  S83_DCO,LABVIEW

BO_ 1863 S91_FCCU1_Param_23_FCA_Press_PI: 8 S91_FCCU1
 SG_ S91_P_FCA_Press_P_Ctrl : 0|32@1+ (1E-006,0) [0|4294.967295] ""  S83_DCO,LABVIEW
 SG_ S91_P_FCA_Press_I_Ctrl : 32|32@1+ (1E-006,0) [0|4294.967295] ""  S83_DCO,LABVIEW

BO_ 1864 S91_FCCU1_Param_24_FCA_D: 8 S91_FCCU1
 SG_ S91_P_FCA_Press_D_Ctrl : 0|32@1+ (1E-006,0) [0|4294.967295] ""  S83_DCO,LABVIEW
 SG_ S91_P_FCA_Speed_D_Ctrl : 32|32@1+ (1E-006,0) [0|4294.967295] ""  S83_DCO,LABVIEW

BO_ 1865 S91_FCCU1_Param_25_FCA_Speed_PI: 8 S91_FCCU1
 SG_ S91_P_FCA_Speed_P_Ctrl : 0|32@1+ (1E-006,0) [0|4294.967295] ""  S83_DCO,LABVIEW
 SG_ S91_P_FCA_Speed_I_Ctrl : 32|32@1+ (1E-006,0) [0|4294.967295] ""  S83_DCO,LABVIEW

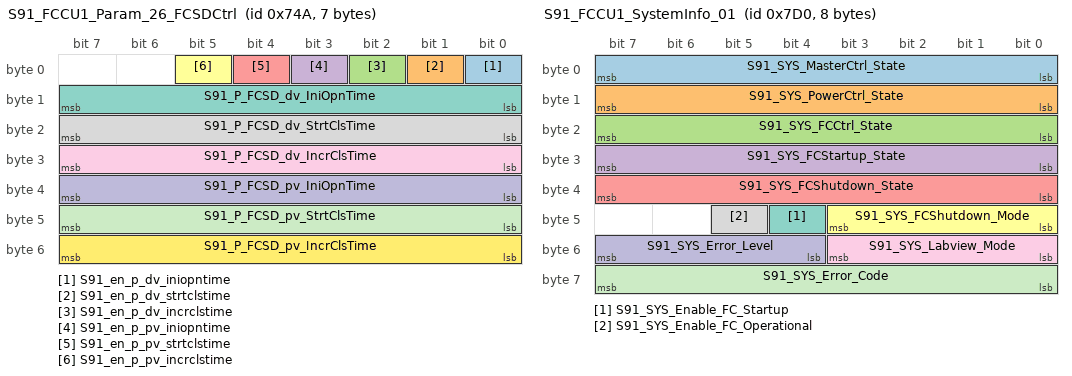
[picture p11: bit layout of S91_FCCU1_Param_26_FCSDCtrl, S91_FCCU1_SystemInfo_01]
BO_ 1866 S91_FCCU1_Param_26_FCSDCtrl: 7 S91_FCCU1
 SG_ S91_en_p_dv_iniopntime : 0|1@1+ (1,0) [0|1] ""  S83_DCO,LABVIEW
 SG_ S91_en_p_dv_strtclstime : 1|1@1+ (1,0) [0|1] ""  S83_DCO,LABVIEW
 SG_ S91_en_p_dv_incrclstime : 2|1@1+ (1,0) [0|1] ""  S83_DCO,LABVIEW
 SG_ S91_en_p_pv_iniopntime : 3|1@1+ (1,0) [0|1] ""  S83_DCO,LABVIEW
 SG_ S91_en_p_pv_strtclstime : 4|1@1+ (1,0) [0|1] ""  S83_DCO,LABVIEW
 SG_ S91_en_p_pv_incrclstime : 5|1@1+ (1,0) [0|1] ""  S83_DCO,LABVIEW
 SG_ S91_P_FCSD_dv_IniOpnTime : 8|8@1+ (0.1,0) [0|25.5] "s"  S83_DCO,LABVIEW
 SG_ S91_P_FCSD_dv_StrtClsTime : 16|8@1+ (0.1,0) [0|25.5] "s"  S83_DCO,LABVIEW
 SG_ S91_P_FCSD_dv_IncrClsTime : 24|8@1+ (0.1,0) [0|25.5] "s"  S83_DCO,LABVIEW
 SG_ S91_P_FCSD_pv_IniOpnTime : 32|8@1+ (0.1,0) [0|25.5] "s"  S83_DCO,LABVIEW
 SG_ S91_P_FCSD_pv_StrtClsTime : 40|8@1+ (0.1,0) [0|25.5] "s"  S83_DCO,LABVIEW
 SG_ S91_P_FCSD_pv_IncrClsTime : 48|8@1+ (0.1,0) [0|25.5] "s"  S83_DCO,LABVIEW

BO_ 2000 S91_FCCU1_SystemInfo_01: 8 S91_FCCU1
 SG_ S91_SYS_MasterCtrl_State : 0|8@1+ (1,0) [0|255] ""  S83_DCO,LABVIEW
 SG_ S91_SYS_PowerCtrl_State : 8|8@1+ (1,0) [0|255] ""  S83_DCO,LABVIEW
 SG_ S91_SYS_FCCtrl_State : 16|8@1+ (1,0) [0|255] ""  S83_DCO,LABVIEW
 SG_ S91_SYS_FCStartup_State : 24|8@1+ (1,0) [0|255] ""  S83_DCO,LABVIEW
 SG_ S91_SYS_FCShutdown_State : 32|8@1+ (1,0) [0|255] ""  S83_DCO,LABVIEW
 SG_ S91_SYS_FCShutdown_Mode : 40|4@1+ (1,0) [0|15] ""  S83_DCO,LABVIEW
 SG_ S91_SYS_Enable_FC_Startup : 44|1@1+ (1,0) [0|1] ""  S83_DCO,LABVIEW
 SG_ S91_SYS_Enable_FC_Operational : 45|1@1+ (1,0) [0|1] ""  S83_DCO,LABVIEW
 SG_ S91_SYS_Labview_Mode : 48|4@1+ (1,0) [0|15] ""  S83_DCO,LABVIEW
 SG_ S91_SYS_Error_Level : 52|4@1+ (1,0) [0|15] ""  S83_DCO,LABVIEW
 SG_ S91_SYS_Error_Code : 56|8@1+ (1,0) [0|255] ""  S83_DCO,LABVIEW

BO_ 2001 S91_FCCU1_SystemInfo_02: 8 S91_FCCU1
 SG_ S91_SYS_Alive_C01_RF : 0|1@1+ (1,0) [0|1] ""  S83_DCO,LABVIEW
 SG_ S91_SYS_Alive_C02_RPM : 1|1@1+ (1,0) [0|1] ""  S83_DCO,LABVIEW
 SG_ S91_SYS_Alive_A03_ETC : 2|1@1+ (1,0) [0|1] ""  S83_DCO,LABVIEW
 SG_ S91_SYS_Alive_C04_DI : 3|1@1+ (1,0) [0|1] ""  S83_DCO,LABVIEW
 SG_ S91_SYS_Alive_C06_ET : 4|1@1+ (1,0) [0|1] ""  S83_DCO,LABVIEW
 SG_ S91_SYS_Alive_C07_B : 5|1@1+ (1,0) [0|1] ""  S83_DCO,LABVIEW
 SG_ S91_SYS_Alive_C08_AMB : 6|1@1+ (1,0) [0|1] ""  S83_DCO,LABVIEW
 SG_ S91_SYS_Alive_A11_HBV : 7|1@1+ (1,0) [0|1] ""  S83_DCO,LABVIEW
 SG_ S91_SYS_Alive_A12_SIV : 8|1@1+ (1,0) [0|1] ""  S83_DCO,LABVIEW
 SG_ S91_SYS_Alive_A13_SOV : 9|1@1+ (1,0) [0|1] ""  S83_DCO,LABVIEW
 SG_ S91_SYS_Alive_A14_HFM : 10|1@1+ (1,0) [0|1] ""  S83_DCO,LABVIEW
 SG_ S91_SYS_Alive_A15_SI : 11|1@1+ (1,0) [0|1] ""  S83_DCO,LABVIEW
 SG_ S91_SYS_Alive_A16_SI : 12|1@1+ (1,0) [0|1] ""  S83_DCO,LABVIEW
 SG_ S91_SYS_Alive_A17_SO : 13|1@1+ (1,0) [0|1] ""  S83_DCO,LABVIEW
 SG_ S91_SYS_Alive_A22_HSI : 14|1@1+ (1,0) [0|1] ""  S83_DCO,LABVIEW
 SG_ S91_SYS_Alive_A23_HSO : 15|1@1+ (1,0) [0|1] ""  S83_DCO,LABVIEW
 SG_ S91_SYS_Alive_H31_OTV : 16|1@1+ (1,0) [0|1] ""  S83_DCO,LABVIEW
 SG_ S91_SYS_Alive_H36_GHU : 17|1@1+ (1,0) [0|1] ""  S83_DCO,LABVIEW
 SG_ S91_SYS_Alive_H37_GHU : 18|1@1+ (1,0) [0|1] ""  S83_DCO,LABVIEW
 SG_ S91_SYS_Alive_H38_HSV : 19|1@1+ (1,0) [0|1] ""  S83_DCO,LABVIEW
 SG_ S91_SYS_Alive_H40_GHU : 20|1@1+ (1,0) [0|1] ""  S83_DCO,LABVIEW
 SG_ S91_SYS_Alive_H41_GHU : 21|1@1+ (1,0) [0|1] ""  S83_DCO,LABVIEW
 SG_ S91_SYS_Alive_H42_HRB : 22|1@1+ (1,0) [0|1] ""  S83_DCO,LABVIEW
 SG_ S91_SYS_Alive_H43_HDV : 23|1@1+ (1,0) [0|1] ""  S83_DCO,LABVIEW
 SG_ S91_SYS_Alive_H45_WT : 24|1@1+ (1,0) [0|1] ""  S83_DCO,LABVIEW
 SG_ S91_SYS_Alive_H46_HRBO : 25|1@1+ (1,0) [0|1] ""  S83_DCO,LABVIEW
 SG_ S91_SYS_Alive_H51_STK : 26|1@1+ (1,0) [0|1] ""  S83_DCO,LABVIEW
 SG_ S91_SYS_Alive_H52_DV : 27|1@1+ (1,0) [0|1] ""  S83_DCO,LABVIEW
 SG_ S91_SYS_Alive_H53_PV : 28|1@1+ (1,0) [0|1] ""  S83_DCO,LABVIEW
 SG_ S91_SYS_Alive_C54_SO : 29|1@1+ (1,0) [0|1] ""  S83_DCO,LABVIEW
 SG_ S91_SYS_Alive_H55_SI : 30|1@1+ (1,0) [0|1] ""  S83_DCO,LABVIEW
 SG_ S91_SYS_Alive_A56_SO : 31|1@1+ (1,0) [0|1] ""  S83_DCO,LABVIEW
 SG_ S91_SYS_Alive_H62_HLD : 32|1@1+ (1,0) [0|1] ""  S83_DCO,LABVIEW
 SG_ S91_SYS_Alive_H63_HLD : 33|1@1+ (1,0) [0|1] ""  S83_DCO,LABVIEW
 SG_ S91_SYS_Alive_E71_DC4880 : 34|1@1+ (1,0) [0|1] ""  S83_DCO,LABVIEW
 SG_ S91_SYS_Alive_E72_DC8024 : 35|1@1+ (1,0) [0|1] ""  S83_DCO,LABVIEW
 SG_ S91_SYS_Alive_E73_DC8012 : 36|1@1+ (1,0) [0|1] ""  S83_DCO,LABVIEW
 SG_ S91_SYS_Alive_E74_ISOHV : 37|1@1+ (1,0) [0|1] ""  S83_DCO,LABVIEW
 SG_ S91_SYS_Alive_E75_HVP : 38|1@1+ (1,0) [0|1] ""  S83_DCO,LABVIEW
 SG_ S91_SYS_Alive_E76_HVM : 39|1@1+ (1,0) [0|1] ""  S83_DCO,LABVIEW
 SG_ S91_SYS_Alive_S80_BP : 40|1@1+ (1,0) [0|1] ""  S83_DCO,LABVIEW
 SG_ S91_SYS_Alive_E95_DC2405 : 41|1@1+ (1,0) [0|1] ""  S83_DCO,LABVIEW

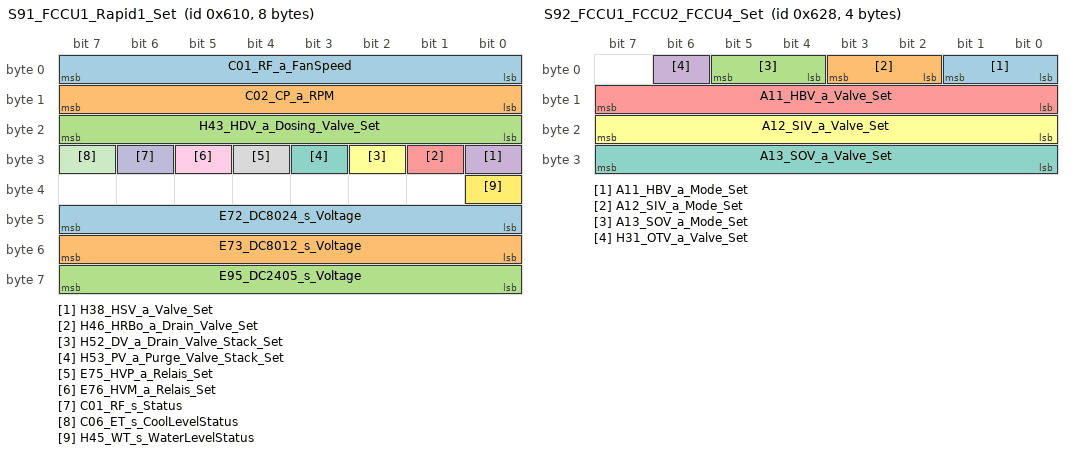
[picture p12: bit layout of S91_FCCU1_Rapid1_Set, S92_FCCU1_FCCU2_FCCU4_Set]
BO_ 1552 S91_FCCU1_Rapid1_Set: 8 S91_FCCU1
 SG_ C01_RF_a_FanSpeed : 0|8@1+ (1,0) [0|100] "%"  S83_DCO,LABVIEW
 SG_ C02_CP_a_RPM : 8|8@1+ (1,0) [0|100] "%"  S83_DCO,LABVIEW
 SG_ H43_HDV_a_Dosing_Valve_Set : 16|8@1+ (1,0) [0|100] "%"  S83_DCO,LABVIEW
 SG_ H38_HSV_a_Valve_Set : 24|1@1+ (1,0) [0|1] ""  S83_DCO,LABVIEW
 SG_ H46_HRBo_a_Drain_Valve_Set : 25|1@1+ (1,0) [0|1] ""  S83_DCO,LABVIEW
 SG_ H52_DV_a_Drain_Valve_Stack_Set : 26|1@1+ (1,0) [0|1] ""  S83_DCO,LABVIEW
 SG_ H53_PV_a_Purge_Valve_Stack_Set : 27|1@1+ (1,0) [0|1] ""  S83_DCO,LABVIEW
 SG_ E75_HVP_a_Relais_Set : 28|1@1+ (1,0) [0|1] ""  S83_DCO,LABVIEW
 SG_ E76_HVM_a_Relais_Set : 29|1@1+ (1,0) [0|1] ""  S83_DCO,LABVIEW
 SG_ C01_RF_s_Status : 30|1@1+ (1,0) [0|1] ""  S83_DCO,LABVIEW
 SG_ C06_ET_s_CoolLevelStatus : 31|1@1+ (1,0) [0|1] ""  S83_DCO,LABVIEW
 SG_ H45_WT_s_WaterLevelStatus : 32|1@1+ (1,0) [0|1] ""  S83_DCO,LABVIEW
 SG_ E72_DC8024_s_Voltage : 40|8@1+ (0.1,0) [0|25.5] "V"  S83_DCO,LABVIEW
 SG_ E73_DC8012_s_Voltage : 48|8@1+ (0.1,0) [0|25.5] "V"  S83_DCO,LABVIEW
 SG_ E95_DC2405_s_Voltage : 56|8@1+ (0.1,0) [0|25.5] "V"  S83_DCO,LABVIEW

BO_ 1553 S91_FCCU1_Rapid1_Ambient: 7 S91_FCCU1
 SG_ C08_AMB_s_Pressure : 0|16@1+ (0.0078125,-250) [-250|261.99] "kPa"  S83_DCO,LABVIEW
 SG_ C08_AMB_s_Humidity_Rel : 16|8@1+ (0.4,0) [0|100] "%RH"  S83_DCO,LABVIEW
 SG_ C08_AMB_s_Humidity_Spec : 24|16@1+ (0.01,0) [0|642.55] "g/kg"  S83_DCO,LABVIEW
 SG_ C08_AMB_s_Temperature : 40|16@1+ (0.03125,-273) [-273|1735] "°C"  S83_DCO,LABVIEW

BO_ 1576 S92_FCCU1_FCCU2_FCCU4_Set: 4 S91_FCCU1
 SG_ A11_HBV_a_Mode_Set : 0|2@1+ (1,0) [0|3] ""  S92_FCCU2,S83_DCO,LABVIEW
 SG_ A12_SIV_a_Mode_Set : 2|2@1+ (1,0) [0|3] ""  S92_FCCU2,S83_DCO,LABVIEW
 SG_ A13_SOV_a_Mode_Set : 4|2@1+ (1,0) [0|3] ""  S92_FCCU2,S83_DCO,LABVIEW
 SG_ H31_OTV_a_Valve_Set : 6|1@1+ (1,0) [0|1] ""  S94_FCCU4,S83_DCO,LABVIEW
 SG_ A11_HBV_a_Valve_Set : 8|8@1+ (1,0) [0|100] "%"  S92_FCCU2,S83_DCO,LABVIEW
 SG_ A12_SIV_a_Valve_Set : 16|8@1+ (1,0) [0|100] "%"  S92_FCCU2,S83_DCO,LABVIEW
 SG_ A13_SOV_a_Valve_Set : 24|8@1+ (1,0) [0|100] "%"  S92_FCCU2,S83_DCO,LABVIEW

BO_ 1568 S92_FCCU2_Rapid2_Actual: 4 S92_FCCU2
 SG_ A11_HBV_s_Mode_Act : 0|2@1+ (1,0) [0|3] ""  S91_FCCU1,S83_DCO,LABVIEW
 SG_ A12_SIV_s_Mode_Act : 2|2@1+ (1,0) [0|3] ""  S91_FCCU1,S83_DCO,LABVIEW
 SG_ A13_SOV_s_Mode_Act : 4|2@1+ (1,0) [0|3] ""  S91_FCCU1,S83_DCO,LABVIEW
 SG_ A11_HBV_s_Valve_Act : 8|8@1+ (1,0) [0|100] "%"  S91_FCCU1,S83_DCO,LABVIEW
 SG_ A12_SIV_s_Valve_Act : 16|8@1+ (1,0) [0|100] "%"  S91_FCCU1,S83_DCO,LABVIEW
 SG_ A13_SOV_s_Valve_Act : 24|8@1+ (1,0) [0|100] "%"  S91_FCCU1,S83_DCO,LABVIEW

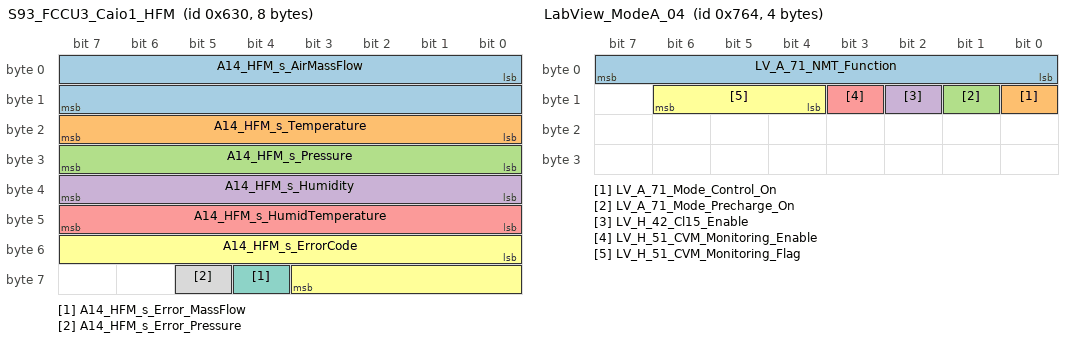
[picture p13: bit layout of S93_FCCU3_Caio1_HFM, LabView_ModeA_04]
BO_ 1584 S93_FCCU3_Caio1_HFM: 8 S93_FCCU3
 SG_ A14_HFM_s_AirMassFlow : 0|16@1- (1,-90) [-90|1000] "kg/h"  S91_FCCU1,S83_DCO,LABVIEW
 SG_ A14_HFM_s_Temperature : 16|8@1+ (1,-40) [-40|140] "°C"  S91_FCCU1,S83_DCO,LABVIEW
 SG_ A14_HFM_s_Pressure : 24|8@1+ (1,0) [10|120] "kPa"  S91_FCCU1,S83_DCO,LABVIEW
 SG_ A14_HFM_s_Humidity : 32|8@1+ (1,0) [0|100] "%RH"  S91_FCCU1,S83_DCO,LABVIEW
 SG_ A14_HFM_s_HumidTemperature : 40|8@1+ (1,-40) [-40|140] "°C"  S91_FCCU1,S83_DCO,LABVIEW
 SG_ A14_HFM_s_ErrorCode : 48|12@1+ (1,0) [0|4095] ""  S91_FCCU1,S83_DCO,LABVIEW
 SG_ A14_HFM_s_Error_MassFlow : 60|1@1+ (1,0) [0|1] ""  S91_FCCU1,S83_DCO,LABVIEW
 SG_ A14_HFM_s_Error_Pressure : 61|1@1+ (1,0) [0|1] ""  S91_FCCU1,S83_DCO,LABVIEW

BO_ 1585 S93_FCCU3_Caio1_Temperature: 8 S93_FCCU3
 SG_ C04_DI_s_Temperature : 0|8@1+ (1,-40) [-40|215] "°C"  S91_FCCU1,S83_DCO,LABVIEW
 SG_ C54_SI_s_Temperature : 8|8@1+ (1,-40) [-40|215] "°C"  S91_FCCU1,S83_DCO,LABVIEW
 SG_ A16_SI_s_Inlet_Temperature : 16|8@1+ (1,-40) [-40|215] "°C"  S91_FCCU1,S83_DCO,LABVIEW
 SG_ A17_SO_s_Outlet_Temperature : 24|8@1+ (1,-40) [-40|215] "°C"  S91_FCCU1,S83_DCO,LABVIEW
 SG_ A56_SO_s_Temperature : 32|8@1+ (1,-40) [-40|215] "°C"  S91_FCCU1,S83_DCO,LABVIEW
 SG_ H31_OTV_s_Temperature : 40|8@1+ (1,-40) [-40|215] "°C"  S91_FCCU1,S83_DCO,LABVIEW
 SG_ H37_GHU_s_Temperature_1 : 48|8@1+ (1,-40) [-40|215] "°C"  S91_FCCU1,S83_DCO,LABVIEW
 SG_ H41_GHU_s_Temperature_2 : 56|8@1+ (1,-40) [-40|215] "°C"  S91_FCCU1,S83_DCO,LABVIEW

BO_ 1600 S94_FCCU4_Caio2_AirLoop: 4 S94_FCCU4
 SG_ A22_HSI_s_Humidity : 0|8@1+ (1,0) [0|100] "%RH"  S91_FCCU1,S83_DCO,LABVIEW
 SG_ A23_HSO_s_Humidity : 8|8@1+ (1,0) [0|100] "%RH"  S91_FCCU1,S83_DCO,LABVIEW
 SG_ A15_SI_s_Inlet_Pressure : 16|8@1+ (1,0) [20|215] "kPa"  S91_FCCU1,S83_DCO,LABVIEW
 SG_ A17_SO_s_Outlet_Pressure : 24|8@1+ (1,0) [20|215] "kPa"  S91_FCCU1,S83_DCO,LABVIEW

BO_ 1601 S94_FCCU4_Caio2_H2Loop: 8 S94_FCCU4
 SG_ H31_OTV_s_Pressure : 0|16@1+ (1,0) [0|65535] "kPa"  S91_FCCU1,S83_DCO,LABVIEW
 SG_ H36_GHU_s_Pressure_1 : 16|16@1+ (1,0) [0|2500] "kPa"  S91_FCCU1,S83_DCO,LABVIEW
 SG_ H40_GHU_s_Pressure_2 : 32|16@1+ (1,0) [0|300] "kPa"  S91_FCCU1,S83_DCO,LABVIEW
 SG_ H55_SI_s_Stack_Inlet_Pressure : 48|16@1+ (1,0) [0|400] "kPa"  S91_FCCU1,S83_DCO,LABVIEW

BO_ 1872 LabView_Testmode_Enable: 8 LABVIEW
 SG_ LV_Testmode_Select : 0|2@1+ (1,0) [0|4] ""  S91_FCCU1,S83_DCO
 SG_ LV_Enable_FC_Startup : 2|1@1+ (1,0) [0|1] ""  S91_FCCU1,S83_DCO
 SG_ LV_Enable_FC_Operational : 3|1@1+ (1,0) [0|1] ""  S91_FCCU1,S83_DCO

BO_ 1889 LabView_ModeA_01: 8 LABVIEW
 SG_ LV_C_01_RF_a_FanSpeed : 0|8@1+ (1,0) [0|100] "%"  S91_FCCU1,S83_DCO
 SG_ LV_C_02_CP_a_RPM : 8|8@1+ (1,0) [0|100] "%"  S91_FCCU1,S83_DCO
 SG_ LV_A_11_HBV_a_Valve_Set : 16|7@1+ (1,0) [0|100] "%"  S91_FCCU1,S83_DCO
 SG_ LV_A_11_HBV_a_Valve_Enable : 23|1@1+ (1,0) [0|1] ""  S91_FCCU1,S83_DCO
 SG_ LV_A_12_SIV_a_Valve_Set : 24|7@1+ (1,0) [0|100] "%"  S91_FCCU1,S83_DCO
 SG_ LV_A_12_SIV_a_Valve_Enable : 31|1@1+ (1,0) [0|1] ""  S91_FCCU1,S83_DCO
 SG_ LV_A_13_SOV_a_Valve_Set : 32|7@1+ (1,0) [0|100] "%"  S91_FCCU1,S83_DCO
 SG_ LV_A_13_SOV_a_Valve_Enable : 39|1@1+ (1,0) [0|1] ""  S91_FCCU1,S83_DCO
 SG_ LV_H_43_HDV_a_Dosing_Valve_Set : 40|8@1+ (1,0) [0|100] "%"  S91_FCCU1,S83_DCO
 SG_ LV_A_03_ETC_a_opCmd1_Start_Stop : 48|1@1+ (1,0) [0|1] ""  S91_FCCU1,S83_DCO
 SG_ LV_A_03_ETC_a_opCmd1_Error_Ack : 49|1@1+ (1,0) [0|1] ""  S91_FCCU1,S83_DCO
 SG_ LV_H_31_OTV_a_Valve_Set : 50|1@1+ (1,0) [0|1] ""  S91_FCCU1,S83_DCO
 SG_ LV_H_38_HSV_a_Valve_Set : 51|1@1+ (1,0) [0|1] ""  S91_FCCU1,S83_DCO
 SG_ LV_H_52_DV_a_Drain_Valve_Stack : 52|1@1+ (1,0) [0|1] ""  S91_FCCU1,S83_DCO
 SG_ LV_H_53_PV_a_Purge_Valve_Stack : 53|1@1+ (1,0) [0|1] ""  S91_FCCU1,S83_DCO
 SG_ LV_E_75_HVP_a_Relais_Set : 54|1@1+ (1,0) [0|1] ""  S91_FCCU1,S83_DCO
 SG_ LV_E_76_HVM_a_Relais_Set : 55|1@1+ (1,0) [0|1] ""  S91_FCCU1,S83_DCO
 SG_ LV_H_46_HRBo_a_Drain_Valve_Set : 56|1@1+ (1,0) [0|1] ""  S91_FCCU1,S83_DCO
 SG_ LV_H_42_HRB_a_KNF_Speed_Rq : 57|7@1+ (1,0) [0|100] "%"  S91_FCCU1,S83_DCO

BO_ 1890 LabView_ModeA_02: 8 LABVIEW
 SG_ LV_A_03_ETC_a_Speed_Set : 0|32@1- (1,0) [-2147483648|2147483647] "rpm"  S91_FCCU1,S83_DCO
 SG_ LV_H_42_HRB_a_FCCU_Spd_Rq : 32|16@1+ (1,0) [0|65535] "rpm"  S91_FCCU1,S83_DCO
 SG_ LV_E_74_ISO_a_Rq_D_IMC_STEST_SCR : 48|16@1+ (1,0) [0|65535] ""  S91_FCCU1,S83_DCO

BO_ 1891 LabView_ModeA_03: 8 LABVIEW
 SG_ LV_A_71_Current_In_Set : 16|16@1+ (0.01,0) [0|110] "%"  S91_FCCU1,S83_DCO
 SG_ LV_A_71_Voltage_In_Set : 0|16@1+ (0.01,0) [0|110] "%"  S91_FCCU1,S83_DCO
 SG_ LV_A_71_Voltage_Out_Set : 32|16@1+ (0.01,0) [0|110] "%"  S91_FCCU1,S83_DCO
 SG_ LV_A_71_Current_Out_Set : 48|16@1+ (0.01,0) [0|110] "%"  S91_FCCU1,S83_DCO

BO_ 1892 LabView_ModeA_04: 4 LABVIEW
 SG_ LV_A_71_NMT_Function : 0|8@1+ (1,0) [0|255] ""  S91_FCCU1,S83_DCO
 SG_ LV_A_71_Mode_Control_On : 8|1@1+ (1,0) [0|1] ""  S91_FCCU1,S83_DCO
 SG_ LV_A_71_Mode_Precharge_On : 9|1@1+ (1,0) [0|1] ""  S91_FCCU1,S83_DCO
 SG_ LV_H_42_Cl15_Enable : 10|1@1+ (1,0) [0|1] ""  S91_FCCU1,S83_DCO
 SG_ LV_H_51_CVM_Monitoring_Enable : 11|1@1+ (1,0) [0|1] ""  S91_FCCU1,S83_DCO
 SG_ LV_H_51_CVM_Monitoring_Flag : 12|3@1+ (1,0) [0|7] ""  S91_FCCU1,S83_DCO

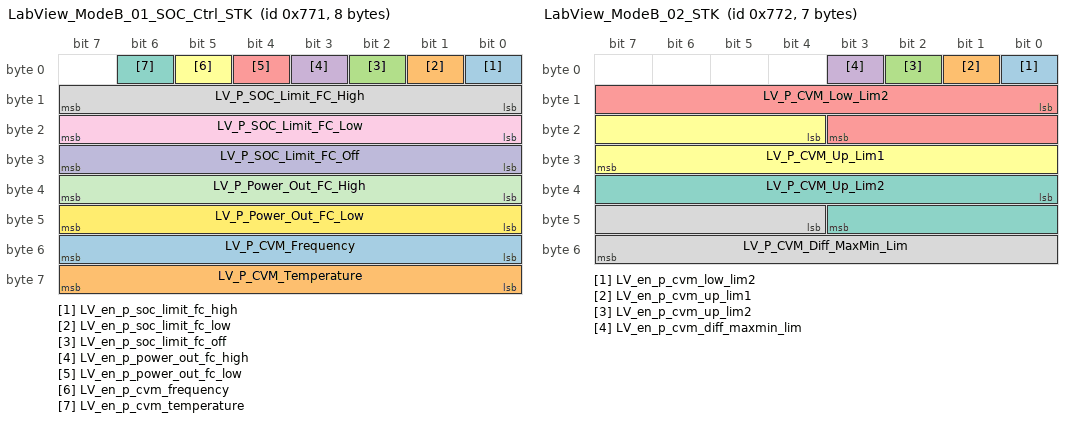
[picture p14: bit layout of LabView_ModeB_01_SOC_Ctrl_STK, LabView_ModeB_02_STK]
BO_ 1905 LabView_ModeB_01_SOC_Ctrl_STK: 8 LABVIEW
 SG_ LV_en_p_soc_limit_fc_high : 0|1@1+ (1,0) [0|1] ""  S91_FCCU1,S83_DCO
 SG_ LV_en_p_soc_limit_fc_low : 1|1@1+ (1,0) [0|1] ""  S91_FCCU1,S83_DCO
 SG_ LV_en_p_soc_limit_fc_off : 2|1@1+ (1,0) [0|1] ""  S91_FCCU1,S83_DCO
 SG_ LV_en_p_power_out_fc_high : 3|1@1+ (1,0) [0|1] ""  S91_FCCU1,S83_DCO
 SG_ LV_en_p_power_out_fc_low : 4|1@1+ (1,0) [0|1] ""  S91_FCCU1,S83_DCO
 SG_ LV_en_p_cvm_frequency : 5|1@1+ (1,0) [0|1] ""  S91_FCCU1,S83_DCO
 SG_ LV_en_p_cvm_temperature : 6|1@1+ (1,0) [0|1] ""  S91_FCCU1,S83_DCO
 SG_ LV_P_SOC_Limit_FC_High : 8|8@1+ (1,0) [0|100] "%"  S91_FCCU1,S83_DCO
 SG_ LV_P_SOC_Limit_FC_Low : 16|8@1+ (1,0) [0|100] "%"  S91_FCCU1,S83_DCO
 SG_ LV_P_SOC_Limit_FC_Off : 24|8@1+ (1,0) [0|100] "%"  S91_FCCU1,S83_DCO
 SG_ LV_P_Power_Out_FC_High : 32|8@1+ (1,0) [0|255] "A"  S91_FCCU1,S83_DCO
 SG_ LV_P_Power_Out_FC_Low : 40|8@1+ (1,0) [0|255] "A"  S91_FCCU1,S83_DCO
 SG_ LV_P_CVM_Frequency : 48|8@1+ (1,0) [0|255] "Hz"  S91_FCCU1,S83_DCO
 SG_ LV_P_CVM_Temperature : 56|8@1+ (1,0) [0|255] "°C"  S91_FCCU1,S83_DCO

BO_ 1906 LabView_ModeB_02_STK: 7 LABVIEW
 SG_ LV_en_p_cvm_low_lim2 : 0|1@1+ (1,0) [0|1] ""  S91_FCCU1,S83_DCO
 SG_ LV_en_p_cvm_up_lim1 : 1|1@1+ (1,0) [0|1] ""  S91_FCCU1,S83_DCO
 SG_ LV_en_p_cvm_up_lim2 : 2|1@1+ (1,0) [0|1] ""  S91_FCCU1,S83_DCO
 SG_ LV_en_p_cvm_diff_maxmin_lim : 3|1@1+ (1,0) [0|1] ""  S91_FCCU1,S83_DCO
 SG_ LV_P_CVM_Low_Lim2 : 8|12@1+ (0.001,0) [0|4.095] "V"  S91_FCCU1,S83_DCO
 SG_ LV_P_CVM_Up_Lim1 : 20|12@1+ (0.001,0) [0|4.095] "V"  S91_FCCU1,S83_DCO
 SG_ LV_P_CVM_Up_Lim2 : 32|12@1+ (0.001,0) [0|4.095] "V"  S91_FCCU1,S83_DCO
 SG_ LV_P_CVM_Diff_MaxMin_Lim : 44|12@1+ (0.001,0) [0|4.095] "V"  S91_FCCU1,S83_DCO

BO_ 1907 LabView_ModeB_03_HRBO: 6 LABVIEW
 SG_ LV_en_p_hrbo_a_valve_ot_fact : 0|1@1+ (1,0) [0|1] ""  S91_FCCU1,S83_DCO
 SG_ LV_en_p_hrbo_a_valve_i_fact : 1|1@1+ (1,0) [0|1] ""  S91_FCCU1,S83_DCO
 SG_ LV_en_p_hrbo_a_valve_async_fact : 2|1@1+ (1,0) [0|1] ""  S91_FCCU1,S83_DCO
 SG_ LV_P_HRBo_a_Valve_OT_fact : 8|16@1+ (0.001,0) [0|10] ""  S91_FCCU1,S83_DCO
 SG_ LV_P_HRBo_a_Valve_I_fact : 24|16@1+ (0.001,0) [0|10] ""  S91_FCCU1,S83_DCO
 SG_ LV_P_HRBo_a_Valve_Async_fact : 40|1@1+ (1,0) [0|1] ""  S91_FCCU1,S83_DCO

BO_ 1908 LabView_ModeB_04_RFCtrl: 4 LABVIEW
 SG_ LV_en_p_rfc_nrmopbaseval_fanspd : 0|1@1+ (1,0) [0|1] ""  S91_FCCU1,S83_DCO
 SG_ LV_en_p_rfc_srtstpvent_fanspd : 1|1@1+ (1,0) [0|1] ""  S91_FCCU1,S83_DCO
 SG_ LV_en_p_rfc_hghvent_fanspd : 2|1@1+ (1,0) [0|1] ""  S91_FCCU1,S83_DCO
 SG_ LV_P_RFC_NrmOpBaseVal_FanSpd : 8|8@1+ (1,0) [0|100] "%"  S91_FCCU1,S83_DCO
 SG_ LV_P_RFC_SrtStpVent_FanSpd : 16|8@1+ (1,0) [0|100] "%"  S91_FCCU1,S83_DCO
 SG_ LV_P_RFC_HghVent_FanSpd : 24|8@1+ (1,0) [0|100] "%"  S91_FCCU1,S83_DCO

BO_ 1909 LabView_ModeB_05_ThermCtrl: 8 LABVIEW
 SG_ LV_P_TC_StkIntT_P_Crtl_FanSpd : 0|32@1+ (1E-006,0) [0|4294.967295] ""  S91_FCCU1,S83_DCO
 SG_ LV_P_TC_StkIntT_I_Crtl_FanSpd : 32|32@1+ (1E-006,0) [0|4294.967295] ""  S91_FCCU1,S83_DCO

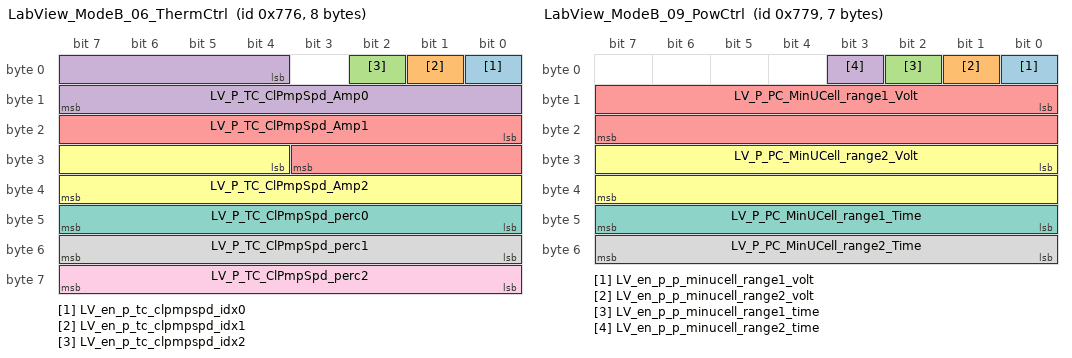
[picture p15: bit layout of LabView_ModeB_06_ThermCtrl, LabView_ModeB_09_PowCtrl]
BO_ 1910 LabView_ModeB_06_ThermCtrl: 8 LABVIEW
 SG_ LV_en_p_tc_clpmpspd_idx0 : 0|1@1+ (1,0) [0|1] ""  S91_FCCU1,S83_DCO
 SG_ LV_en_p_tc_clpmpspd_idx1 : 1|1@1+ (1,0) [0|1] ""  S91_FCCU1,S83_DCO
 SG_ LV_en_p_tc_clpmpspd_idx2 : 2|1@1+ (1,0) [0|1] ""  S91_FCCU1,S83_DCO
 SG_ LV_P_TC_ClPmpSpd_Amp0 : 4|12@1+ (1,0) [0|511] "A"  S91_FCCU1,S83_DCO
 SG_ LV_P_TC_ClPmpSpd_Amp1 : 16|12@1+ (1,0) [0|511] "A"  S91_FCCU1,S83_DCO
 SG_ LV_P_TC_ClPmpSpd_Amp2 : 28|12@1+ (1,0) [0|511] "A"  S91_FCCU1,S83_DCO
 SG_ LV_P_TC_ClPmpSpd_perc0 : 40|8@1+ (1,0) [0|100] "%"  S91_FCCU1,S83_DCO
 SG_ LV_P_TC_ClPmpSpd_perc1 : 48|8@1+ (1,0) [0|100] "%"  S91_FCCU1,S83_DCO
 SG_ LV_P_TC_ClPmpSpd_perc2 : 56|8@1+ (1,0) [0|100] "%"  S91_FCCU1,S83_DCO

BO_ 1911 LabView_ModeB_07_ThermCtrl: 7 LABVIEW
 SG_ LV_en_P_TC_OTV_maxtankpress : 0|1@1+ (1,0) [0|1] ""  S91_FCCU1,S83_DCO
 SG_ LV_en_P_TC_GHU_maxlowpress : 1|1@1+ (1,0) [0|1] ""  S91_FCCU1,S83_DCO
 SG_ LV_en_P_TC_GHU_maxmidpress : 2|1@1+ (1,0) [0|1] ""  S91_FCCU1,S83_DCO
 SG_ LV_P_TC_OTV_MaxTankPress : 8|16@1+ (100,0) [0|100000] "kPa"  S91_FCCU1,S83_DCO
 SG_ LV_P_TC_GHU_MaxLowPress : 24|16@1+ (1,0) [0|4100] "kPa"  S91_FCCU1,S83_DCO
 SG_ LV_P_TC_GHU_MaxMidPress : 40|16@1+ (1,0) [0|2500] "kPa"  S91_FCCU1,S83_DCO

BO_ 1912 LabView_ModeB_08_PowCtrl: 4 LABVIEW
 SG_ LV_en_p_pc_uirangecell_volt : 0|1@1+ (1,0) [0|1] ""  S91_FCCU1,S83_DCO
 SG_ LV_en_p_pc_uirangecell_time : 1|1@1+ (1,0) [0|1] ""  S91_FCCU1,S83_DCO
 SG_ LV_P_PC_UIrangeCell_Volt : 8|16@1+ (0.001,0) [0|65.535] "V"  S91_FCCU1,S83_DCO
 SG_ LV_P_PC_UIrangeCell_Time : 24|8@1+ (0.1,0) [0|25.5] "s"  S91_FCCU1,S83_DCO

BO_ 1913 LabView_ModeB_09_PowCtrl: 7 LABVIEW
 SG_ LV_en_p_p_minucell_range1_volt : 0|1@1+ (1,0) [0|1] ""  S91_FCCU1,S83_DCO
 SG_ LV_en_p_p_minucell_range2_volt : 1|1@1+ (1,0) [0|1] ""  S91_FCCU1,S83_DCO
 SG_ LV_en_p_p_minucell_range1_time : 2|1@1+ (1,0) [0|1] ""  S91_FCCU1,S83_DCO
 SG_ LV_en_p_p_minucell_range2_time : 3|1@1+ (1,0) [0|1] ""  S91_FCCU1,S83_DCO
 SG_ LV_P_PC_MinUCell_range1_Volt : 8|16@1+ (0.001,0) [0|65.535] "V"  S91_FCCU1,S83_DCO
 SG_ LV_P_PC_MinUCell_range2_Volt : 24|16@1+ (0.001,0) [0|65.535] "V"  S91_FCCU1,S83_DCO
 SG_ LV_P_PC_MinUCell_range1_Time : 40|8@1+ (0.1,0) [0|25.5] "s"  S91_FCCU1,S83_DCO
 SG_ LV_P_PC_MinUCell_range2_Time : 48|8@1+ (0.1,0) [0|25.5] "s"  S91_FCCU1,S83_DCO

BO_ 1914 LabView_ModeB_10_WtlCtrl: 4 LABVIEW
 SG_ LV_en_p_wtlc_soc_lvl_perc : 0|1@1+ (1,0) [0|1] ""  S91_FCCU1,S83_DCO
 SG_ LV_en_p_wtlc_soc_time2off_sec : 1|1@1+ (1,0) [0|1] ""  S91_FCCU1,S83_DCO
 SG_ LV_P_WTLC_SOC_Lvl : 8|8@1+ (1,0) [0|100] "%"  S91_FCCU1,S83_DCO
 SG_ LV_P_WTLC_SOC_time2off : 16|16@1+ (0.1,0) [0|6553.5] "s"  S91_FCCU1,S83_DCO

BO_ 1915 LabView_ModeB_11_CldnOp: 5 LABVIEW
 SG_ LV_en_p_cldn_rf_spd : 0|1@1+ (1,0) [0|1] ""  S91_FCCU1,S83_DCO
 SG_ LV_en_p_cldn_rf_time : 1|1@1+ (1,0) [0|1] ""  S91_FCCU1,S83_DCO
 SG_ LV_en_p_cldn_cp_spd : 2|1@1+ (1,0) [0|1] ""  S91_FCCU1,S83_DCO
 SG_ LV_P_CLDN_RF_Spd : 8|8@1+ (1,0) [0|100] "%"  S91_FCCU1,S83_DCO
 SG_ LV_P_CLDN_RF_Time : 16|16@1+ (0.1,0) [0|6553.5] "s"  S91_FCCU1,S83_DCO
 SG_ LV_P_CLDN_CP_Spd : 32|8@1+ (1,0) [0|100] "%"  S91_FCCU1,S83_DCO

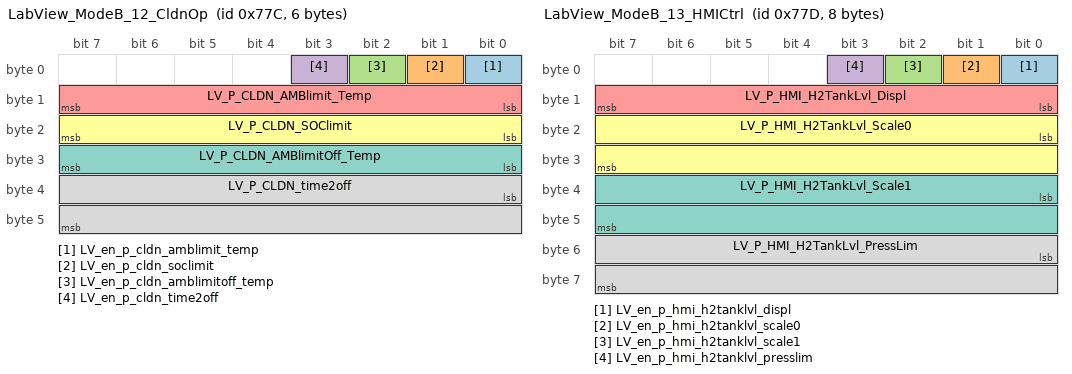
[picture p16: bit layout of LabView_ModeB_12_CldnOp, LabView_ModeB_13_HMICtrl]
BO_ 1916 LabView_ModeB_12_CldnOp: 6 LABVIEW
 SG_ LV_en_p_cldn_amblimit_temp : 0|1@1+ (1,0) [0|1] ""  S91_FCCU1,S83_DCO
 SG_ LV_en_p_cldn_soclimit : 1|1@1+ (1,0) [0|1] ""  S91_FCCU1,S83_DCO
 SG_ LV_en_p_cldn_amblimitoff_temp : 2|1@1+ (1,0) [0|1] ""  S91_FCCU1,S83_DCO
 SG_ LV_en_p_cldn_time2off : 3|1@1+ (1,0) [0|1] ""  S91_FCCU1,S83_DCO
 SG_ LV_P_CLDN_AMBlimit_Temp : 8|8@1+ (1,-40) [-40|215] "°C"  S91_FCCU1,S83_DCO
 SG_ LV_P_CLDN_SOClimit : 16|8@1+ (1,0) [0|100] "%"  S91_FCCU1,S83_DCO
 SG_ LV_P_CLDN_AMBlimitOff_Temp : 24|8@1+ (1,-40) [-40|215] "°C"  S91_FCCU1,S83_DCO
 SG_ LV_P_CLDN_time2off : 32|16@1+ (0.1,0) [0|6553.5] "s"  S91_FCCU1,S83_DCO

BO_ 1917 LabView_ModeB_13_HMICtrl: 8 LABVIEW
 SG_ LV_en_p_hmi_h2tanklvl_displ : 0|1@1+ (1,0) [0|1] ""  S91_FCCU1,S83_DCO
 SG_ LV_en_p_hmi_h2tanklvl_scale0 : 1|1@1+ (1,0) [0|1] ""  S91_FCCU1,S83_DCO
 SG_ LV_en_p_hmi_h2tanklvl_scale1 : 2|1@1+ (1,0) [0|1] ""  S91_FCCU1,S83_DCO
 SG_ LV_en_p_hmi_h2tanklvl_presslim : 3|1@1+ (1,0) [0|1] ""  S91_FCCU1,S83_DCO
 SG_ LV_P_HMI_H2TankLvl_Displ : 8|8@1+ (1,0) [0|100] "%"  S91_FCCU1,S83_DCO
 SG_ LV_P_HMI_H2TankLvl_Scale0 : 16|16@1+ (100,0) [0|100000] "kPa"  S91_FCCU1,S83_DCO
 SG_ LV_P_HMI_H2TankLvl_Scale1 : 32|16@1+ (100,0) [0|100000] "kPa"  S91_FCCU1,S83_DCO
 SG_ LV_P_HMI_H2TankLvl_PressLim : 48|16@1+ (100,0) [0|100000] "kPa"  S91_FCCU1,S83_DCO

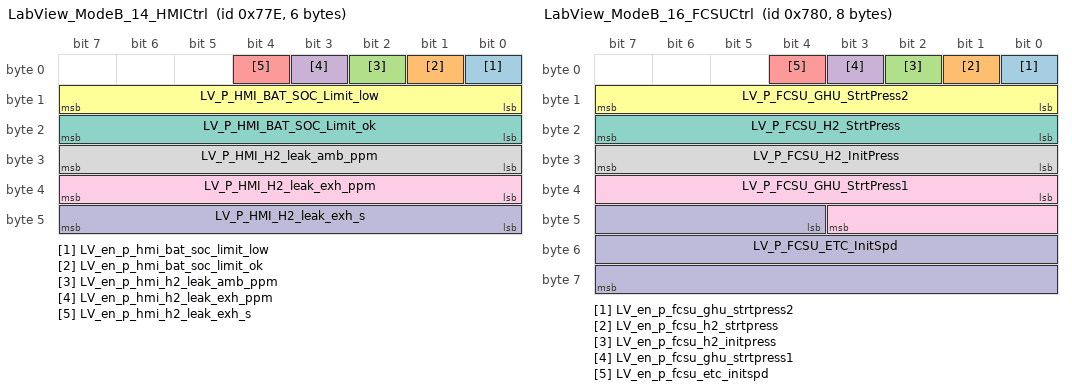
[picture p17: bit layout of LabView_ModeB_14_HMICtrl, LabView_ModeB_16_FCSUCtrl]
BO_ 1918 LabView_ModeB_14_HMICtrl: 6 LABVIEW
 SG_ LV_en_p_hmi_bat_soc_limit_low : 0|1@1+ (1,0) [0|1] ""  S91_FCCU1,S83_DCO
 SG_ LV_en_p_hmi_bat_soc_limit_ok : 1|1@1+ (1,0) [0|1] ""  S91_FCCU1,S83_DCO
 SG_ LV_en_p_hmi_h2_leak_amb_ppm : 2|1@1+ (1,0) [0|1] ""  S91_FCCU1,S83_DCO
 SG_ LV_en_p_hmi_h2_leak_exh_ppm : 3|1@1+ (1,0) [0|1] ""  S91_FCCU1,S83_DCO
 SG_ LV_en_p_hmi_h2_leak_exh_s : 4|1@1+ (1,0) [0|1] ""  S91_FCCU1,S83_DCO
 SG_ LV_P_HMI_BAT_SOC_Limit_low : 8|8@1+ (1,0) [0|100] "%"  S91_FCCU1,S83_DCO
 SG_ LV_P_HMI_BAT_SOC_Limit_ok : 16|8@1+ (1,0) [0|100] "%"  S91_FCCU1,S83_DCO
 SG_ LV_P_HMI_H2_leak_amb_ppm : 24|8@1+ (500,-5000) [-5000|123000] "ppm"  S91_FCCU1,S83_DCO
 SG_ LV_P_HMI_H2_leak_exh_ppm : 32|8@1+ (500,-5000) [-5000|123000] "ppm"  S91_FCCU1,S83_DCO
 SG_ LV_P_HMI_H2_leak_exh_s : 40|8@1+ (0.1,0) [0|25.5] "s"  S91_FCCU1,S83_DCO

BO_ 1919 LabView_ModeB_15_SysPwrDn: 5 LABVIEW
 SG_ LV_en_p_spdn_batlimit_curr : 0|1@1+ (1,0) [0|1] ""  S91_FCCU1,S83_DCO
 SG_ LV_en_p_spdn_batlimit_time : 1|1@1+ (1,0) [0|1] ""  S91_FCCU1,S83_DCO
 SG_ LV_P_SPDN_BATlimit_Curr : 8|16@1+ (0.1,-3276.8) [-3276.8|3276.7] "A"  S91_FCCU1,S83_DCO
 SG_ LV_P_SPDN_BATlimit_Time : 24|16@1+ (0.1,0) [0|6553.5] "s"  S91_FCCU1,S83_DCO

BO_ 1920 LabView_ModeB_16_FCSUCtrl: 8 LABVIEW
 SG_ LV_en_p_fcsu_ghu_strtpress2 : 0|1@1+ (1,0) [0|1] ""  S91_FCCU1,S83_DCO
 SG_ LV_en_p_fcsu_h2_strtpress : 1|1@1+ (1,0) [0|1] ""  S91_FCCU1,S83_DCO
 SG_ LV_en_p_fcsu_h2_initpress : 2|1@1+ (1,0) [0|1] ""  S91_FCCU1,S83_DCO
 SG_ LV_en_p_fcsu_ghu_strtpress1 : 3|1@1+ (1,0) [0|1] ""  S91_FCCU1,S83_DCO
 SG_ LV_en_p_fcsu_etc_initspd : 4|1@1+ (1,0) [0|1] ""  S91_FCCU1,S83_DCO
 SG_ LV_P_FCSU_GHU_StrtPress2 : 8|8@1+ (1,0) [0|255] "kPa"  S91_FCCU1,S83_DCO
 SG_ LV_P_FCSU_H2_StrtPress : 16|8@1+ (1,0) [0|255] "kPa"  S91_FCCU1,S83_DCO
 SG_ LV_P_FCSU_H2_InitPress : 24|8@1+ (1,0) [0|255] "kPa"  S91_FCCU1,S83_DCO
 SG_ LV_P_FCSU_GHU_StrtPress1 : 32|12@1+ (1,0) [0|2500] "kPa"  S91_FCCU1,S83_DCO
 SG_ LV_P_FCSU_ETC_InitSpd : 44|20@1+ (1,0) [0|1048575] "rpm"  S91_FCCU1,S83_DCO

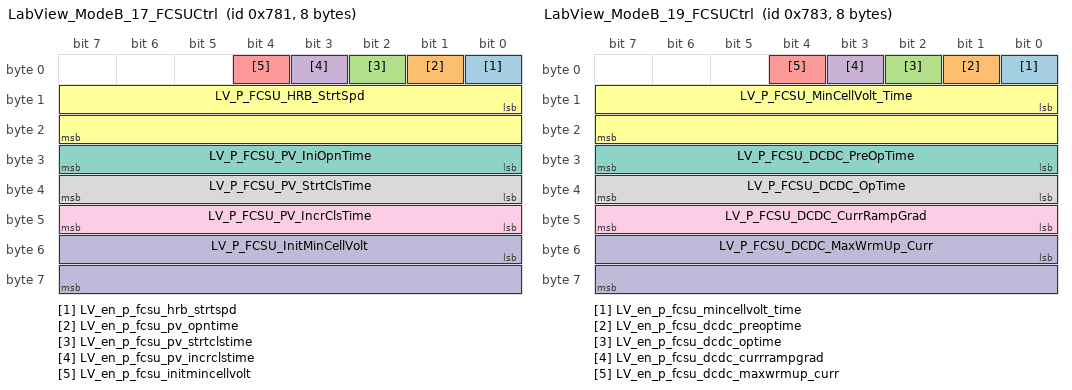
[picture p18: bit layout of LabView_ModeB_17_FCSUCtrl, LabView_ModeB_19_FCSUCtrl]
BO_ 1921 LabView_ModeB_17_FCSUCtrl: 8 LABVIEW
 SG_ LV_en_p_fcsu_hrb_strtspd : 0|1@1+ (1,0) [0|1] ""  S91_FCCU1,S83_DCO
 SG_ LV_en_p_fcsu_pv_opntime : 1|1@1+ (1,0) [0|1] ""  S91_FCCU1,S83_DCO
 SG_ LV_en_p_fcsu_pv_strtclstime : 2|1@1+ (1,0) [0|1] ""  S91_FCCU1,S83_DCO
 SG_ LV_en_p_fcsu_pv_incrclstime : 3|1@1+ (1,0) [0|1] ""  S91_FCCU1,S83_DCO
 SG_ LV_en_p_fcsu_initmincellvolt : 4|1@1+ (1,0) [0|1] ""  S91_FCCU1,S83_DCO
 SG_ LV_P_FCSU_HRB_StrtSpd : 8|16@1+ (1,0) [0|25000] "rpm"  S91_FCCU1,S83_DCO
 SG_ LV_P_FCSU_PV_IniOpnTime : 24|8@1+ (0.1,0) [0|25.5] "s"  S91_FCCU1,S83_DCO
 SG_ LV_P_FCSU_PV_StrtClsTime : 32|8@1+ (0.1,0) [0|25.5] "s"  S91_FCCU1,S83_DCO
 SG_ LV_P_FCSU_PV_IncrClsTime : 40|8@1+ (0.1,0) [0|25.5] "s"  S91_FCCU1,S83_DCO
 SG_ LV_P_FCSU_InitMinCellVolt : 48|16@1+ (0.001,0) [0|65.535] "V"  S91_FCCU1,S83_DCO

BO_ 1922 LabView_ModeB_18_FCSUCtrl: 8 LABVIEW
 SG_ LV_P_FCSU_H2_Press_P_Ctrl : 0|32@1+ (1E-006,0) [0|4294.967295] ""  S91_FCCU1,S83_DCO
 SG_ LV_P_FCSU_H2_Press_I_Ctrl : 32|32@1+ (1E-006,0) [0|4294.967295] ""  S91_FCCU1,S83_DCO

BO_ 1923 LabView_ModeB_19_FCSUCtrl: 8 LABVIEW
 SG_ LV_en_p_fcsu_mincellvolt_time : 0|1@1+ (1,0) [0|1] ""  S91_FCCU1,S83_DCO
 SG_ LV_en_p_fcsu_dcdc_preoptime : 1|1@1+ (1,0) [0|1] ""  S91_FCCU1,S83_DCO
 SG_ LV_en_p_fcsu_dcdc_optime : 2|1@1+ (1,0) [0|1] ""  S91_FCCU1,S83_DCO
 SG_ LV_en_p_fcsu_dcdc_currrampgrad : 3|1@1+ (1,0) [0|1] ""  S91_FCCU1,S83_DCO
 SG_ LV_en_p_fcsu_dcdc_maxwrmup_curr : 4|1@1+ (1,0) [0|1] ""  S91_FCCU1,S83_DCO
 SG_ LV_P_FCSU_MinCellVolt_Time : 8|16@1+ (0.1,0) [0|6553.5] "s"  S91_FCCU1,S83_DCO
 SG_ LV_P_FCSU_DCDC_PreOpTime : 24|8@1+ (0.1,0) [0|25.5] "s"  S91_FCCU1,S83_DCO
 SG_ LV_P_FCSU_DCDC_OpTime : 32|8@1+ (0.1,0) [0|25.5] "s"  S91_FCCU1,S83_DCO
 SG_ LV_P_FCSU_DCDC_CurrRampGrad : 40|8@1+ (0.1,0) [0|25.5] "A/s"  S91_FCCU1,S83_DCO
 SG_ LV_P_FCSU_DCDC_MaxWrmUp_Curr : 48|16@1+ (0.1,0) [0|6553.5] "A"  S91_FCCU1,S83_DCO

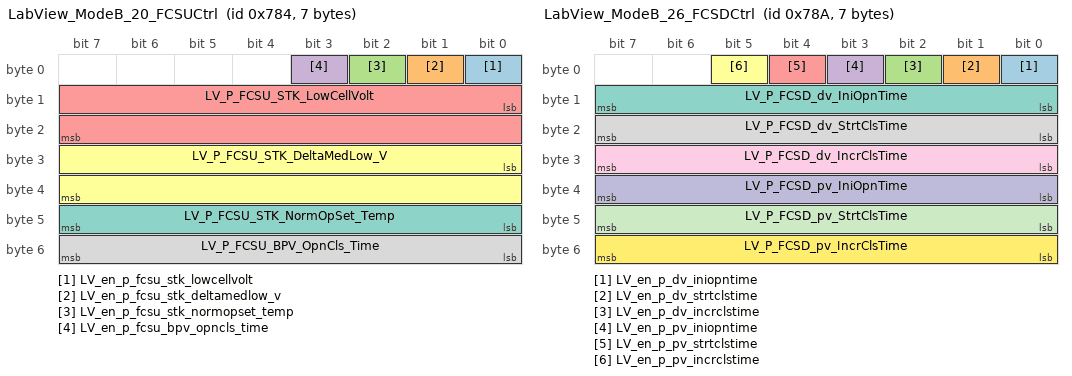
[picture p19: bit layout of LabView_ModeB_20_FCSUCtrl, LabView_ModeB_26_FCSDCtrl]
BO_ 1924 LabView_ModeB_20_FCSUCtrl: 7 LABVIEW
 SG_ LV_en_p_fcsu_stk_lowcellvolt : 0|1@1+ (1,0) [0|1] ""  S91_FCCU1,S83_DCO
 SG_ LV_en_p_fcsu_stk_deltamedlow_v : 1|1@1+ (1,0) [0|1] ""  S91_FCCU1,S83_DCO
 SG_ LV_en_p_fcsu_stk_normopset_temp : 2|1@1+ (1,0) [0|1] ""  S91_FCCU1,S83_DCO
 SG_ LV_en_p_fcsu_bpv_opncls_time : 3|1@1+ (1,0) [0|1] ""  S91_FCCU1,S83_DCO
 SG_ LV_P_FCSU_STK_LowCellVolt : 8|16@1+ (0.001,0) [0|65.535] "V"  S91_FCCU1,S83_DCO
 SG_ LV_P_FCSU_STK_DeltaMedLow_V : 24|16@1+ (0.001,0) [0|65.535] "V"  S91_FCCU1,S83_DCO
 SG_ LV_P_FCSU_STK_NormOpSet_Temp : 40|8@1+ (1,-40) [-40|215] "°C"  S91_FCCU1,S83_DCO
 SG_ LV_P_FCSU_BPV_OpnCls_Time : 48|8@1+ (0.1,0) [0|25.5] "s"  S91_FCCU1,S83_DCO

BO_ 1925 LabView_ModeB_21_FCSDCtrl: 8 LABVIEW
 SG_ LV_en_p_fcsd_h2end_press : 0|1@1+ (1,0) [0|1] ""  S91_FCCU1,S83_DCO
 SG_ LV_en_p_fcsd_hrbstp_spd : 1|1@1+ (1,0) [0|1] ""  S91_FCCU1,S83_DCO
 SG_ LV_en_p_fcsd_etc_initrng_spd : 2|1@1+ (1,0) [0|1] ""  S91_FCCU1,S83_DCO
 SG_ LV_P_FCSD_H2end_Press : 8|16@1+ (1,0) [0|400] "kPa"  S91_FCCU1,S83_DCO
 SG_ LV_P_FCSD_HRBstp_Spd : 24|16@1+ (1,0) [0|25000] "rpm"  S91_FCCU1,S83_DCO
 SG_ LV_P_FCSD_ETC_InitRng_Spd : 40|24@1+ (1,0) [0|16777215] "rpm"  S91_FCCU1,S83_DCO

BO_ 1926 LabView_ModeB_22_FCDU_FCA: 4 LABVIEW
 SG_ LV_en_p_fcdu_stk_curr_ramp_time : 0|1@1+ (1,0) [0|1] ""  S91_FCCU1,S83_DCO
 SG_ LV_en_p_fca_etc_preset_gradient : 1|1@1+ (1,0) [0|1] ""  S91_FCCU1,S83_DCO
 SG_ LV_P_FCDU_STK_Curr_Ramp_Time : 8|8@1+ (1,0) [0|255] "s"  S91_FCCU1,S83_DCO
 SG_ LV_P_FCA_ETC_Preset_Gradient : 16|16@1+ (1,0) [0|65535] "rpm/s"  S91_FCCU1,S83_DCO

BO_ 1927 LabView_ModeB_23_FCA_Press_PI: 8 LABVIEW
 SG_ LV_P_FCA_Press_P_Ctrl : 0|32@1+ (1E-006,0) [0|4294.967295] ""  S91_FCCU1,S83_DCO
 SG_ LV_P_FCA_Press_I_Ctrl : 32|32@1+ (1E-006,0) [0|4294.967295] ""  S91_FCCU1,S83_DCO

BO_ 1928 LabView_ModeB_24_FCA_D: 8 LABVIEW
 SG_ LV_P_FCA_Press_D_Ctrl : 0|32@1+ (1E-006,0) [0|4294.967295] ""  S91_FCCU1,S83_DCO
 SG_ LV_P_FCA_Speed_D_Ctrl : 32|32@1+ (1E-006,0) [0|4294.967295] ""  S91_FCCU1,S83_DCO

BO_ 1929 LabView_ModeB_25_FCA_Speed_PI: 8 LABVIEW
 SG_ LV_P_FCA_Speed_P_Ctrl : 0|32@1+ (1E-006,0) [0|4294.967295] ""  S91_FCCU1,S83_DCO
 SG_ LV_P_FCA_Speed_I_Ctrl : 32|32@1+ (1E-006,0) [0|4294.967295] ""  S91_FCCU1,S83_DCO

BO_ 1930 LabView_ModeB_26_FCSDCtrl: 7 LABVIEW
 SG_ LV_en_p_dv_iniopntime : 0|1@1+ (1,0) [0|1] ""  S91_FCCU1,S83_DCO
 SG_ LV_en_p_dv_strtclstime : 1|1@1+ (1,0) [0|1] ""  S91_FCCU1,S83_DCO
 SG_ LV_en_p_dv_incrclstime : 2|1@1+ (1,0) [0|1] ""  S91_FCCU1,S83_DCO
 SG_ LV_en_p_pv_iniopntime : 3|1@1+ (1,0) [0|1] ""  S91_FCCU1,S83_DCO
 SG_ LV_en_p_pv_strtclstime : 4|1@1+ (1,0) [0|1] ""  S91_FCCU1,S83_DCO
 SG_ LV_en_p_pv_incrclstime : 5|1@1+ (1,0) [0|1] ""  S91_FCCU1,S83_DCO
 SG_ LV_P_FCSD_dv_IniOpnTime : 8|8@1+ (0.1,0) [0|25.5] "s"  S91_FCCU1,S83_DCO
 SG_ LV_P_FCSD_dv_StrtClsTime : 16|8@1+ (0.1,0) [0|25.5] "s"  S91_FCCU1,S83_DCO
 SG_ LV_P_FCSD_dv_IncrClsTime : 24|8@1+ (0.1,0) [0|25.5] "s"  S91_FCCU1,S83_DCO
 SG_ LV_P_FCSD_pv_IniOpnTime : 32|8@1+ (0.1,0) [0|25.5] "s"  S91_FCCU1,S83_DCO
 SG_ LV_P_FCSD_pv_StrtClsTime : 40|8@1+ (0.1,0) [0|25.5] "s"  S91_FCCU1,S83_DCO
 SG_ LV_P_FCSD_pv_IncrClsTime : 48|8@1+ (0.1,0) [0|25.5] "s"  S91_FCCU1,S83_DCO

CM_ "FCCU for Globe";
CM_ SG_ 528 H42_HRB_a_FCCU_CRC "checksum for cyclic redundancy check";
CM_ SG_ 528 H42_HRB_a_FCCU_SQC "sequence counter ";
CM_ SG_ 528 H42_HRB_a_FCCU_Spd_Rq "rotational speed request";
CM_ SG_ 629 H42_HRB_s_ARB_ECU_Temp "ECU temperature";
CM_ SG_ 629 H42_HRB_s_ARB_Batt_Voltage "battery voltage";
CM_ SG_ 629 H42_HRB_s_ARB_SysState "system state of the ARB";
CM_ SG_ 629 H42_HRB_s_ARB_Spd "current rotational speed of the motor";
CM_ SG_ 629 H42_HRB_s_ARB_ECU_P_out "output power of the ECU";
CM_ SG_ 640 H42_HRB_s_ARB_ErrCRC "ARB error flags crc checksum ";
CM_ SG_ 640 H42_HRB_s_ARB_ErrSQC "ARB error flags sqc counter";
CM_ SG_ 640 H42_HRB_s_ARB_E2E_Err "error because of E2E communication";
CM_ SG_ 640 H42_HRB_s_ARB_SpdLimitRq_Err "error because of requested rotational motor speed";
CM_ SG_ 640 H42_HRB_s_ARB_SpdDiff_DrCnd "derating condition due to difference between actual and requested speed";
CM_ SG_ 640 H42_HRB_s_ARB_Batt_Vltg_Err "battery voltage error";
CM_ SG_ 640 H42_HRB_s_ARB_Blocked_Err "no reaction of pump";
CM_ SG_ 640 H42_HRB_s_ARB_Init_Err "initialization error";
CM_ SG_ 640 H42_HRB_s_ARB_ShortToBat_Err "short circuit to battery ";
CM_ SG_ 640 H42_HRB_s_ARB_ShortToGround_Err "short circuit to ground";
CM_ SG_ 640 H42_HRB_s_ARB_BrdgDrv_Err "bridge driver error
0 bit: output stage feedback error
1 bit: current sense amplifier error
2 bit: short circuit error
3 bit: shutdown error
4 bit: input pattern violation error
5 bit: ouput pin error
6 bit: external error
7 bit: internal error
";
CM_ SG_ 640 H42_HRB_s_BrdgDrv_VCC_UV_Err "bridge driver self test for VCC undervoltage ";
CM_ SG_ 640 H42_HRB_s_ARB_ECU_Temp_DrCnd "derating condition because of ECU temperature";
CM_ SG_ 640 H42_HRB_s_ARB_ECU_Temp_Err "ECU temperature error";
CM_ SG_ 640 H42_HRB_s_ARB_Mtr_Temp_DrCnd "derating condition because of motor temperature";
CM_ SG_ 640 H42_HRB_s_ARB_Mtr_Temp_Err "motor temperature error";
CM_ SG_ 640 H42_HRB_s_ARB_MtrNTCFlr_DrCnd "derating condition because of motor NTC failure";
CM_ SG_ 2147487746 H51_STK_a_CoreData_Freq_1002 "Übertragungsfrequenz der Core Daten zur FCCU";
CM_ SG_ 2147487746 H51_STK_a_StackSize_1002 "Anzahl der Zellen im Stack";
CM_ SG_ 2147487746 H51_STK_a_CAN_TerminatRes_1002 "Bestimmt, ob der Abschlusswiderstand aktivert werden soll oder nicht";
CM_ SG_ 2147487746 H51_STK_a_MasterNo_1002 "Gibt die Masternummer an, falls mehrere CVM Master vorhanden sind";
CM_ SG_ 2147487746 H51_STK_a_AmountOfModules_1002 "Anzahl der CVM Slave Module im Stack";
CM_ SG_ 2147487746 H51_STK_a_CellsPerModule_1002 "Anzahl der Zellen per CVM Modul (Master eine Zelle weniger)";
CM_ SG_ 2147487746 H51_STK_a_PosAtStack_1002 "Position am Stack (Master Position 1)";
CM_ SG_ 2147491840 H51_STK_s_Amount_Slave_Modu_2000 "Anzahl der CVM Slave Module im Stack";
CM_ SG_ 2147491843 H51_STK_s_CellNo_lowest_2003 "Zellennummer der Zelle mit niedrigster Spannung";
CM_ SG_ 2147491843 H51_STK_s_CellVolt_lowest_2003 "Niedrigste Spannung im Stack";
CM_ SG_ 2147491843 H51_STK_s_CellVolt_prev_lowest "Spannung der vorgehenden Nachbarzelle mit niedrigster Spannung";
CM_ SG_ 2147491843 H51_STK_s_CellVolt_follow_lowest "Spannung der nachfolgenden Nachbarzelle mit niedrigster Spannung";
CM_ SG_ 2147491843 H51_STK_s_CellNo_2ndlow_2003 "Zellennummer der Zelle mit 2. niedrigster Spannung";
CM_ SG_ 2147491843 H51_STK_s_CellVolt_prev_2ndlow "Spannung der vorgehenden Nachbarzelle mit 2. niedrigster Spannung";
CM_ SG_ 2147491843 H51_STK_s_CellVolt_follow_2ndlow "Spannung der nachfolgenden Nachbarzelle mit 2. niedrigster Spannung";
CM_ SG_ 2147491843 H51_STK_s_CellNo_highest_2003 "Zellennummer der Zelle mit der höchsten Spannung";
CM_ SG_ 2147491843 H51_STK_s_CellVolt_highest_2003 "Höchste Spannung im Stack";
CM_ SG_ 2147491843 H51_STK_s_TotalVoltage_2003 "Gesamtspannung aller Zellenspannungen am gesamten Stack";
CM_ SG_ 522 H62_HLD_s_1_H2_Concentration "Valid value is until 105,000ppm for the maximum concentration.";
CM_ SG_ 514 H62_HLD_s_2_H2_Concentration "Valid value is until 105,000ppm for the maximum concentration.";
CM_ SG_ 515 H63_HLD_s_2_H2_Concentration "Valid value is until 105,000ppm for the maximum concentration.";
CM_ SG_ 523 H63_HLD_s_1_H2_Concentration "Valid value is until 105,000ppm for the maximum concentration.";
BA_DEF_  "BusType" STRING ;
BA_DEF_  "DBName" STRING ;
BA_DEF_  "Manufacturer" STRING ;
BA_DEF_  "MultiplexExtEnabled" ENUM  "No","Yes";
BA_DEF_  "VersionDay" INT 1 31;
BA_DEF_  "VersionMonth" INT 1 12;
BA_DEF_  "VersionWeek" INT 1 52;
BA_DEF_  "VersionYear" INT 0 99;
BA_DEF_  "VersionNumber" INT 0 65535;
BA_DEF_  "Baudrate" INT 0 1000000;
BA_DEF_  "ProtocolType" STRING ;
BA_DEF_ BU_  "GenNodAutoGenDsp" ENUM  "No","Yes";
BA_DEF_ BU_  "GenNodAutoGenSnd" ENUM  "No","Yes";
BA_DEF_ BU_  "ECUVariantDefault" ENUM  "No","Yes";
BA_DEF_ BO_  "GenMsgCycleTime" INT 0 65535;
BA_DEF_ BO_  "GenMsgSendType" ENUM  "Cyclic","not_used","not_used","not_used","not_used","not_used","not_used","IfActive","NoMsgSendType";
BA_DEF_ SG_  "GenSigStartValue" INT -2147483648 2147483647;
BA_DEF_DEF_  "BusType" "";
BA_DEF_DEF_  "DBName" "";
BA_DEF_DEF_  "Manufacturer" "STAR Electronics GmbH";
BA_DEF_DEF_  "MultiplexExtEnabled" "Yes";
BA_DEF_DEF_  "VersionDay" 25;
BA_DEF_DEF_  "VersionMonth" 3;
BA_DEF_DEF_  "VersionWeek" 12;
BA_DEF_DEF_  "VersionYear" 22;
BA_DEF_DEF_  "VersionNumber" 1;
BA_DEF_DEF_  "Baudrate" 500000;
BA_DEF_DEF_  "ProtocolType" "CAN";
BA_DEF_DEF_  "GenNodAutoGenDsp" "Yes";
BA_DEF_DEF_  "GenNodAutoGenSnd" "Yes";
BA_DEF_DEF_  "ECUVariantDefault" "Yes";
BA_DEF_DEF_  "GenMsgCycleTime" 0;
BA_DEF_DEF_  "GenMsgSendType" "NoMsgSendType";
BA_DEF_DEF_  "GenSigStartValue" 0;
BA_ "BusType" "CAN";
BA_ "DBName" "Matrix_Globe";
BA_ "GenMsgCycleTime" BO_ 80 100;
BA_ "GenMsgSendType" BO_ 80 0;
BA_ "GenMsgCycleTime" BO_ 84 10000;
BA_ "GenMsgSendType" BO_ 84 0;
BA_ "GenMsgCycleTime" BO_ 92 1000;
BA_ "GenMsgSendType" BO_ 92 0;
BA_ "GenMsgCycleTime" BO_ 81 100;
BA_ "GenMsgSendType" BO_ 81 0;
BA_ "GenMsgCycleTime" BO_ 82 100;
BA_ "GenMsgSendType" BO_ 82 0;
BA_ "GenMsgCycleTime" BO_ 83 100;
BA_ "GenMsgSendType" BO_ 83 0;
BA_ "GenMsgCycleTime" BO_ 85 100;
BA_ "GenMsgSendType" BO_ 85 0;
BA_ "GenMsgCycleTime" BO_ 86 100;
BA_ "GenMsgSendType" BO_ 86 0;
BA_ "GenMsgCycleTime" BO_ 87 100;
BA_ "GenMsgSendType" BO_ 87 0;
BA_ "GenMsgCycleTime" BO_ 93 100;
BA_ "GenMsgSendType" BO_ 93 0;
BA_ "GenMsgCycleTime" BO_ 528 100;
BA_ "GenMsgSendType" BO_ 528 0;
BA_ "GenMsgCycleTime" BO_ 629 100;
BA_ "GenMsgSendType" BO_ 629 0;
BA_ "GenMsgCycleTime" BO_ 631 100;
BA_ "GenMsgSendType" BO_ 631 0;
BA_ "GenMsgCycleTime" BO_ 640 100;
BA_ "GenMsgSendType" BO_ 640 0;
BA_ "GenMsgCycleTime" BO_ 2147487746 10000;
BA_ "GenMsgSendType" BO_ 2147487746 0;
BA_ "GenMsgCycleTime" BO_ 515 100;
BA_ "GenMsgSendType" BO_ 515 0;
BA_ "GenMsgCycleTime" BO_ 0 100;
BA_ "GenMsgSendType" BO_ 0 0;
BA_ "GenMsgCycleTime" BO_ 513 100;
BA_ "GenMsgSendType" BO_ 513 0;
BA_ "GenMsgCycleTime" BO_ 769 100;
BA_ "GenMsgSendType" BO_ 769 0;
BA_ "GenMsgCycleTime" BO_ 34 100;
BA_ "GenMsgSendType" BO_ 34 0;
BA_ "GenMsgCycleTime" BO_ 1617 100;
BA_ "GenMsgSendType" BO_ 1617 0;
BA_ "GenMsgCycleTime" BO_ 1616 100;
BA_ "GenMsgSendType" BO_ 1616 0;
BA_ "GenMsgCycleTime" BO_ 1841 5000;
BA_ "GenMsgSendType" BO_ 1841 0;
BA_ "GenMsgCycleTime" BO_ 1842 5000;
BA_ "GenMsgSendType" BO_ 1842 0;
BA_ "GenMsgCycleTime" BO_ 1843 5000;
BA_ "GenMsgSendType" BO_ 1843 0;
BA_ "GenMsgCycleTime" BO_ 1844 5000;
BA_ "GenMsgSendType" BO_ 1844 0;
BA_ "GenMsgCycleTime" BO_ 1845 5000;
BA_ "GenMsgSendType" BO_ 1845 0;
BA_ "GenMsgCycleTime" BO_ 1846 5000;
BA_ "GenMsgSendType" BO_ 1846 0;
BA_ "GenMsgCycleTime" BO_ 1847 5000;
BA_ "GenMsgSendType" BO_ 1847 0;
BA_ "GenMsgCycleTime" BO_ 1848 5000;
BA_ "GenMsgSendType" BO_ 1848 0;
BA_ "GenMsgCycleTime" BO_ 1849 5000;
BA_ "GenMsgSendType" BO_ 1849 0;
BA_ "GenMsgCycleTime" BO_ 1850 5000;
BA_ "GenMsgSendType" BO_ 1850 0;
BA_ "GenMsgCycleTime" BO_ 1851 5000;
BA_ "GenMsgSendType" BO_ 1851 0;
BA_ "GenMsgCycleTime" BO_ 1852 5000;
BA_ "GenMsgSendType" BO_ 1852 0;
BA_ "GenMsgCycleTime" BO_ 1853 5000;
BA_ "GenMsgSendType" BO_ 1853 0;
BA_ "GenMsgCycleTime" BO_ 1854 5000;
BA_ "GenMsgSendType" BO_ 1854 0;
BA_ "GenMsgCycleTime" BO_ 1855 5000;
BA_ "GenMsgSendType" BO_ 1855 0;
BA_ "GenMsgCycleTime" BO_ 1856 5000;
BA_ "GenMsgSendType" BO_ 1856 0;
BA_ "GenMsgCycleTime" BO_ 1857 5000;
BA_ "GenMsgSendType" BO_ 1857 0;
BA_ "GenMsgCycleTime" BO_ 1858 5000;
BA_ "GenMsgSendType" BO_ 1858 0;
BA_ "GenMsgCycleTime" BO_ 1859 5000;
BA_ "GenMsgSendType" BO_ 1859 0;
BA_ "GenMsgCycleTime" BO_ 1860 5000;
BA_ "GenMsgSendType" BO_ 1860 0;
BA_ "GenMsgCycleTime" BO_ 1861 5000;
BA_ "GenMsgSendType" BO_ 1861 0;
BA_ "GenMsgCycleTime" BO_ 1552 100;
BA_ "GenMsgSendType" BO_ 1552 0;
BA_ "GenMsgCycleTime" BO_ 1553 100;
BA_ "GenMsgSendType" BO_ 1553 0;
BA_ "GenMsgCycleTime" BO_ 1576 100;
BA_ "GenMsgSendType" BO_ 1576 0;
BA_ "GenMsgCycleTime" BO_ 1568 100;
BA_ "GenMsgSendType" BO_ 1568 0;
BA_ "GenMsgCycleTime" BO_ 1584 100;
BA_ "GenMsgSendType" BO_ 1584 0;
BA_ "GenMsgCycleTime" BO_ 1585 100;
BA_ "GenMsgSendType" BO_ 1585 0;
BA_ "GenMsgCycleTime" BO_ 1600 10;
BA_ "GenMsgSendType" BO_ 1600 0;
BA_ "GenMsgCycleTime" BO_ 1601 10;
BA_ "GenMsgSendType" BO_ 1601 0;
BA_ "GenSigStartValue" SG_ 84 A03_ETC_a_CAN_Set_Timeout_Dur 1;
BA_ "GenSigStartValue" SG_ 84 A03_ETC_a_CAN_Set_ID_Offset 1;
BA_ "GenSigStartValue" SG_ 2147491843 H51_STK_s_AmountOfFrames_2003 1;
BA_ "GenSigStartValue" SG_ 2147491843 H51_STK_s_CellNo_lowest_2003 1;
BA_ "GenSigStartValue" SG_ 2147491843 H51_STK_s_CellNo_2ndlow_2003 1;
BA_ "GenSigStartValue" SG_ 2147491843 H51_STK_s_CellNo_highest_2003 1;
BA_ "GenSigStartValue" SG_ 2147491844 H51_STK_s_Datalength_2004 1;
BA_ "GenSigStartValue" SG_ 2147491845 H51_STK_s_AmountOfFrames_2005 1;
BA_ "GenSigStartValue" SG_ 0 E71_DC4880_a_NMT_Function 1;
BA_ "GenSigStartValue" SG_ 34 E74_ISO_a_Rq_D_IMC_R_ISOERR_THR 30;
BA_ "GenSigStartValue" SG_ 34 E74_ISO_a_Rq_D_IMC_R_ISOWRN_THR 40;
BA_ "GenSigStartValue" SG_ 34 E74_ISO_a_Rq_D_IMC_MEAN_FACTOR 1;
BA_ "GenSigStartValue" SG_ 35 E74_ISO_s_D_IMC_R_ISO_ERR_THR2 30;
BA_ "GenSigStartValue" SG_ 35 E74_ISO_s_D_IMC_R_ISO_WRN_THR2 40;
BA_ "GenSigStartValue" SG_ 35 E74_ISO_s_Rq_D_IMC_MEAN_FACTOR 1;
BA_ "GenSigStartValue" SG_ 35 E74_ISO_s_D_IMC_R_ISO_ERR_THR1 30;
BA_ "GenSigStartValue" SG_ 35 E74_ISO_s_D_IMC_R_ISO_WRN_THR1 40;
BA_ "GenSigStartValue" SG_ 35 E74_ISO_s_D_IMC_MEAN_FACTOR 1;
BA_ "GenSigStartValue" SG_ 1584 A14_HFM_s_Pressure 10;
BA_ "GenSigStartValue" SG_ 1600 A15_SI_s_Inlet_Pressure 20;
BA_ "GenSigStartValue" SG_ 1600 A17_SO_s_Outlet_Pressure 20;
VAL_ 80 A03_ETC_a_opCmd2 0 "HV Input" 1 "LV Input" ;
VAL_ 84 A03_ETC_a_CAN_Set_Baudrate 1 "20 kbps" 2 "50 kbps" 3 "100 kbps" 4 "125 kbps" 5 "250 kbps" 6 "500 kbps" 8 "1000 kbps" ;
VAL_ 90 A03_ETC_a_Info_Rq_Select 0 "Article Number" 1 "Article Revision" 2 "SerialNumber Part 1" 3 "SerialNumber Part 2" 4 "SerialNumber Part 3" 5 "Firmware Revision" 6 "Bootloader Version" 255 "Unknown" ;
VAL_ 92 A03_ETC_a_Diag_Rq_Select 0 "Gas Bearing Condition" ;
VAL_ 81 A03_ETC_s_Status1 0 "Initializing" 1 "Ready" 2 "Running" 3 "Degraded Operation" 4 "Blocked" ;
VAL_ 81 A03_ETC_s_Status2 0 "HV Input" 1 "LV Input" ;
VAL_ 91 A03_ETC_s_Info_Select 0 "Article Number" 1 "Article Revision" 2 "SerialNumber Part 1" 3 "SerialNumber Part 2" 4 "SerialNumber Part 3" 5 "Firmware Revision" 6 "Bootloader Version" 255 "Unknown" ;
VAL_ 93 A03_ETC_s_Diag_Select 0 "Gas Bearing Condition" ;
VAL_ 1281 C07_BAT_s_State 0 "STANDBY" 1 "SERVICE" 2 "DISCHARGE" 3 "CHARGE" 4 "ERROR" 5 "PRECHARGE_LOAD" 6 "PRECHARGE_CHARGER" 7 "REVERSE_CHARGE" ;
VAL_ 629 H42_HRB_s_ARB_SysState 5 "SYSSTATE_SHUT_DOWN" 4 "SYSSTATE_XCURESET" 3 "SYSSTATE_ERROR" 2 "SYSSTATE_RUN" 1 "SYSSTATE_IDLE" 0 "SYSSTATE_INIT" ;
VAL_ 640 H42_HRB_s_ARB_E2E_Err 7 "E2E_WRONGSEQUENCE" 6 "E2E_OKSOMELOST" 5 "E2E_REPEATED" 4 "E2E_INITIAL" 3 "E2E_SYNC" 2 "E2E_WRONGCRC" 1 "E2E_NONEWDATA" 0 "E2E_OK" ;
VAL_ 640 H42_HRB_s_ARB_SpdLimitRq_Err 1 "ERROR" 0 "NO_ERROR" ;
VAL_ 640 H42_HRB_s_ARB_SpdDiff_DrCnd 3 "SPD_DIFF_3" 2 "SPD_DIFF_2" 1 "SPD_DIFF_1" 0 "NO_SPD_DIFF" ;
VAL_ 640 H42_HRB_s_ARB_Batt_Vltg_Err 2 "OVERVOLTAGE" 1 "UNDERVOLTAGE" 0 "NO_ERROR" ;
VAL_ 640 H42_HRB_s_ARB_Blocked_Err 1 "ERROR" 0 "NO_ERROR" ;
VAL_ 640 H42_HRB_s_ARB_Init_Err 1 "ERROR" 0 "NO_ERROR" ;
VAL_ 640 H42_HRB_s_ARB_ShortToBat_Err 1 "ERROR" 0 "NO_ERROR" ;
VAL_ 640 H42_HRB_s_ARB_ShortToGround_Err 1 "ERROR" 0 "NO_ERROR" ;
VAL_ 640 H42_HRB_s_BrdgDrv_VCC_UV_Err 1 "ERROR" 0 "NO_ERROR" ;
VAL_ 640 H42_HRB_s_ARB_ECU_Temp_DrCnd 2 "TEMP_HIGH" 1 "NDEF" 0 "NO_DERATING_COND" ;
VAL_ 640 H42_HRB_s_ARB_ECU_Temp_Err 2 "TEMP_HIGH" 1 "TEMP_LOW" 0 "NO_ERROR" ;
VAL_ 640 H42_HRB_s_ARB_Mtr_Temp_DrCnd 2 "TEMP_HIGH" 1 "NDEF" 0 "NO_DERATING_COND" ;
VAL_ 640 H42_HRB_s_ARB_Mtr_Temp_Err 2 "TEMP_HIGH" 1 "TEMP_LOW" 0 "NO_ERROR" ;
VAL_ 640 H42_HRB_s_ARB_MtrNTCFlr_DrCnd 1 "NTC_FAILURE" 0 "NO_FAILURE" ;
VAL_ 2147487745 H51_STK_a_CellVoltage_1001 4 "Reference Voltages" 2 "Contact Voltage Master" 1 "Anforderung aktiv" 0 "Anforderung inaktiv" ;
VAL_ 2147487745 H51_STK_a_Logdata_1001 7 "Serial" 6 "Failure Data" 5 "Operation Data" 4 "Event Data" 3 "StackStatus Overview" 2 "Start/StopZyklen" 1 "Total operation time" 0 "Anforderung inaktiv" ;
VAL_ 2147487745 H51_STK_a_CoreData_1001 1 "Anforderung aktiv" 0 "Anforderung inaktiv" ;
VAL_ 2147487745 H51_STK_a_Firmware_1001 1 "Anforderung aktiv" 0 "Anforderung inaktiv" ;
VAL_ 2147487746 H51_STK_a_CAN_TerminatRes_1002 1 "Anforderung aktiv Wdst. AN" 0 "Anforderung inaktiv Wdst. AUS" ;
VAL_ 2147487746 H51_STK_a_MasterNo_1002 2 "Master 2" 1 "Master 1" 0 "OFF" ;
VAL_ 2147487747 H51_STK_a_Monitoring_Flag_1003 5 "StartUp Monitoring" 1 "Normal Monitoring" 0 "Stop Monitoring" ;
VAL_ 2147487748 H51_STK_a_Command_1004 128 "Speicher löschen" 1 "Slave Positionierung" ;
VAL_ 2147487750 H51_STK_a_FCCUResponse_1006 127 "Fehler" 120 "Warten" 64 "OK" ;
VAL_ 2147487755 H51_STK_a_Modul_100B 23 "Slave 23" 22 "Slave 22" 21 "Slave 21" 20 "Slave 20" 19 "Slave 19" 18 "Slave 18" 17 "Slave 17" 16 "Slave 16" 15 "Slave 15" 14 "Slave 14" 13 "Slave 13" 12 "Slave 12" 11 "Slave 11" 10 "Slave 10" 9 "Slave 9" 8 "Slave 8" 7 "Slave 7" 6 "Slave 6" 5 "Slave 5" 4 "Slave 4" 3 "Slave 3" 2 "Slave 2" 1 "Slave 1" 0 "Master" ;
VAL_ 2147491840 H51_STK_s_Stat_CVM_Mastermo_2000 254 "Undefined" 255 "Error" 240 "Stopped" 112 "Monitoring" 96 "Monitoring StartUp" 80 "Idle" 64 "AdressingSlaves" 48 "WaitForConfig" 32 "Configuration" 16 "Init" 0 "Startup" ;
VAL_ 2147491841 H51_STK_s_RequestBit_2001 1 "Anforderung aktiv" 0 "Anforderung inaktiv" ;
VAL_ 2147491845 H51_STK_s_FrameMux_2005 157 "Cell Voltages 501-503" 16 "Laenge + Zellspg. 1-4 (FirstF)" 156 "Cell Voltages 497-500" 155 "Cell Voltages 493-496" 154 "Cell Voltages 489-492" 153 "Cell Voltages 485-488" 152 "Cell Voltages 481-484" 151 "Cell Voltages 477-480" 150 "Cell Voltages 473-476" 149 "Cell Voltages 469-472" 148 "Cell Voltages 465-468" 147 "Cell Voltages 461-464" 146 "Cell Voltages 457-460" 145 "Cell Voltages 453-456" 144 "Cell Voltages 449-452" 143 "Cell Voltages 445-448" 142 "Cell Voltages 441-444" 141 "Cell Voltages 437-440" 140 "Cell Voltages 433-436" 139 "Cell Voltages 429-432" 138 "Cell Voltages 425-428" 137 "Cell Voltages 421-424" 136 "Cell Voltages 417-420" 135 "Cell Voltages 413-416" 134 "Cell Voltages 409-412" 133 "Cell Voltages 405-408" 132 "Cell Voltages 401-404" 131 "Cell Voltages 397-400" 130 "Cell Voltages 393-396" 129 "Cell Voltages 389-392" 128 "Cell Voltages 385-388" 127 "Cell Voltages 381-384" 126 "Cell Voltages 377-380" 125 "Cell Voltages 373-376" 124 "Cell Voltages 369-372" 123 "Cell Voltages 365-368" 122 "Cell Voltages 361-364" 121 "Cell Voltages 357-360" 120 "Cell Voltages 353-356" 119 "Cell Voltages 349-352" 118 "Cell Voltages 345-348" 117 "Cell Voltages 341-344" 116 "Cell Voltages 337-340" 115 "Cell Voltages 333-336" 114 "Cell Voltages 329-332" 113 "Cell Voltages 325-328" 112 "Cell Voltages 321-324" 111 "Cell Voltages 317-320" 110 "Cell Voltages 313-316" 109 "Cell Voltages 309-312" 108 "Cell Voltages 305-308" 107 "Cell Voltages 301-304" 106 "Cell Voltages 297-300" 105 "Cell Voltages 293-296" 104 "Cell Voltages 289-292" 103 "Cell Voltages 285-288" 102 "Cell Voltages 281-284" 101 "Cell Voltages 277-280" 100 "Cell Voltages 273-276" 99 "Cell Voltages 269-272" 98 "Cell Voltages 265-268" 97 "Cell Voltages 261-264" 96 "Cell Voltages 257-260" 95 "Cell Voltages 253-256" 94 "Cell Voltages 249-252" 93 "Cell Voltages 245-248" 92 "Cell Voltages 241-244" 91 "Cell Voltages 237-240" 90 "Cell Voltages 233-236" 89 "Cell Voltages 229-232" 88 "Cell Voltages 225-228" 87 "Cell Voltages 221-224" 86 "Cell Voltages 217-220" 85 "Cell Voltages 212-216" 84 "Cell Voltages 209-212" 83 "Cell Voltages 205-208" 82 "Cell Voltages 201-204" 81 "Cell Voltages 197-200" 80 "Cell Voltages 193-196" 79 "Cell Voltages 189-192" 78 "Cell Voltages 185-188" 77 "Cell Voltages 181-184" 76 "Cell Voltages 177-180" 75 "Cell Voltages 173-176" 74 "Cell Voltages 169-172" 73 "Cell Voltages 165-168" 72 "Cell Voltages 161-164" 71 "Cell Voltages 157-160" 70 "Cell Voltages 153-156" 69 "Cell Voltages 149-152" 68 "Cell Voltages 145-148" 67 "Cell Voltages 141-144" 66 "Cell Voltages 137-140" 65 "Cell Voltages 133-136" 64 "Cell Voltages 129-132" 63 "Cell Voltages 125-128" 62 "Cell Voltages 121-124" 61 "Cell Voltages 117-120" 60 "Cell Voltages 113-116" 59 "Cell Voltages 109-112 " 58 "Cell Voltages 105-108 " 57 "Cell Voltages 101-104 " 56 "Cell Voltages 97-100 " 55 "Cell Voltages 93-96 " 54 "Cell Voltages 89-92 " 53 "Cell Voltages 85-88 " 52 "Cell Voltages 81-84 " 51 "Cell Voltages 77-80 " 50 "Cell Voltages 73-76 " 49 "Cell Voltages 69-72 " 48 "Cell Voltages 65-68 " 47 "Cell Voltages 61-64 " 46 "Cell Voltages 57-60 " 45 "Cell Voltages 53-56 " 44 "Cell Voltages 49-52 " 43 "Cell Voltages 45-48 " 42 "Cell Voltages 41-44 " 41 "Cell Voltages 37-40 " 40 "Cell Voltages 33-36 " 39 "Cell Voltages 29-32" 38 "Cell Voltages 25-28" 37 "Cell Voltages 21-24 " 36 "Cell Voltages 17-20 " 35 "Cell Voltages 13-16" 34 "Cell Voltages 9-12 " 33 "Cell Voltages 5-8 " ;
VAL_ 2147491855 H51_STK_s_CVMResponse_200F 127 "Fehler" 120 "Warten" 64 "OK" ;
VAL_ 0 E71_DC4880_a_NMT_Function 1 "Enter Operational" 2 "Enter Stop" 128 "Enter Pre-Operational" 129 "Reset Node" 130 "Reset Communication" ;
VAL_ 1793 E71_DC4880_s_NMT_State 0 "BOOT UP" 4 "STOPPED" 5 "OPERATIONAL" 127 "PRE-OPERATIONAL" ;
VAL_ 34 E74_ISO_a_CMD_Rq 33 "S_IMC_CTL_SELFTEST" 200 "S_VIFC_CTL_IMC_RESET" 202 "S_VIFC_CTL_LOCK" 203 "S_VIFC_CTL_MEASUREMENT" 40 "S_IMC_SET_R_ISO_ERR_THR" 41 "S_IMC_SET_R_ISO_WRN_THR" 43 "S_IMC_SET_MEAN_FACTOR" 210 "S_VIFC_SET_HV_RELAIS" 0 "S_VIFC_DUMMY" 55 "S_IMC_GET_STATUS" 53 "S_IMC_GET_R_ISO" 50 "S_IMC_GET_R_ISO_ERR_THR" 57 "S_IMC_GET_R_ISO_WRN_THR" 60 "S_IMC_GET_MEAN_FACTOR" 54 "S_IMC_GET_HV_1" 58 "S_IMC_GET_HV_2" 51 "S_IMC_GET_VERSION" 220 "S_VIFC_GET_STATUS" 221 "S_VIFC_GET_HV_RELAIS" 222 "S_VIFC_GET_VERSION" 90 "S_IMC_GET_TEST_CNT" 61 "S_IMC_GET_MANUFACTURER" 255 "ERROR" ;
VAL_ 34 E74_ISO_a_Rq_D_IMC_SELFTEST_SCR 0 "Keine Maßnahme" 1 "OverAll Szenario" 2 "ParameterConfig-Szenario" ;
VAL_ 34 E74_ISO_a_Rq_D_IMC_VERSION_IDX 0 "IMC Bootloader" 1 "IMC Firmware" 2 "IMC Firmware ID" 3 "IMC Firmware Hash" ;
VAL_ 34 E74_ISO_a_Rq_D_VIFC_LOCK_MODE 0 "Entriegelt" 1 "Verriegelt" 100 "unbekannt" ;
VAL_ 34 E74_ISO_a_Rq_D_VIFC_LOCK_PWD 0 "Entriegeln" 65535 "Verriegeln" ;
VAL_ 34 E74_ISO_a_Rq_D_VIFC_HV_REL_CHG 0 "HV_1_NEG-Relais" 1 "HV_1_POS-Relais" 100 "unbekannt" ;
VAL_ 34 E74_ISO_a_Rq_D_VIFC_RELAIS_STAT 0 "Offen" 1 "Geschlossen" 100 "unbekannt" ;
VAL_ 34 E74_ISO_a_Rq_D_VIFC_HV_RELAIS 0 "HV_1_NEG-Relais" 1 "HV_1_POS-Relais" 100 "unbekannt" ;
VAL_ 34 E74_ISO_a_Rq_D_VIFC_VERSION_IDX 0 "VIFC-Bootloader" 1 "VIFC-Firmware" 100 "unbekannt" ;
VAL_ 35 E74_ISO_s_CMD_Resp 33 "S_IMC_CTL_SELFTEST" 200 "S_VIFC_CTL_IMC_RESET" 202 "S_VIFC_CTL_LOCK" 203 "S_VIFC_CTL_MEASUREMENT" 40 "S_IMC_SET_R_ISO_ERR_THR" 41 "S_IMC_SET_R_ISO_WRN_THR" 43 "S_IMC_SET_MEAN_FACTOR" 210 "S_VIFC_SET_HV_RELAIS" 0 "S_VIFC_DUMMY" 55 "S_IMC_GET_STATUS" 53 "S_IMC_GET_R_ISO" 50 "S_IMC_GET_R_ISO_ERR_THR" 57 "S_IMC_GET_R_ISO_WRN_THR" 60 "S_IMC_GET_MEAN_FACTOR" 54 "S_IMC_GET_HV_1" 58 "S_IMC_GET_HV_2" 51 "S_IMC_GET_VERSION" 220 "S_VIFC_GET_STATUS" 221 "S_VIFC_GET_HV_RELAIS" 222 "S_VIFC_GET_VERSION" 90 "S_IMC_GET_TEST_CNT" 61 "S_IMC_GET_MANUFACTURER" 255 "ERROR" ;
VAL_ 35 E74_ISO_s_D_IMC_SELFTEST_SCR 0 "Keine Maßnahme" 1 "OverAll Szenario" 2 "ParameterConfig-Szenario" ;
VAL_ 35 E74_ISO_s_D_IMC_VERSION_INDEX 0 "IMC Bootloader" 1 "IMC Firmware" 2 "IMC Firmware ID" 3 "IMC Firmware Hash" ;
VAL_ 35 E74_ISO_s_D_IMC_R_ISO_BIAS 0 "nicht bekannt" 1 "Fehler an HV1_NEG" 2 "Fehler an HV1_POS" ;
VAL_ 35 E74_ISO_s_D_VIFC_LOCK_MODE 0 "Entriegelt" 1 "Verriegelt" 100 "unbekannt" ;
VAL_ 35 E74_ISO_s_D_VIFC_HV_RELAIS_CHG 0 "HV_1_NEG-Relais" 1 "HV_1_POS-Relais" 100 "unbekannt" ;
VAL_ 35 E74_ISO_s_D_VIFC_HV_RELAIS_STAT 0 "Offen" 1 "Geschlossen" 100 "unbekannt" ;
VAL_ 35 E74_ISO_s_D_VIFC_HV_RELAIS 0 "HV_1_NEG-Relais" 1 "HV_1_POS-Relais" 100 "unbekannt" ;
VAL_ 35 E74_ISO_s_D_VIFC_HV_RELAIS_ACT 0 "Offen" 1 "Geschlossen" 100 "unbekannt" ;
VAL_ 35 E74_ISO_s_D_VIFC_VERSION_INDEX 0 "VIFC-Bootloader" 1 "VIFC-Firmware" 100 "unbekannt" ;
VAL_ 35 E74_ISO_s_D_VIFC_IMC_ALIVE 0 "In Betrieb" 1 "Fehler" 2 "Leistungsfehler" 100 "unbekannt" ;
VAL_ 35 E74_ISO_s_D_IMD_ERROR_CODE 32 "Timeout 10 ms" 33 "Checksummen-Fehler" 34 "Ungültiger Parameter" 35 "Unbekannter Befehl" 36 "Fehler im EEPROM-Zugang" 37 "Wdh oder fehlender Datenframe" 1000 "Befehl gesperrt" 1001 "Warteschlange voll" 1002 "Befehl nicht verfügbar" 1032 "Timeout 10 ms" 1033 "Checksummen-Fehler" 1034 "Ungültiger Parameter" 1035 "Unbekannter Befehl" 1037 "Wdh oder fehlender Datenframe" 1038 "Keine Antwort" 1039 "Kommunikationsfehler" 1040 "Ungültiger IMC-Antwortbefehl" ;
VAL_ 1617 S80_BP_a_Taster_Start_LED_On 0 "OFF" 1 "BLINK_SLOW" 2 "BLINK_FAST" 3 "ON" ;
VAL_ 1617 S80_BP_a_Taster_Stop_LED_On 0 "OFF" 1 "BLINK_SLOW" 2 "BLINK_FAST" 3 "ON" ;
VAL_ 1617 S80_BP_a_H2_Water_Ctrl_LED_On 0 "OFF" 1 "BLINK_SLOW" 2 "BLINK_FAST" 3 "ON" ;
VAL_ 1617 S80_BP_a_Bat_Control_LED_On 0 "OFF" 1 "BLINK_SLOW" 2 "BLINK_FAST" 3 "ON" ;
VAL_ 1617 S80_BP_a_Service_LED_On 0 "OFF" 1 "BLINK_SLOW" 2 "BLINK_FAST" 3 "ON" ;
VAL_ 1617 S80_BP_a_Leakage_LED_On 0 "OFF" 1 "BLINK_SLOW" 2 "BLINK_FAST" 3 "ON" ;
VAL_ 1617 S80_BP_a_WiFi_Status 0 "OFF" 1 "BLINK_SLOW" 2 "BLINK_FAST" 3 "ON" ;
VAL_ 1617 S80_BP_a_Beep_On 0 "OFF" 1 "BLINK_SLOW" 2 "BLINK_FAST" 3 "ON" ;
VAL_ 1841 S91_LV_Testmode 0 "Normal Operation" 1 "LabView Test A" 2 "LabView Test B" 3 "Normal Operation" ;
VAL_ 2000 S91_SYS_MasterCtrl_State 0 "WAIT_START" 1 "FAIL_SAFE_POWER_UP" 2 "SYSTEM_POWER_UP" 3 "OPERATIONAL" 4 "SYSTEM_POWER_DOWN" ;
VAL_ 2000 S91_SYS_PowerCtrl_State 0 "BATTERY_ONLY" 1 "FUELCELL_HIGH" 2 "FUELCELL_LOW" 3 "SHUTDOWN" ;
VAL_ 2000 S91_SYS_FCCtrl_State 0 "OFF" 1 "STARTING" 2 "OPERATIONAL" 3 "STOPING" ;
VAL_ 2000 S91_SYS_FCShutdown_Mode 0 "NONE" 1 "SLOW" 2 "HARD" ;
VAL_ 2000 S91_SYS_Labview_Mode 0 "Normal Operation" 1 "LabView Test A" 2 "LabView Test B" 3 "Normal Operation" ;
VAL_ 2000 S91_SYS_Error_Level 0 "No Error" 1 "Level 1" 2 "Level 2" 3 "Level 3" ;
VAL_ 2000 S91_SYS_Error_Code 0 "No Error" 1 "C01_RF Diagnosis Pin" 2 "A03_ETC Degraded or Blocked" 3 "A03_ETC <0rpm or >280.000rpm" 4 "A03_ETC Warning Code" 5 "A03_ETC Error Code" 6 "A03_ETC Power >3500W" 7 "A03_ETC ConverterTemp >100°C" 8 "A03_ETC PT100Temp >100°C" 9 "A03_ETC THCTemp >100°C" 10 "A03_ETC GasBearing <50" 11 "C04_DI Temp >80°C" 12 "C06_ET Full" 13 "C07_B Error" 14 "C07_B BoardTemp <0°C or >45°C" 15 "C07_B Current >3200A" 16 "C07_B Voltage <70V or" 17 "C07_B MaxCellTemp <0°C or >45°C" 18 "C07_B MinCellTemp <0°C or >45°C" 19 "C07_B SOC <10%" 20 "C07_B SOH <90%" 21 "C07_B PreWarn SOC" 22 "C07_B PreWarn Curr High" 23 "C07_B PreWarn Volt High/Low" 24 "C07_B PreWarn Temp" 25 "C07_B BatError Intern" 26 "C07_B BatError DataValid" 27 "C07_B BatError Volt" 28 "C07_B BatError Temp" 29 "C07_B CECUError Intern" 30 "C07_B CECUError Current" 31 "C07_B CECUError Volt" 32 "C07_B CECUError Temp" 33 "C07_B CECUError Comm" 34 "C07_B CECUError Supply" 35 "C07_B CECUError Reserved" 36 "C07_B CECUError Service" 37 "C08_AMB Temp <0°C or >45°C" 38 "C08_AMB Press <90kPa or >110kPa" 39 "A11_HBV Position" 40 "A12_SIV Position" 41 "A13_SOV Position" 42 "A14_HFM Temp >50°C" 43 "H31_OTV Press <20bar or >350bar" 44 "H31_OTV Temp >100°C" 45 "H36_GHU StartupPress1 Timeout" 46 "H40_GHU StartupPress2 Timeout" 47 "H42_HRB SysState Error" 48 "H42_HRB MtrNTCFlr_DrCnd" 49 "H42_HRB Mtr_Temp_Err" 50 "H42_HRB Mtr_Temp_DrCnd" 51 "H42_HRB BrdgDrv_VCC_UV_Err" 52 "H42_HRB ShortToGround_Err" 53 "H42_HRB ShortToBat_Err" 54 "H42_HRB E2E_Err" 55 "H42_HRB SpdLimitRq_Err" 56 "H42_HRB Blocked_Err" 57 "H42_HRB Batt_Vltg_Err" 58 "H42_HRB ECU_Temp_Err" 59 "H42_HRB ECU_Temp_DrCnd" 60 "H42_HRB KNF Error" 61 "H45_WT Tank Full" 62 "H51_STK LowCellVolt <200mV" 63 "H51_STK TotalVolt <31V or >75V" 64 "H51_STK Startup CellVolt Timeout" 65 "H51_STK Shutdown CellVolt Timeout" 66 "H53_PV Startup Timeout" 67 "C54_SI Temp >80°C" 68 "H55_SI Press >2,5bar" 69 "H62_HLD ErrorCode = 3" 70 "H62_HLD Concentration >122.500ppm" 71 "H63_HLD ErrorCode = 3" 72 "H63_HLD Concentration >122.500ppm" 73 "E71_DCDC Precharge" 74 "E71_DCDC Operational" 75 "E74_ISO R <0kOhm" 76 "E74_ISO IsoError" 77 "E74_ISO Err Chassis" 78 "E74_ISO Sysstoer" 79 "E74_ISO IsoWarn" ;
VAL_ 1552 C01_RF_s_Status 0 "Radiator OK" 1 "Radiator ERROR" ;
VAL_ 1576 A11_HBV_a_Mode_Set 0 "OFF" 1 "ON" 2 "TeachIn" 3 "Error" ;
VAL_ 1576 A12_SIV_a_Mode_Set 0 "OFF" 1 "ON" 2 "TeachIn" 3 "Error" ;
VAL_ 1576 A13_SOV_a_Mode_Set 0 "OFF" 1 "ON" 2 "TeachIn" 3 "Error" ;
VAL_ 1568 A11_HBV_s_Mode_Act 0 "OFF" 1 "ON" 2 "TeachIn" 3 "Error" ;
VAL_ 1568 A12_SIV_s_Mode_Act 0 "OFF" 1 "ON" 2 "TeachIn" 3 "Error" ;
VAL_ 1568 A13_SOV_s_Mode_Act 0 "OFF" 1 "ON" 2 "TeachIn" 3 "Error" ;
VAL_ 1872 LV_Testmode_Select 0 "Normal Operation" 1 "LabView Test A" 2 "LabView Test B" 3 "Normal Operation" ;
VAL_ 1892 LV_H_51_CVM_Monitoring_Flag 5 "StartUp Monitoring" 1 "Normal Monitoring" 0 "Stop Monitoring" ;

SG_MUL_VAL_ 2147491844 H51_STK_s_Datalength_2004 H51_STK_s_Mux_ID_2004 16-31;
SG_MUL_VAL_ 2147491844 H51_STK_s_EventNo_2004 H51_STK_s_Mux_ID_2004 16-31;
SG_MUL_VAL_ 2147491844 H51_STK_s_ZellNo_2004 H51_STK_s_Mux_ID_2004 16-31;
SG_MUL_VAL_ 2147491844 H51_STK_s_CellVoltage_ui16L_2004 H51_STK_s_Mux_ID_2004 16-31;
SG_MUL_VAL_ 2147491846 H51_STK_s_AmountofContactFailure H51_STK_s_FrameMux_2006 2-16;
SG_MUL_VAL_ 2147491846 H51_STK_s_CellContactNr1_2006 H51_STK_s_FrameMux_2006 2-16;
SG_MUL_VAL_ 2147491846 H51_STK_s_CellContactNr2_2006 H51_STK_s_FrameMux_2006 2-16;
SG_MUL_VAL_ 2147491846 H51_STK_s_CellContactNr3_2006 H51_STK_s_FrameMux_2006 2-16;
